VERSION "HNNBNNNYNNNNNNNNNNNNNNNNNNNNNNNNNNNNNNNNNN/4/%%%/4/'%**4NNN///"

NS_ :

BS_:

BU_: BAP_Tester BedienDisp_mi BedienDisp_vo_mi CDI ConMod_CD DashCAM Gateway_Max ICC_IO_Node LSH OCU RDK_RS3 Sound_MIB_ab_Gen3 STH ZR_MIB_EINSTIEG_ab_Gen3 ZR_MIB_OPTION_ab_Gen3 ZR_MIB_TOP_ab_Gen3

BO_ 1529 RDK_02: 8 RDK_RS3
 SG_ RDK_FMVSS138_Lampe : 12|1@1+ (1.0,0.0) [0.0|1] ""  Gateway_Max,OCU
 SG_ RDK_FMVSS138_MIL : 13|1@1+ (1.0,0.0) [0.0|1] ""  Gateway_Max,OCU
 SG_ RDK_Kalibrierung : 14|1@1+ (1.0,0.0) [0.0|1] ""  Gateway_Max,OCU
 SG_ RDK_Reifendruck_Lampe : 15|1@1+ (1.0,0.0) [0.0|1] ""  Gateway_Max
 SG_ RDK_Warnungen_02 : 16|5@1+ (1.0,0.0) [0.0|31] ""  Gateway_Max
 SG_ RDK_angelernt : 22|1@1+ (1.0,0.0) [0.0|1] ""  Gateway_Max
 SG_ RDK_Reifentemperatur_Lampe : 23|1@1+ (1.0,0.0) [0.0|1] ""  Gateway_Max
 SG_ RDK_RS_aktiv : 24|1@1+ (1.0,0.0) [0.0|1] ""  Gateway_Max
 SG_ RDK_Text_7 : 25|1@1+ (1.0,0.0) [0.0|1] ""  Gateway_Max
 SG_ RDK_W_1_Reifen_HL : 56|1@1+ (1.0,0.0) [0.0|1] ""  Gateway_Max
 SG_ RDK_W_1_Reifen_HR : 57|1@1+ (1.0,0.0) [0.0|1] ""  Gateway_Max
 SG_ RDK_W_1_Reifen_VL : 58|1@1+ (1.0,0.0) [0.0|1] ""  Gateway_Max
 SG_ RDK_W_1_Reifen_VR : 59|1@1+ (1.0,0.0) [0.0|1] ""  Gateway_Max
 SG_ RDK_W_2_Reifen_HL : 60|1@1+ (1.0,0.0) [0.0|1] ""  Gateway_Max
 SG_ RDK_W_2_Reifen_HR : 61|1@1+ (1.0,0.0) [0.0|1] ""  Gateway_Max
 SG_ RDK_W_2_Reifen_VL : 62|1@1+ (1.0,0.0) [0.0|1] ""  Gateway_Max
 SG_ RDK_W_2_Reifen_VR : 63|1@1+ (1.0,0.0) [0.0|1] ""  Gateway_Max

BO_ 1711 Rear_View_01: 8 Gateway_Max
 SG_ RV_Video_on : 0|1@1+ (1.0,0.0) [0.0|1] ""  ZR_MIB_EINSTIEG_ab_Gen3,ZR_MIB_TOP_ab_Gen3
 SG_ RV_Dark_Screen : 1|1@1+ (1.0,0.0) [0.0|1] ""  Vector__XXX
 SG_ RV_HMI_Mode : 2|2@1+ (1.0,0.0) [0.0|3] ""  Vector__XXX
 SG_ RV_GL_side : 4|2@1+ (1.0,0.0) [0.0|3] ""  Vector__XXX
 SG_ RV_System_aktiv : 6|1@1+ (1.0,0.0) [0.0|1] ""  Vector__XXX
 SG_ RV_Reinigung_Anf : 7|1@1+ (1.0,0.0) [0.0|1] ""  Vector__XXX
 SG_ RV_Settings_enabled : 8|1@1+ (1.0,0.0) [0.0|1] ""  Vector__XXX
 SG_ RV_Menu_Item : 9|2@1+ (1.0,0.0) [0.0|3] ""  Vector__XXX
 SG_ SV_Video_on : 11|1@1+ (1.0,0.0) [0.0|1] ""  Vector__XXX
 SG_ RV_Calib_Fehler : 12|1@1+ (1.0,0.0) [0.0|1] ""  Vector__XXX
 SG_ RV_GL_Trailer_connect : 13|1@1+ (1.0,0.0) [0.0|1] ""  Vector__XXX
 SG_ RV_GL_Trunk_open : 14|1@1+ (1.0,0.0) [0.0|1] ""  Vector__XXX
 SG_ RV_GL_LWS_Fehler : 15|1@1+ (1.0,0.0) [0.0|1] ""  Vector__XXX
 SG_ RV_Helligkeit : 16|7@1+ (1,0) [0|100] "Unit_PerCent"  Vector__XXX
 SG_ ZFAS_Umfeldbeleuchtung_Anf : 23|1@1+ (1.0,0.0) [0.0|1] ""  Vector__XXX
 SG_ RV_Kontrast : 24|7@1+ (1,0) [0|100] "Unit_PerCent"  Vector__XXX
 SG_ RV_Farbe : 32|7@1+ (1,0) [0|100] "Unit_PerCent"  Vector__XXX

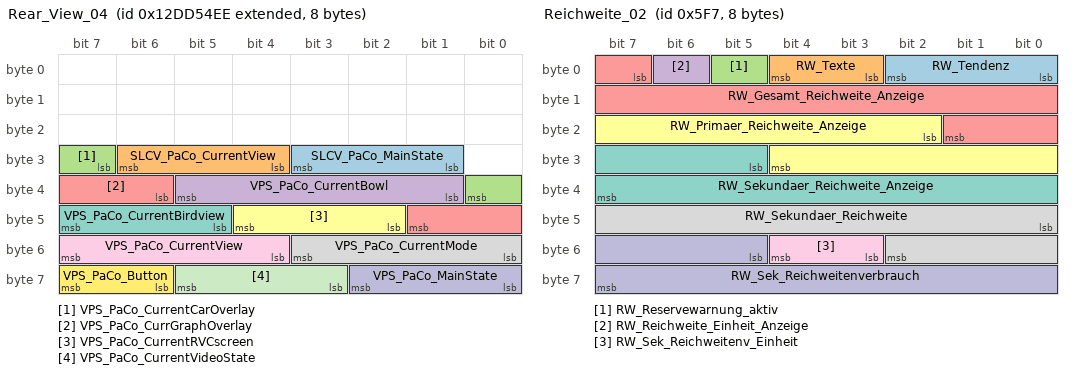
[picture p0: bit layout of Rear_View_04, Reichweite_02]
BO_ 2463978734 Rear_View_04: 8 Gateway_Max
 SG_ SLCV_PaCo_MainState : 25|3@1+ (1.0,0.0) [0.0|7] ""  Vector__XXX
 SG_ SLCV_PaCo_CurrentView : 28|3@1+ (1.0,0.0) [0.0|7] ""  Vector__XXX
 SG_ VPS_PaCo_CurrentCarOverlay : 31|2@1+ (1.0,0.0) [0.0|3] ""  Vector__XXX
 SG_ VPS_PaCo_CurrentBowl : 33|5@1+ (1.0,0.0) [0.0|31] ""  Vector__XXX
 SG_ VPS_PaCo_CurrGraphOverlay : 38|4@1+ (1.0,0.0) [0.0|15] ""  Vector__XXX
 SG_ VPS_PaCo_CurrentRVCscreen : 42|3@1+ (1.0,0.0) [0.0|7] ""  Vector__XXX
 SG_ VPS_PaCo_CurrentBirdview : 45|3@1+ (1.0,0.0) [0.0|7] ""  Vector__XXX
 SG_ VPS_PaCo_CurrentMode : 48|4@1+ (1.0,0.0) [0.0|15] ""  Vector__XXX
 SG_ VPS_PaCo_CurrentView : 52|4@1+ (1.0,0.0) [0.0|15] ""  Vector__XXX
 SG_ VPS_PaCo_MainState : 56|3@1+ (1.0,0.0) [0.0|7] ""  Vector__XXX
 SG_ VPS_PaCo_CurrentVideoState : 59|3@1+ (1.0,0.0) [0.0|7] ""  ZR_MIB_EINSTIEG_ab_Gen3,ZR_MIB_OPTION_ab_Gen3,ZR_MIB_TOP_ab_Gen3
 SG_ VPS_PaCo_Button : 62|2@1+ (1.0,0.0) [0.0|3] ""  Vector__XXX

BO_ 1527 Reichweite_02: 8 Gateway_Max
 SG_ RW_Tendenz : 0|3@1+ (1.0,0.0) [0.0|7] ""  Vector__XXX
 SG_ RW_Texte : 3|2@1+ (1.0,0.0) [0.0|3] ""  OCU
 SG_ RW_Reservewarnung_aktiv : 5|1@1+ (1.0,0.0) [0.0|1] ""  OCU
 SG_ RW_Reichweite_Einheit_Anzeige : 6|1@1+ (1.0,0.0) [0.0|1] ""  OCU
 SG_ RW_Gesamt_Reichweite_Anzeige : 7|11@1+ (1,0) [0|2044] "Unit_None"  OCU
 SG_ RW_Primaer_Reichweite_Anzeige : 18|11@1+ (1,0) [0|2044] "Unit_None"  OCU
 SG_ RW_Sekundaer_Reichweite_Anzeige : 29|11@1+ (1,0) [0|2044] "Unit_None"  OCU
 SG_ RW_Sekundaer_Reichweite : 40|11@1+ (1,0) [0|2044] "Unit_KiloMeter"  OCU
 SG_ RW_Sek_Reichweitenv_Einheit : 51|2@1+ (1.0,0.0) [0.0|3] ""  OCU
 SG_ RW_Sek_Reichweitenverbrauch : 53|11@1+ (0.1,0) [0.0|204.4] "Unit_None"  OCU

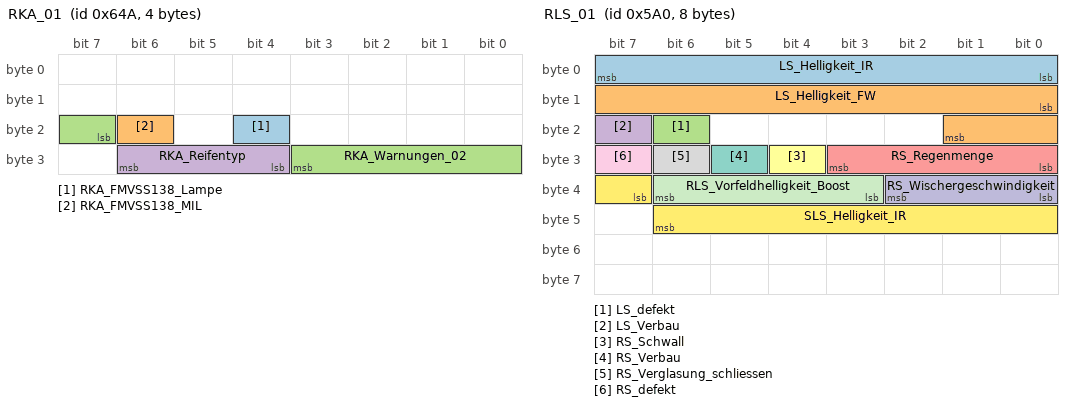
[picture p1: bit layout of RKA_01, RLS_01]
BO_ 1610 RKA_01: 4 Gateway_Max
 SG_ RKA_FMVSS138_Lampe : 20|1@1+ (1.0,0.0) [0.0|1] ""  OCU
 SG_ RKA_FMVSS138_MIL : 22|1@1+ (1,0) [0|1] ""  OCU
 SG_ RKA_Warnungen_02 : 23|5@1+ (1.0,0.0) [0.0|31] ""  OCU
 SG_ RKA_Reifentyp : 28|3@1+ (1.0,0.0) [0.0|7] ""  OCU

BO_ 1440 RLS_01: 8 Gateway_Max
 SG_ LS_Helligkeit_IR : 0|8@1+ (400,0) [0|101200] "Unit_Lux"  OCU
 SG_ LS_Helligkeit_FW : 8|10@1+ (6,0) [0|6126] "Unit_Lux"  OCU
 SG_ LS_defekt : 22|1@1+ (1.0,0.0) [0.0|1] ""  OCU
 SG_ LS_Verbau : 23|1@1+ (1.0,0.0) [0.0|1] ""  OCU
 SG_ RS_Regenmenge : 24|4@1+ (1.0,0.0) [0.0|15] ""  OCU
 SG_ RS_Schwall : 28|1@1+ (1.0,0.0) [0.0|1] ""  OCU
 SG_ RS_Verbau : 29|1@1+ (1.0,0.0) [0.0|1] ""  OCU
 SG_ RS_Verglasung_schliessen : 30|1@1+ (1.0,0.0) [0.0|1] ""  Vector__XXX
 SG_ RS_defekt : 31|1@1+ (1.0,0.0) [0.0|1] ""  OCU
 SG_ RS_Wischergeschwindigkeit : 32|3@1+ (1.0,0.0) [0.0|7] ""  OCU
 SG_ RLS_Vorfeldhelligkeit_Boost : 35|4@1+ (1.0,0.0) [0.0|15] ""  Vector__XXX
 SG_ SLS_Helligkeit_IR : 39|8@1+ (250,0) [0|7000] "Unit_Lux"  Vector__XXX

BO_ 1504 SAD_01: 8 Gateway_Max
 SG_ MD1_Position : 8|7@1+ (1,0) [0|100] "Unit_PerCent"  OCU
 SG_ MD1_Lage : 15|1@1+ (1.0,0.0) [0.0|1] ""  OCU
 SG_ MD3_Position : 16|7@1+ (1,0) [0|100] "Unit_PerCent"  OCU
 SG_ MD3_Lage : 23|1@1+ (1.0,0.0) [0.0|1] ""  OCU
 SG_ MRollo_Position : 24|7@1+ (1,0) [0|100] "Unit_PerCent"  OCU
 SG_ MRollo_Lage : 31|1@1+ (1.0,0.0) [0.0|1] ""  OCU
 SG_ SAD_normiert : 32|1@1+ (1.0,0.0) [0.0|1] ""  Vector__XXX
 SG_ SAD_Thermoschutz : 33|1@1+ (1.0,0.0) [0.0|1] ""  Vector__XXX
 SG_ SAD_UEKB_aktiv : 34|1@1+ (1.0,0.0) [0.0|1] ""  Vector__XXX
 SG_ Rollo_normiert : 35|1@1+ (1.0,0.0) [0.0|1] ""  Vector__XXX
 SG_ Rollo_Thermoschutz : 36|1@1+ (1.0,0.0) [0.0|1] ""  Vector__XXX
 SG_ Rollo_UEKB_aktiv : 37|1@1+ (1.0,0.0) [0.0|1] ""  Vector__XXX
 SG_ SAD_Taster_Deckel_hi : 38|4@1+ (1.0,0.0) [0.0|15] ""  Vector__XXX
 SG_ SAD_Taster_Deckel_vo : 42|4@1+ (1.0,0.0) [0.0|15] ""  Vector__XXX
 SG_ SAD_Taster_Rollo_hi : 46|3@1+ (1.0,0.0) [0.0|7] ""  Vector__XXX
 SG_ SAD_Taster_Rollo_vo : 49|3@1+ (1.0,0.0) [0.0|7] ""  Vector__XXX
 SG_ SAD_Anf_ESC_Zuschaltung : 52|1@1+ (1.0,0.0) [0.0|1] ""  Vector__XXX

BO_ 2463978605 SCode_01: 8 Gateway_Max
 SG_ SCode_Target : 24|8@1+ (1.0,0.0) [0.0|255] ""  Vector__XXX
 SG_ SCode_Data : 32|32@1+ (1.0,0.0) [0.0|4294967295] ""  Vector__XXX

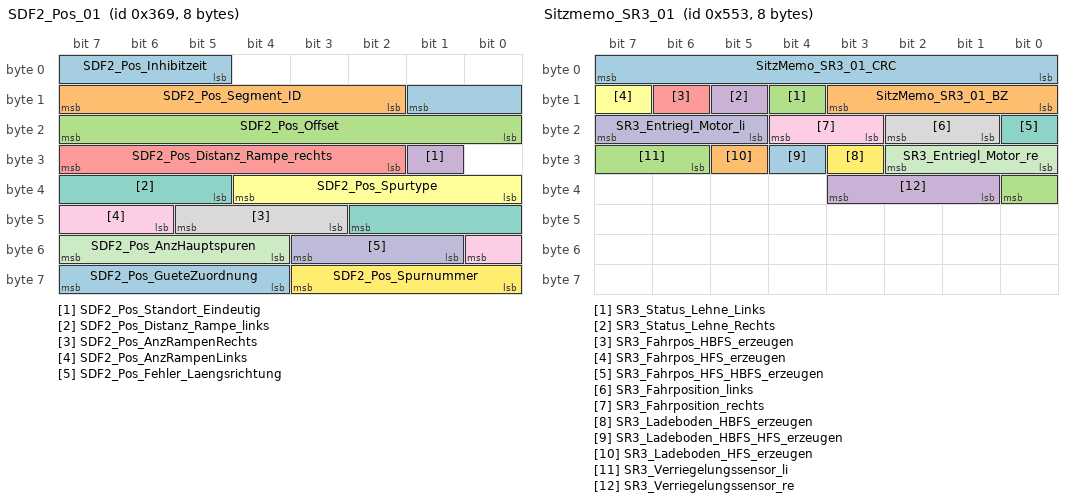
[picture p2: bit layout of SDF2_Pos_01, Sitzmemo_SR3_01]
BO_ 873 SDF2_Pos_01: 8 Gateway_Max
 SG_ SDF2_Pos_Inhibitzeit : 5|5@1+ (10,0) [0|310] "Unit_MilliSecon"  ZR_MIB_TOP_ab_Gen3
 SG_ SDF2_Pos_Segment_ID : 10|6@1+ (1,0) [2|63] ""  ZR_MIB_TOP_ab_Gen3
 SG_ SDF2_Pos_Offset : 16|8@1+ (1,0) [0|254] "Unit_Meter"  ZR_MIB_TOP_ab_Gen3
 SG_ SDF2_Pos_Standort_Eindeutig : 25|1@1+ (1.0,0.0) [0.0|1] ""  ZR_MIB_TOP_ab_Gen3
 SG_ SDF2_Pos_Distanz_Rampe_rechts : 26|6@1+ (16,0) [0|976] "Unit_Meter"  ZR_MIB_TOP_ab_Gen3
 SG_ SDF2_Pos_Spurtype : 32|5@1+ (1.0,0.0) [0.0|31] ""  ZR_MIB_TOP_ab_Gen3
 SG_ SDF2_Pos_Distanz_Rampe_links : 37|6@1+ (16,0) [0|976] "Unit_Meter"  ZR_MIB_TOP_ab_Gen3
 SG_ SDF2_Pos_AnzRampenRechts : 43|3@1+ (1,0) [0|6] ""  ZR_MIB_TOP_ab_Gen3
 SG_ SDF2_Pos_AnzRampenLinks : 46|3@1+ (1,0) [0|6] ""  ZR_MIB_TOP_ab_Gen3
 SG_ SDF2_Pos_Fehler_Laengsrichtung : 49|3@1+ (1.0,0.0) [0.0|7] ""  ZR_MIB_TOP_ab_Gen3
 SG_ SDF2_Pos_AnzHauptspuren : 52|4@1+ (1,0) [0|14] ""  ZR_MIB_TOP_ab_Gen3
 SG_ SDF2_Pos_Spurnummer : 56|4@1+ (1.0,0.0) [0.0|15] ""  ZR_MIB_TOP_ab_Gen3
 SG_ SDF2_Pos_GueteZuordnung : 60|4@1+ (0.0714285714,0) [0E-10|0.9999999996] ""  ZR_MIB_TOP_ab_Gen3

BO_ 1167 Service_Key_01: 8 Gateway_Max
 SG_ SK1_MUX M  : 0|8@1+ (1.0,0.0) [0.0|255] ""  OCU,ZR_MIB_EINSTIEG_ab_Gen3,ZR_MIB_OPTION_ab_Gen3,ZR_MIB_TOP_ab_Gen3
 SG_ SK1_Key_Data_1 m0  : 8|56@1+ (1.0,0.0) [0.0|72057594037927935] ""  OCU,ZR_MIB_EINSTIEG_ab_Gen3,ZR_MIB_OPTION_ab_Gen3,ZR_MIB_TOP_ab_Gen3
 SG_ SK1_Key_Data_2 m1  : 8|56@1+ (1.0,0.0) [0.0|72057594037927935] ""  OCU,ZR_MIB_EINSTIEG_ab_Gen3,ZR_MIB_OPTION_ab_Gen3,ZR_MIB_TOP_ab_Gen3
 SG_ SK1_Key_Data_3 m2  : 8|56@1+ (1.0,0.0) [0.0|72057594037927935] ""  OCU,ZR_MIB_EINSTIEG_ab_Gen3,ZR_MIB_OPTION_ab_Gen3,ZR_MIB_TOP_ab_Gen3
 SG_ SK1_Key_Data_4 m3  : 8|56@1+ (1.0,0.0) [0.0|72057594037927935] ""  OCU,ZR_MIB_EINSTIEG_ab_Gen3,ZR_MIB_OPTION_ab_Gen3,ZR_MIB_TOP_ab_Gen3
 SG_ SK1_Key_Data_5 m4  : 8|56@1+ (1.0,0.0) [0.0|72057594037927935] ""  OCU,ZR_MIB_EINSTIEG_ab_Gen3,ZR_MIB_OPTION_ab_Gen3,ZR_MIB_TOP_ab_Gen3
 SG_ SK1_Key_Data_6 m5  : 8|56@1+ (1.0,0.0) [0.0|72057594037927935] ""  OCU,ZR_MIB_EINSTIEG_ab_Gen3,ZR_MIB_OPTION_ab_Gen3,ZR_MIB_TOP_ab_Gen3
 SG_ SK1_Key_Data_7 m6  : 8|56@1+ (1.0,0.0) [0.0|72057594037927935] ""  OCU,ZR_MIB_EINSTIEG_ab_Gen3,ZR_MIB_OPTION_ab_Gen3,ZR_MIB_TOP_ab_Gen3
 SG_ SK1_Key_Data_8 m7  : 8|56@1+ (1.0,0.0) [0.0|72057594037927935] ""  OCU,ZR_MIB_EINSTIEG_ab_Gen3,ZR_MIB_OPTION_ab_Gen3,ZR_MIB_TOP_ab_Gen3
 SG_ SK1_Key_Data_9 m8  : 8|56@1+ (1.0,0.0) [0.0|72057594037927935] ""  OCU,ZR_MIB_EINSTIEG_ab_Gen3,ZR_MIB_OPTION_ab_Gen3,ZR_MIB_TOP_ab_Gen3
 SG_ SK1_Key_Data_10 m9  : 8|56@1+ (1.0,0.0) [0.0|72057594037927935] ""  Vector__XXX

BO_ 1363 Sitzmemo_SR3_01: 8 Gateway_Max
 SG_ SitzMemo_SR3_01_CRC : 0|8@1+ (1,0) [0|255] ""  Vector__XXX
 SG_ SitzMemo_SR3_01_BZ : 8|4@1+ (1,0) [0|15] ""  Vector__XXX
 SG_ SR3_Status_Lehne_Links : 12|1@1+ (1.0,0.0) [0.0|1] ""  Vector__XXX
 SG_ SR3_Status_Lehne_Rechts : 13|1@1+ (1.0,0.0) [0.0|1] ""  Vector__XXX
 SG_ SR3_Fahrpos_HBFS_erzeugen : 14|1@1+ (1.0,0.0) [0.0|1] ""  Vector__XXX
 SG_ SR3_Fahrpos_HFS_erzeugen : 15|1@1+ (1.0,0.0) [0.0|1] ""  Vector__XXX
 SG_ SR3_Fahrpos_HFS_HBFS_erzeugen : 16|1@1+ (1.0,0.0) [0.0|1] ""  Vector__XXX
 SG_ SR3_Fahrposition_links : 17|2@1+ (1.0,0.0) [0.0|3] ""  Vector__XXX
 SG_ SR3_Fahrposition_rechts : 19|2@1+ (1.0,0.0) [0.0|3] ""  Vector__XXX
 SG_ SR3_Entriegl_Motor_li : 21|3@1+ (1.0,0.0) [0.0|7] ""  Vector__XXX
 SG_ SR3_Entriegl_Motor_re : 24|3@1+ (1.0,0.0) [0.0|7] ""  Vector__XXX
 SG_ SR3_Ladeboden_HBFS_erzeugen : 27|1@1+ (1.0,0.0) [0.0|1] ""  Vector__XXX
 SG_ SR3_Ladeboden_HBFS_HFS_erzeugen : 28|1@1+ (1.0,0.0) [0.0|1] ""  Vector__XXX
 SG_ SR3_Ladeboden_HFS_erzeugen : 29|1@1+ (1.0,0.0) [0.0|1] ""  Vector__XXX
 SG_ SR3_Verriegelungssensor_li : 30|3@1+ (1.0,0.0) [0.0|7] ""  BedienDisp_mi
 SG_ SR3_Verriegelungssensor_re : 33|3@1+ (1.0,0.0) [0.0|7] ""  BedienDisp_mi

BO_ 980 SMLS_01: 8 Gateway_Max
 SG_ SMLS_01_CRC : 0|8@1+ (1,0) [0|255] ""  Vector__XXX
 SG_ SMLS_01_BZ : 8|4@1+ (1,0) [0|15] ""  Vector__XXX
 SG_ BH_Blinker_li : 12|1@1+ (1.0,0.0) [0.0|1] ""  OCU,ZR_MIB_EINSTIEG_ab_Gen3,ZR_MIB_OPTION_ab_Gen3,ZR_MIB_TOP_ab_Gen3
 SG_ BH_Blinker_re : 13|1@1+ (1.0,0.0) [0.0|1] ""  OCU,ZR_MIB_EINSTIEG_ab_Gen3,ZR_MIB_OPTION_ab_Gen3,ZR_MIB_TOP_ab_Gen3
 SG_ BH_Lichthupe : 14|1@1+ (1.0,0.0) [0.0|1] ""  OCU
 SG_ BH_Fernlicht : 15|1@1+ (1.0,0.0) [0.0|1] ""  OCU
 SG_ WH_Tipwischen : 16|1@1+ (1.0,0.0) [0.0|1] ""  OCU
 SG_ WH_Intervall : 17|1@1+ (1.0,0.0) [0.0|1] ""  OCU
 SG_ WH_WischerStufe1 : 18|1@1+ (1.0,0.0) [0.0|1] ""  OCU
 SG_ WH_WischerStufe2 : 19|1@1+ (1.0,0.0) [0.0|1] ""  OCU
 SG_ WH_Frontwaschen : 20|1@1+ (1.0,0.0) [0.0|1] ""  OCU
 SG_ WH_Heckintervall : 21|1@1+ (1.0,0.0) [0.0|1] ""  OCU
 SG_ WH_Heckwaschen : 22|1@1+ (1.0,0.0) [0.0|1] ""  OCU
 SG_ WH_Intervallstufen : 23|4@1+ (1.0,0.0) [0.0|15] ""  OCU
 SG_ FAS_Taster : 27|1@1+ (1.0,0.0) [0.0|1] ""  Vector__XXX
 SG_ FAS_Taster_Fehler : 28|1@1+ (1.0,0.0) [0.0|1] ""  Vector__XXX
 SG_ SMLS_Hupe : 29|1@1+ (1.0,0.0) [0.0|1] ""  OCU
 SG_ LRH_On_Off : 30|2@1+ (1.0,0.0) [0.0|3] ""  Vector__XXX
 SG_ LSS_Tastencode : 32|8@1+ (1.0,0.0) [0.0|255] ""  Vector__XXX
 SG_ LRH_aktiv : 40|1@1+ (1.0,0.0) [0.0|1] ""  Vector__XXX
 SG_ SMLS_P_verriegelt : 41|2@1+ (1.0,0.0) [0.0|3] ""  Vector__XXX
 SG_ SMLS_P_verriegelt_plausibel : 43|1@1+ (1.0,0.0) [0.0|1] ""  Vector__XXX
 SG_ WH_SRA : 44|1@1+ (1.0,0.0) [0.0|1] ""  Vector__XXX
 SG_ WH_Wischer_Fehler : 45|1@1+ (1.0,0.0) [0.0|1] ""  Vector__XXX
 SG_ BH_Blinker_Fehler : 46|1@1+ (1.0,0.0) [0.0|1] ""  Vector__XXX
 SG_ SMLS_PTT : 47|1@1+ (1.0,0.0) [0.0|1] ""  Vector__XXX
 SG_ WH_Tipwischen_lang : 48|1@1+ (1.0,0.0) [0.0|1] ""  Vector__XXX

BO_ 2464161907 SOK_FoD_Info_El_Req_Chal_04: 8 ICC_IO_Node
 SG_ SOK_FoD_Info_El_Req_Challenge : 0|64@1+ (1,0) [0|18446744073709551615] "Unit_None"  Gateway_Max

BO_ 2464301171 SOK_FoD_Info_El_Resp_Chal_04: 8 Gateway_Max
 SG_ SOK_FoD_Info_El_Resp_Challenge : 0|64@1+ (1,0) [0|18446744073709551615] "Unit_None"  ICC_IO_Node,ZR_MIB_OPTION_ab_Gen3

BO_ 2589283756 SOK_NoAuthenticTime_01: 8 Gateway_Max
 SG_ SOK_ungeschuetzte_Zeit : 8|56@1+ (1,0) [1|72057594037927935] "Unit_None"  ICC_IO_Node,OCU,ZR_MIB_EINSTIEG_ab_Gen3,ZR_MIB_OPTION_ab_Gen3,ZR_MIB_TOP_ab_Gen3

BO_ 2464153703 SOK_Zeit_eCall_Chal_01: 8 OCU
 SG_ SOK_Zeit_OCU_Challenge : 0|64@1+ (1,0) [0|18446744073709551615] "Unit_None"  Gateway_Max

BO_ 2464284775 SOK_Zeit_eCall_Signatur_Resp_01: 8 Gateway_Max
 SG_ SOK_Zeit_OCU_Signatur : 0|64@1+ (1,0) [0|18446744073709551615] ""  OCU

BO_ 2464288871 SOK_Zeit_eCall_Zeit_Resp_01: 8 Gateway_Max
 SG_ SOK_Zeit_OCU_Zeit : 0|56@1+ (1,0) [0|72057594037927935] "Unit_None"  OCU

BO_ 2464153715 SOK_Zeit_Info_El_Chal_01: 8 ICC_IO_Node
 SG_ SOK_Zeit_Info_El_Challenge : 0|64@1+ (1,0) [0|18446744073709551615] "Unit_None"  Gateway_Max

BO_ 2464288883 SOK_Zeit_Info_El_Signatur_Res000: 8 Gateway_Max
 SG_ SOK_Zeit_Info_El_Signatur : 0|64@1- (1,0) [0|18446744073709551615] "Unit_None"  ICC_IO_Node,ZR_MIB_EINSTIEG_ab_Gen3,ZR_MIB_OPTION_ab_Gen3,ZR_MIB_TOP_ab_Gen3

BO_ 2464292979 SOK_Zeit_Info_El_Zeit_Resp_02: 8 Gateway_Max
 SG_ SOK_Zeit_Info_El_Zeit : 0|56@1+ (1,0) [0|72057594037927935] "Unit_None"  ICC_IO_Node,ZR_MIB_EINSTIEG_ab_Gen3,ZR_MIB_OPTION_ab_Gen3,ZR_MIB_TOP_ab_Gen3

BO_ 1467 SoSe_01: 8 Gateway_Max
 SG_ SoSe_SunInt_2D_Li : 0|8@1+ (5,0) [0|1200] "Unit_WattPerMeterSquar"  OCU
 SG_ SoSe_SunInt_2D_Re : 8|8@1+ (5,0) [0|1200] "Unit_WattPerMeterSquar"  OCU

BO_ 1313 STH_01: 8 STH
 SG_ STH_Funk_ein : 0|1@1+ (1.0,0.0) [0.0|1] ""  Gateway_Max
 SG_ STH_Funk_aus : 1|1@1+ (1.0,0.0) [0.0|1] ""  Gateway_Max
 SG_ STH_Zusatzheizung : 2|1@1+ (1.0,0.0) [0.0|1] ""  Gateway_Max,LSH
 SG_ STH_LED : 3|1@1+ (1.0,0.0) [0.0|1] ""  Gateway_Max,LSH
 SG_ STH_Pumpe_ein : 4|1@1+ (1,0) [0|1] ""  Gateway_Max
 SG_ STH_Geblaese : 5|1@1+ (1.0,0.0) [0.0|1] ""  Gateway_Max
 SG_ STH_EKP_Anst : 6|1@1+ (1.0,0.0) [0.0|1] ""  Gateway_Max,LSH
 SG_ STH_Start_folgt : 7|1@1+ (1.0,0.0) [0.0|1] ""  Gateway_Max
 SG_ STH_Ventiloeffnungszeit : 8|6@1+ (1,0) [0|63] "Unit_Minut"  Gateway_Max
 SG_ STH_Ventil_Status : 14|1@1+ (1.0,0.0) [0.0|1] ""  Gateway_Max
 SG_ STH_Fehler_ElWaPu : 15|1@1+ (1.0,0.0) [0.0|1] ""  Gateway_Max
 SG_ STH_Waermeeintrag : 16|6@1+ (1,0) [0|63] "Unit_None"  Gateway_Max
 SG_ STH_Pumpen_Anf_extern : 22|1@1+ (1.0,0.0) [0.0|1] ""  Gateway_Max
 SG_ STH_KL_HUP : 23|1@1+ (1.0,0.0) [0.0|1] ""  Gateway_Max
 SG_ STH_KVS : 24|13@1+ (1,0) [0|8191] "Unit_MilliLiter"  Gateway_Max,OCU
 SG_ STH_Fehlerstatus : 37|3@1+ (1.0,0.0) [0.0|7] ""  Gateway_Max,LSH
 SG_ STH_Heizleistung : 40|8@1+ (1,0) [0|255] ""  Gateway_Max,LSH
 SG_ STH_Wassertemp : 48|8@1+ (0.75,-40) [-40.00|142.25] "Unit_DegreCelsi"  Gateway_Max
 SG_ STH_Texte : 56|3@1+ (1.0,0.0) [0.0|7] ""  Gateway_Max
 SG_ STH_Motorvorwaermung : 59|1@1+ (1.0,0.0) [0.0|1] ""  Gateway_Max
 SG_ STH_Servicemode : 60|1@1+ (1.0,0.0) [0.0|1] ""  Gateway_Max
 SG_ STH_war_aktiv : 61|1@1+ (1.0,0.0) [0.0|1] ""  Gateway_Max
 SG_ STH_KVS_Ueberlauf : 62|1@1+ (1.0,0.0) [0.0|1] ""  Gateway_Max,OCU
 SG_ STH_SH_ZH : 63|1@1+ (1.0,0.0) [0.0|1] ""  Gateway_Max

BO_ 673 SWA_02: 8 Gateway_Max
 SG_ SWA_LED_Hell_BFS : 12|7@1+ (1,0) [0|100] "Unit_PerCent"  Vector__XXX
 SG_ SWA_LED_Hell_FS : 19|7@1+ (1,0) [0|100] "Unit_PerCent"  Vector__XXX
 SG_ SWA_LED_Ausgabemodus_BFS : 26|3@1+ (1.0,0.0) [0.0|7] ""  Vector__XXX
 SG_ SWA_LED_Ausgabemodus_FS : 29|3@1+ (1.0,0.0) [0.0|7] ""  Vector__XXX
 SG_ SWA_Status : 32|2@1+ (1.0,0.0) [0.0|3] ""  OCU
 SG_ ASW_Ton_Richtung_VL : 34|1@1+ (1.0,0.0) [0.0|1] ""  ZR_MIB_EINSTIEG_ab_Gen3,ZR_MIB_OPTION_ab_Gen3,ZR_MIB_TOP_ab_Gen3
 SG_ ASW_Ton_Richtung_VR : 35|1@1+ (1.0,0.0) [0.0|1] ""  ZR_MIB_EINSTIEG_ab_Gen3,ZR_MIB_OPTION_ab_Gen3,ZR_MIB_TOP_ab_Gen3
 SG_ ASW_Ton_Richtung_HL : 36|1@1+ (1.0,0.0) [0.0|1] ""  ZR_MIB_EINSTIEG_ab_Gen3,ZR_MIB_OPTION_ab_Gen3,ZR_MIB_TOP_ab_Gen3
 SG_ ASW_Ton_Richtung_HR : 37|1@1+ (1.0,0.0) [0.0|1] ""  ZR_MIB_EINSTIEG_ab_Gen3,ZR_MIB_OPTION_ab_Gen3,ZR_MIB_TOP_ab_Gen3
 SG_ SWA_Status_System : 38|2@1+ (1.0,0.0) [0.0|3] ""  Vector__XXX
 SG_ SWA_Brightness_Mode_FPM : 40|4@1+ (1.0,0.0) [0.0|15] ""  Vector__XXX
 SG_ SWA_Status_KuFu : 44|2@1+ (1.0,0.0) [0.0|3] ""  Vector__XXX
 SG_ SWA_Infostufe_Assist_li : 46|1@1+ (1.0,0.0) [0.0|1] ""  Vector__XXX
 SG_ SWA_Infostufe_Assist_re : 47|1@1+ (1.0,0.0) [0.0|1] ""  Vector__XXX
 SG_ SWA_Warnstufe_Assist_li : 48|1@1+ (1.0,0.0) [0.0|1] ""  Vector__XXX
 SG_ SWA_Warnstufe_Assist_re : 49|1@1+ (1.0,0.0) [0.0|1] ""  Vector__XXX
 SG_ SWA_Modus_System : 50|3@1+ (1.0,0.0) [0.0|7] ""  Vector__XXX
 SG_ SWA_Kombiausgabe : 53|3@1+ (1.0,0.0) [0.0|7] ""  Vector__XXX
 SG_ ASW_Kombiausgabe : 56|3@1+ (1.0,0.0) [0.0|7] ""  Vector__XXX
 SG_ SWA_Kombiwarnung : 59|1@1+ (1.0,0.0) [0.0|1] ""  Vector__XXX

BO_ 1413 Systeminfo_01: 8 Gateway_Max
 SG_ SI_Sammel_SG_Fehler : 0|6@1+ (1,0) [0|60] ""  ICC_IO_Node,ZR_MIB_EINSTIEG_ab_Gen3,ZR_MIB_OPTION_ab_Gen3,ZR_MIB_TOP_ab_Gen3
 SG_ SI_P_Mode_gueltig : 6|1@1+ (1.0,0.0) [0.0|1] ""  BedienDisp_vo_mi,ConMod_CD,ICC_IO_Node,OCU,ZR_MIB_EINSTIEG_ab_Gen3,ZR_MIB_OPTION_ab_Gen3,ZR_MIB_TOP_ab_Gen3
 SG_ SI_Diagnose_Aktiv : 7|1@1+ (1.0,0.0) [0.0|1] ""  ICC_IO_Node,ZR_MIB_EINSTIEG_ab_Gen3,ZR_MIB_OPTION_ab_Gen3,ZR_MIB_TOP_ab_Gen3
 SG_ SI_QRS_Mode : 8|1@1+ (1.0,0.0) [0.0|1] ""  BedienDisp_mi,BedienDisp_vo_mi,CDI,ConMod_CD,DashCAM,ICC_IO_Node,LSH,OCU,RDK_RS3,STH,ZR_MIB_EINSTIEG_ab_Gen3,ZR_MIB_OPTION_ab_Gen3,ZR_MIB_TOP_ab_Gen3
 SG_ SI_T_Mode : 9|1@1+ (1.0,0.0) [0.0|1] ""  BedienDisp_mi,BedienDisp_vo_mi,CDI,ConMod_CD,DashCAM,ICC_IO_Node,OCU,RDK_RS3,ZR_MIB_EINSTIEG_ab_Gen3,ZR_MIB_OPTION_ab_Gen3,ZR_MIB_TOP_ab_Gen3
 SG_ SI_NWDF : 10|1@1+ (1.0,0.0) [0.0|1] ""  BedienDisp_mi,BedienDisp_vo_mi,ConMod_CD,DashCAM,ICC_IO_Node,LSH,OCU,RDK_RS3,STH,ZR_MIB_EINSTIEG_ab_Gen3,ZR_MIB_OPTION_ab_Gen3,ZR_MIB_TOP_ab_Gen3
 SG_ SI_NWDF_gueltig : 11|1@1+ (1.0,0.0) [0.0|1] ""  BedienDisp_mi,BedienDisp_vo_mi,ConMod_CD,DashCAM,ICC_IO_Node,LSH,OCU,RDK_RS3,STH,ZR_MIB_EINSTIEG_ab_Gen3,ZR_MIB_OPTION_ab_Gen3,ZR_MIB_TOP_ab_Gen3
 SG_ SI_Sammelfehler : 12|1@1+ (1.0,0.0) [0.0|1] ""  ICC_IO_Node,ZR_MIB_EINSTIEG_ab_Gen3,ZR_MIB_OPTION_ab_Gen3,ZR_MIB_TOP_ab_Gen3
 SG_ GW_KD_Fehler : 13|1@1+ (1.0,0.0) [0.0|1] ""  ICC_IO_Node,ZR_MIB_EINSTIEG_ab_Gen3,ZR_MIB_OPTION_ab_Gen3,ZR_MIB_TOP_ab_Gen3
 SG_ SI_T_Schutz : 14|1@1+ (1.0,0.0) [0.0|1] ""  BedienDisp_mi,BedienDisp_vo_mi,ConMod_CD,DashCAM,ICC_IO_Node,LSH,OCU,STH,ZR_MIB_EINSTIEG_ab_Gen3,ZR_MIB_OPTION_ab_Gen3,ZR_MIB_TOP_ab_Gen3
 SG_ SI_P_Mode : 15|1@1+ (1.0,0.0) [0.0|1] ""  BedienDisp_vo_mi,CDI,ConMod_CD,ICC_IO_Node,OCU,ZR_MIB_EINSTIEG_ab_Gen3,ZR_MIB_OPTION_ab_Gen3,ZR_MIB_TOP_ab_Gen3
 SG_ SI_BUS_01 : 16|1@1+ (1.0,0.0) [0.0|1] ""  ICC_IO_Node,LSH,STH,ZR_MIB_EINSTIEG_ab_Gen3,ZR_MIB_OPTION_ab_Gen3,ZR_MIB_TOP_ab_Gen3
 SG_ SI_BUS_02 : 17|1@1+ (1.0,0.0) [0.0|1] ""  ICC_IO_Node,ZR_MIB_EINSTIEG_ab_Gen3,ZR_MIB_OPTION_ab_Gen3,ZR_MIB_TOP_ab_Gen3
 SG_ SI_BUS_03 : 18|1@1+ (1.0,0.0) [0.0|1] ""  ICC_IO_Node,LSH,STH,ZR_MIB_EINSTIEG_ab_Gen3,ZR_MIB_OPTION_ab_Gen3,ZR_MIB_TOP_ab_Gen3
 SG_ SI_BUS_04 : 19|1@1+ (1.0,0.0) [0.0|1] ""  ICC_IO_Node,ZR_MIB_EINSTIEG_ab_Gen3,ZR_MIB_OPTION_ab_Gen3,ZR_MIB_TOP_ab_Gen3
 SG_ SI_BUS_05 : 20|1@1+ (1.0,0.0) [0.0|1] ""  ICC_IO_Node,ZR_MIB_EINSTIEG_ab_Gen3,ZR_MIB_OPTION_ab_Gen3,ZR_MIB_TOP_ab_Gen3
 SG_ SI_BUS_06 : 21|1@1+ (1.0,0.0) [0.0|1] ""  ICC_IO_Node,ZR_MIB_EINSTIEG_ab_Gen3,ZR_MIB_OPTION_ab_Gen3,ZR_MIB_TOP_ab_Gen3
 SG_ SI_BUS_07 : 22|1@1+ (1.0,0.0) [0.0|1] ""  ICC_IO_Node,ZR_MIB_EINSTIEG_ab_Gen3,ZR_MIB_OPTION_ab_Gen3,ZR_MIB_TOP_ab_Gen3
 SG_ SI_BUS_08 : 23|1@1+ (1.0,0.0) [0.0|1] ""  ICC_IO_Node,ZR_MIB_EINSTIEG_ab_Gen3,ZR_MIB_OPTION_ab_Gen3,ZR_MIB_TOP_ab_Gen3
 SG_ SI_BUS_09 : 24|1@1+ (1.0,0.0) [0.0|1] ""  ICC_IO_Node,ZR_MIB_EINSTIEG_ab_Gen3,ZR_MIB_OPTION_ab_Gen3,ZR_MIB_TOP_ab_Gen3
 SG_ SI_BUS_10 : 25|1@1+ (1.0,0.0) [0.0|1] ""  ICC_IO_Node,ZR_MIB_EINSTIEG_ab_Gen3,ZR_MIB_OPTION_ab_Gen3,ZR_MIB_TOP_ab_Gen3
 SG_ SI_BUS_11 : 26|1@1+ (1.0,0.0) [0.0|1] ""  ICC_IO_Node,ZR_MIB_EINSTIEG_ab_Gen3,ZR_MIB_OPTION_ab_Gen3,ZR_MIB_TOP_ab_Gen3
 SG_ SI_BUS_12 : 27|1@1+ (1.0,0.0) [0.0|1] ""  ICC_IO_Node,ZR_MIB_EINSTIEG_ab_Gen3,ZR_MIB_OPTION_ab_Gen3,ZR_MIB_TOP_ab_Gen3
 SG_ SI_BUS_13 : 28|1@1+ (1.0,0.0) [0.0|1] ""  ICC_IO_Node,ZR_MIB_EINSTIEG_ab_Gen3,ZR_MIB_OPTION_ab_Gen3,ZR_MIB_TOP_ab_Gen3
 SG_ SI_BUS_14 : 29|1@1+ (1.0,0.0) [0.0|1] ""  ICC_IO_Node,ZR_MIB_EINSTIEG_ab_Gen3,ZR_MIB_OPTION_ab_Gen3,ZR_MIB_TOP_ab_Gen3
 SG_ SI_BUS_15 : 30|1@1+ (1.0,0.0) [0.0|1] ""  ICC_IO_Node,ZR_MIB_EINSTIEG_ab_Gen3,ZR_MIB_OPTION_ab_Gen3,ZR_MIB_TOP_ab_Gen3
 SG_ SI_NWDF_30 : 31|1@1+ (1.0,0.0) [0.0|1] ""  ICC_IO_Node,ZR_MIB_EINSTIEG_ab_Gen3,ZR_MIB_OPTION_ab_Gen3,ZR_MIB_TOP_ab_Gen3
 SG_ SI_Bus_Identifikation : 32|8@1+ (1.0,0.0) [0.0|255] ""  ICC_IO_Node,ZR_MIB_EINSTIEG_ab_Gen3,ZR_MIB_OPTION_ab_Gen3,ZR_MIB_TOP_ab_Gen3
 SG_ SI_CAB_V14 : 40|24@1+ (1.0,0.0) [0.0|16777215] ""  ICC_IO_Node,ZR_MIB_EINSTIEG_ab_Gen3,ZR_MIB_OPTION_ab_Gen3,ZR_MIB_TOP_ab_Gen3

BO_ 1637 Telefon_01: 7 Gateway_Max
 SG_ TF_Phone_on : 0|1@1+ (1,0) [0|1] ""  Gateway_Max
 SG_ TF_Phone_mute : 2|1@1+ (1,0) [0|1] ""  Gateway_Max
 SG_ TF_Phone_active_call : 3|1@1+ (1,0) [0|1] ""  Gateway_Max
 SG_ TF_Phone_ring : 4|1@1+ (1,0) [0|1] ""  Gateway_Max
 SG_ TF_Phone_SIM_ok : 5|1@1+ (1,0) [0|1] ""  Gateway_Max
 SG_ TF_Phone_PIN_ok : 6|1@1+ (1,0) [0|1] ""  Gateway_Max
 SG_ TF_Phone_Error_Flag : 7|1@1+ (1,0) [0|1] ""  Gateway_Max
 SG_ TF_Telephone_State : 12|3@1+ (1.0,0.0) [0.0|7] ""  Gateway_Max
 SG_ TF_Phone_init : 15|1@1+ (1,0) [0|1] ""  Gateway_Max
 SG_ TF_Mute_Msg_Code : 16|3@1+ (1.0,0.0) [0.0|7] ""  Gateway_Max
 SG_ TF_Phone_Status : 19|3@1+ (1.0,0.0) [0.0|7] ""  Gateway_Max
 SG_ TF_BT_ConnectionState : 22|1@1+ (1.0,0.0) [0.0|1] ""  Gateway_Max
 SG_ TF_Phone_Provider : 24|12@1+ (1,0) [0|4095] ""  Gateway_Max
 SG_ TF_Phone_FieldStrength : 36|4@1+ (1,0) [0|15] ""  Gateway_Max
 SG_ TF_Phone_CountryCode : 40|12@1+ (1,0) [0|4095] ""  Gateway_Max
 SG_ TF_Phone_err_fieldstrength : 52|1@1+ (1,0) [0|1] ""  Gateway_Max
 SG_ TF_Phone_RegistrationState : 53|3@1+ (1,0) [0|7] ""  Gateway_Max

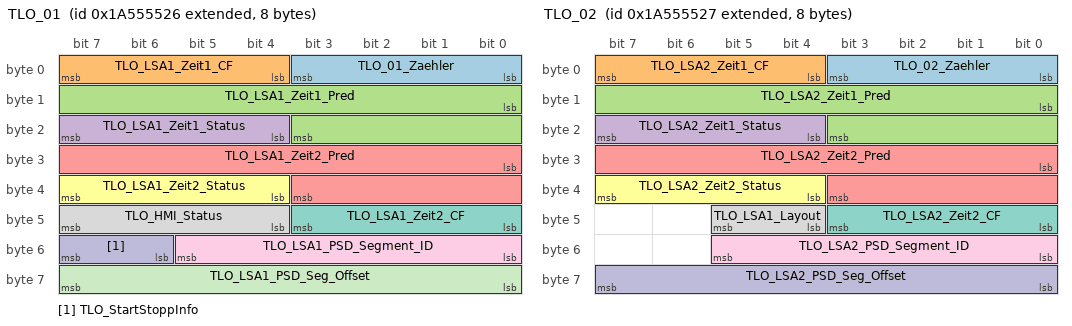
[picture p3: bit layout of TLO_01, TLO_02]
BO_ 2589283622 TLO_01: 8 ZR_MIB_TOP_ab_Gen3
 SG_ TLO_01_Zaehler : 0|4@1+ (1,0) [0|15] ""  Gateway_Max
 SG_ TLO_LSA1_Zeit1_CF : 4|4@1+ (1,0) [0|15] "Unit_None"  Gateway_Max
 SG_ TLO_LSA1_Zeit1_Pred : 8|12@1+ (0.1,-0.1) [0.0|409.4] "Unit_Secon"  Gateway_Max
 SG_ TLO_LSA1_Zeit1_Status : 20|4@1+ (1.0,0.0) [0.0|15] ""  Gateway_Max
 SG_ TLO_LSA1_Zeit2_Pred : 24|12@1+ (0.1,-0.1) [0.0|409.4] "Unit_Secon"  Gateway_Max
 SG_ TLO_LSA1_Zeit2_Status : 36|4@1+ (1.0,0.0) [0.0|15] ""  Gateway_Max
 SG_ TLO_LSA1_Zeit2_CF : 40|4@1+ (1,0) [0|15] "Unit_None"  Gateway_Max
 SG_ TLO_HMI_Status : 44|4@1+ (1.0,0.0) [0.0|15] ""  Gateway_Max
 SG_ TLO_LSA1_PSD_Segment_ID : 48|6@1+ (1,0) [2|63] "Unit_None"  Gateway_Max
 SG_ TLO_StartStoppInfo : 54|2@1+ (1.0,0.0) [0.0|3] ""  Gateway_Max
 SG_ TLO_LSA1_PSD_Seg_Offset : 56|8@1+ (1,0) [0|254] "Unit_Meter"  Gateway_Max

BO_ 2589283623 TLO_02: 8 ZR_MIB_TOP_ab_Gen3
 SG_ TLO_02_Zaehler : 0|4@1+ (1,0) [0|15] ""  Gateway_Max
 SG_ TLO_LSA2_Zeit1_CF : 4|4@1+ (1,0) [0|15] "Unit_None"  Gateway_Max
 SG_ TLO_LSA2_Zeit1_Pred : 8|12@1+ (0.1,-0.1) [0.0|409.4] "Unit_Secon"  Gateway_Max
 SG_ TLO_LSA2_Zeit1_Status : 20|4@1+ (1.0,0.0) [0.0|15] ""  Gateway_Max
 SG_ TLO_LSA2_Zeit2_Pred : 24|12@1+ (0.1,-0.1) [0.0|409.4] "Unit_Secon"  Gateway_Max
 SG_ TLO_LSA2_Zeit2_Status : 36|4@1+ (1.0,0.0) [0.0|15] ""  Gateway_Max
 SG_ TLO_LSA2_Zeit2_CF : 40|4@1+ (1,0) [0|15] "Unit_None"  Gateway_Max
 SG_ TLO_LSA1_Layout : 44|2@1+ (1.0,0.0) [0.0|3] ""  Gateway_Max
 SG_ TLO_LSA2_PSD_Segment_ID : 48|6@1+ (1,0) [2|63] "Unit_None"  Gateway_Max
 SG_ TLO_LSA2_PSD_Seg_Offset : 56|8@1+ (1,0) [0|254] "Unit_Meter"  Gateway_Max

BO_ 1447 TM_01: 8 OCU
 SG_ ORU_KombiTimer : 20|2@1+ (1.0,0.0) [0.0|3] ""  Gateway_Max
 SG_ MOD_Energie_Anf : 22|2@1+ (1.0,0.0) [0.0|3] ""  Gateway_Max
 SG_ FaceRec_Enroll_Challenge_Request : 24|1@1+ (1.0,0.0) [0.0|1] ""  Gateway_Max
 SG_ eCall_Mute_Anf : 25|1@1+ (1.0,0.0) [0.0|1] ""  Gateway_Max
 SG_ eCall_MCC : 26|10@1+ (1,0) [0|999] "Unit_None"  Gateway_Max
 SG_ FoD_Anz_Funktionsabschaltung : 36|2@1+ (1.0,0.0) [0.0|3] ""  Gateway_Max
 SG_ iCall_active : 38|1@1+ (1.0,0.0) [0.0|1] ""  Gateway_Max
 SG_ bCall_active : 39|1@1+ (1.0,0.0) [0.0|1] ""  Gateway_Max
 SG_ MOD_Request_ServiceKey : 40|1@1+ (1.0,0.0) [0.0|1] ""  Gateway_Max
 SG_ eCall_Funktionsstatus_02 : 41|3@1+ (1.0,0.0) [0.0|7] ""  Gateway_Max
 SG_ eCall_Funktionsstatus : 44|3@1+ (1.0,0.0) [0.0|7] ""  Gateway_Max
 SG_ TM_Spiegel_Anklappen : 47|1@1+ (1.0,0.0) [0.0|1] ""  Gateway_Max
 SG_ TM_Nur_Hupen : 48|1@1+ (1.0,0.0) [0.0|1] ""  Gateway_Max
 SG_ TM_Door_Lock : 49|1@1+ (1.0,0.0) [0.0|1] ""  Gateway_Max
 SG_ TM_Door_Unlock : 50|1@1+ (1.0,0.0) [0.0|1] ""  Gateway_Max
 SG_ TM_Warnblinken : 51|1@1+ (1.0,0.0) [0.0|1] ""  Gateway_Max
 SG_ TM_Panik_Alarm : 52|1@1+ (1.0,0.0) [0.0|1] ""  Gateway_Max
 SG_ TM_ZV_Signatur : 53|11@1+ (1,0) [1|2047] "Unit_None"  Gateway_Max

BO_ 977 TSG_BT_01: 8 Gateway_Max
 SG_ BT_Tuer_geoeffnet : 0|1@1+ (1.0,0.0) [0.0|1] ""  OCU,ZR_MIB_TOP_ab_Gen3
 SG_ BT_verriegelt : 1|1@1+ (1.0,0.0) [0.0|1] ""  OCU
 SG_ BT_gesafet : 2|1@1+ (1.0,0.0) [0.0|1] ""  OCU
 SG_ BT_Schluesselschalter_auf : 3|1@1+ (1.0,0.0) [0.0|1] ""  Vector__XXX
 SG_ BT_Schluesselschalter_zu : 4|1@1+ (1.0,0.0) [0.0|1] ""  Vector__XXX
 SG_ BT_Unlock_Taster : 5|1@1+ (1.0,0.0) [0.0|1] ""  Vector__XXX
 SG_ BT_Lock_Taster : 6|1@1+ (1.0,0.0) [0.0|1] ""  Vector__XXX
 SG_ BT_Sperrklinke : 7|1@1+ (1.0,0.0) [0.0|1] ""  Vector__XXX
 SG_ BT_TAG_betaetigt : 8|1@1+ (1.0,0.0) [0.0|1] ""  Vector__XXX
 SG_ BT_TIG_betaetigt : 9|1@1+ (1.0,0.0) [0.0|1] ""  Vector__XXX
 SG_ BT_EC_Spiegel_Helligkeit : 10|5@1+ (3.125,0) [0.000|96.875] "Unit_PerCent"  Vector__XXX
 SG_ BT_Sp_Heizung_Anf : 15|1@1+ (100,0) [0|100] "Unit_PerCent"  Vector__XXX
 SG_ BT_Tuer_Status : 16|2@1+ (1.0,0.0) [0.0|3] ""  OCU
 SG_ BT_TSG_hinten_verbaut : 18|1@1+ (1.0,0.0) [0.0|1] ""  Vector__XXX
 SG_ BT_Sp_Blk_def : 19|1@1+ (1.0,0.0) [0.0|1] ""  Vector__XXX
 SG_ BT_FH_S_ManHoch : 20|1@1+ (1.0,0.0) [0.0|1] ""  Vector__XXX
 SG_ BT_FH_S_AutoHoch : 21|1@1+ (1.0,0.0) [0.0|1] ""  Vector__XXX
 SG_ BT_FH_S_ManTief : 22|1@1+ (1.0,0.0) [0.0|1] ""  Vector__XXX
 SG_ BT_FH_S_AutoTief : 23|1@1+ (1.0,0.0) [0.0|1] ""  Vector__XXX
 SG_ BT_FH_Oeffnung : 24|8@1+ (0.5,0) [0.0|100.0] "Unit_PerCent"  OCU,ZR_MIB_TOP_ab_Gen3
 SG_ BT_FH_Bew_hoch : 32|1@1+ (1.0,0.0) [0.0|1] ""  Vector__XXX
 SG_ BT_FH_Bew_tief : 33|1@1+ (1.0,0.0) [0.0|1] ""  Vector__XXX
 SG_ BT_FH_Fang : 34|1@1+ (1.0,0.0) [0.0|1] ""  OCU
 SG_ BT_FH_Block : 35|1@1+ (1.0,0.0) [0.0|1] ""  Vector__XXX
 SG_ BT_FH_Thermo : 36|1@1+ (1.0,0.0) [0.0|1] ""  Vector__XXX
 SG_ BT_UEKB_aktiviert : 37|1@1+ (1.0,0.0) [0.0|1] ""  Vector__XXX
 SG_ BT_Kisi_Fehler : 38|1@1+ (1.0,0.0) [0.0|1] ""  Vector__XXX
 SG_ BT_FH_normiert : 39|1@1+ (1.0,0.0) [0.0|1] ""  OCU
 SG_ BT_Schliesstaster : 40|1@1+ (1.0,0.0) [0.0|1] ""  Vector__XXX
 SG_ BT_Zuziehhilfe_aktiv : 41|1@1+ (1.0,0.0) [0.0|1] ""  Vector__XXX
 SG_ BT_SP_ausgerastet : 42|1@1+ (1.0,0.0) [0.0|1] ""  Vector__XXX
 SG_ BT_SP_lr_aktiv : 43|1@1+ (1.0,0.0) [0.0|1] ""  Vector__XXX
 SG_ BT_SP_ht_aktiv : 44|1@1+ (1.0,0.0) [0.0|1] ""  Vector__XXX
 SG_ BT_SP_Heizung_aktiv : 45|1@1+ (1.0,0.0) [0.0|1] ""  Vector__XXX
 SG_ BT_Oben_Block_erw : 46|1@1+ (1.0,0.0) [0.0|1] ""  Vector__XXX
 SG_ BT_Unten_Block_erw : 47|1@1+ (1.0,0.0) [0.0|1] ""  Vector__XXX
 SG_ BT_Tuer_Status_QBit : 48|1@1+ (1.0,0.0) [0.0|1] ""  Vector__XXX
 SG_ BFS_Status_eTAG : 49|2@1+ (1.0,0.0) [0.0|3] ""  Vector__XXX
 SG_ BT_TCR_Mode_aktiv : 51|1@1+ (1.0,0.0) [0.0|1] ""  Vector__XXX
 SG_ BT_Lock_Unlock_Taster : 52|1@1+ (1.0,0.0) [0.0|1] ""  Vector__XXX
 SG_ BT_SP_Heizung_Status : 55|1@1+ (1.0,0.0) [0.0|1] ""  Vector__XXX
 SG_ ASW_Warnung_aktiv_BFS : 56|1@1+ (1.0,0.0) [0.0|1] ""  Vector__XXX
 SG_ BT_FH_Pos_oben : 57|1@1+ (1.0,0.0) [0.0|1] ""  Vector__XXX
 SG_ BT_Tuerschloss_defekt : 58|1@1+ (1.0,0.0) [0.0|1] ""  Vector__XXX
 SG_ BT_Tueroeffnen_Warnung : 59|1@1+ (1.0,0.0) [0.0|1] ""  Vector__XXX
 SG_ BT_Lock_Taster_inv : 60|1@1+ (1.0,0.0) [0.0|1] ""  Vector__XXX
 SG_ BT_Schluesselschalter_zu_inv : 61|1@1+ (1.0,0.0) [0.0|1] ""  Vector__XXX
 SG_ BT_SWA_HMI_defekt : 62|1@1+ (1.0,0.0) [0.0|1] ""  Vector__XXX
 SG_ BT_ASW_HMI_defekt : 63|1@1+ (1.0,0.0) [0.0|1] ""  Vector__XXX

BO_ 976 TSG_FT_01: 8 Gateway_Max
 SG_ FT_Tuer_geoeffnet : 0|1@1+ (1.0,0.0) [0.0|1] ""  OCU,ZR_MIB_TOP_ab_Gen3
 SG_ FT_verriegelt : 1|1@1+ (1.0,0.0) [0.0|1] ""  OCU
 SG_ FT_gesafet : 2|1@1+ (1.0,0.0) [0.0|1] ""  OCU
 SG_ FT_Schluesselschalter_auf : 3|1@1+ (1.0,0.0) [0.0|1] ""  Vector__XXX
 SG_ FT_Schluesselschalter_zu : 4|1@1+ (1.0,0.0) [0.0|1] ""  Vector__XXX
 SG_ FT_Unlock_Taster : 5|1@1+ (1.0,0.0) [0.0|1] ""  Vector__XXX
 SG_ FT_Lock_Taster : 6|1@1+ (1.0,0.0) [0.0|1] ""  Vector__XXX
 SG_ FT_Sperrklinke : 7|1@1+ (1.0,0.0) [0.0|1] ""  Vector__XXX
 SG_ FT_TAG_betaetigt : 8|1@1+ (1.0,0.0) [0.0|1] ""  Vector__XXX
 SG_ FT_TIG_betaetigt : 9|1@1+ (1.0,0.0) [0.0|1] ""  Vector__XXX
 SG_ FT_IRUE_Taste : 10|1@1+ (1.0,0.0) [0.0|1] ""  Vector__XXX
 SG_ FT_HD_Taste : 11|1@1+ (1.0,0.0) [0.0|1] ""  Vector__XXX
 SG_ FT_TD_Taste_Fehler : 12|1@1+ (1.0,0.0) [0.0|1] ""  Vector__XXX
 SG_ FT_TD_Taste : 13|1@1+ (1.0,0.0) [0.0|1] ""  Vector__XXX
 SG_ SSR_Temp_Freigabe : 14|1@1+ (1.0,0.0) [0.0|1] ""  Vector__XXX
 SG_ FT_Sp_Heizung_Anf : 15|1@1+ (100,0) [0|100] "Unit_PerCent"  Vector__XXX
 SG_ FT_HD_Taste_2 : 16|1@1+ (1.0,0.0) [0.0|1] ""  Vector__XXX
 SG_ FT_Lock_Unlock_Taster : 17|1@1+ (1.0,0.0) [0.0|1] ""  Vector__XXX
 SG_ FT_TSG_hinten_verbaut : 18|1@1+ (1.0,0.0) [0.0|1] ""  Vector__XXX
 SG_ FT_Sp_Blk_def : 19|1@1+ (1.0,0.0) [0.0|1] ""  Vector__XXX
 SG_ FT_FH_S_ManHoch : 20|1@1+ (1.0,0.0) [0.0|1] ""  Vector__XXX
 SG_ FT_FH_S_AutoHoch : 21|1@1+ (1.0,0.0) [0.0|1] ""  Vector__XXX
 SG_ FT_FH_S_ManTief : 22|1@1+ (1.0,0.0) [0.0|1] ""  Vector__XXX
 SG_ FT_FH_S_AutoTief : 23|1@1+ (1.0,0.0) [0.0|1] ""  Vector__XXX
 SG_ FT_FH_Oeffnung : 24|8@1+ (0.5,0) [0.0|100.0] "Unit_PerCent"  OCU,ZR_MIB_TOP_ab_Gen3
 SG_ FT_FH_Bew_hoch : 32|1@1+ (1.0,0.0) [0.0|1] ""  Vector__XXX
 SG_ FT_FH_Bew_tief : 33|1@1+ (1.0,0.0) [0.0|1] ""  Vector__XXX
 SG_ FT_FH_Fang : 34|1@1+ (1.0,0.0) [0.0|1] ""  OCU
 SG_ FT_FH_Block : 35|1@1+ (1.0,0.0) [0.0|1] ""  Vector__XXX
 SG_ FT_FH_Thermo : 36|1@1+ (1.0,0.0) [0.0|1] ""  Vector__XXX
 SG_ FT_UEKB_aktiviert : 37|1@1+ (1.0,0.0) [0.0|1] ""  Vector__XXX
 SG_ ASW_HMI_defekt : 38|1@1+ (1.0,0.0) [0.0|1] ""  Vector__XXX
 SG_ FT_FH_normiert : 39|1@1+ (1.0,0.0) [0.0|1] ""  OCU
 SG_ FT_Schliesstaster : 40|1@1+ (1.0,0.0) [0.0|1] ""  Vector__XXX
 SG_ FT_Zuziehhilfe_aktiv : 41|1@1+ (1.0,0.0) [0.0|1] ""  Vector__XXX
 SG_ FT_SP_ausgerastet : 42|1@1+ (1.0,0.0) [0.0|1] ""  Vector__XXX
 SG_ FT_SP_lr_aktiv : 43|1@1+ (1.0,0.0) [0.0|1] ""  Vector__XXX
 SG_ FT_SP_ht_aktiv : 44|1@1+ (1.0,0.0) [0.0|1] ""  Vector__XXX
 SG_ ASW_wakeup : 45|1@1+ (1.0,0.0) [0.0|1] ""  Vector__XXX
 SG_ FT_Oben_Block_erw : 46|1@1+ (1.0,0.0) [0.0|1] ""  Vector__XXX
 SG_ FT_Unten_Block_erw : 47|1@1+ (1.0,0.0) [0.0|1] ""  Vector__XXX
 SG_ FT_Kisi_li_aktiv : 48|1@1+ (1.0,0.0) [0.0|1] ""  OCU,ZR_MIB_TOP_ab_Gen3
 SG_ FT_Kisi_re_aktiv : 49|1@1+ (1.0,0.0) [0.0|1] ""  OCU,ZR_MIB_TOP_ab_Gen3
 SG_ FT_Kisi_Taster_li : 50|1@1+ (1.0,0.0) [0.0|1] ""  Vector__XXX
 SG_ FT_Kisi_Taster_re : 51|1@1+ (1.0,0.0) [0.0|1] ""  Vector__XXX
 SG_ FT_BFS_Fond_Freigabe : 52|1@1+ (1.0,0.0) [0.0|1] ""  Vector__XXX
 SG_ FT_Kisi_Fehler : 53|1@1+ (1.0,0.0) [0.0|1] ""  Vector__XXX
 SG_ FT_Daemmglas : 54|1@1+ (1.0,0.0) [0.0|1] ""  Vector__XXX
 SG_ FT_SP_Heizung_Status : 55|1@1+ (1.0,0.0) [0.0|1] ""  Vector__XXX
 SG_ ASW_Warnung_aktiv_FS : 56|1@1+ (1.0,0.0) [0.0|1] ""  Vector__XXX
 SG_ FT_FH_Pos_oben : 57|1@1+ (1.0,0.0) [0.0|1] ""  Vector__XXX
 SG_ FT_Tuerschloss_defekt : 58|1@1+ (1.0,0.0) [0.0|1] ""  Vector__XXX
 SG_ FT_SWA_Taster : 59|1@1+ (1.0,0.0) [0.0|1] ""  Vector__XXX
 SG_ SWA_HMI_Diagnose : 60|2@1+ (1.0,0.0) [0.0|3] ""  Vector__XXX
 SG_ FS_Status_eTAG : 62|2@1+ (1.0,0.0) [0.0|3] ""  Vector__XXX

BO_ 997 TSG_FT_02: 8 Gateway_Max
 SG_ TSG_FT_02_CRC : 0|8@1+ (1,0) [0|255] ""  Vector__XXX
 SG_ TSG_FT_02_BZ : 8|4@1+ (1,0) [0|15] ""  Vector__XXX
 SG_ FT_Tuer_Status : 12|2@1+ (1.0,0.0) [0.0|3] ""  BedienDisp_mi,BedienDisp_vo_mi,OCU
 SG_ FT_Tuer_Status_QBit : 14|1@1+ (1.0,0.0) [0.0|1] ""  Vector__XXX
 SG_ FT_Lock_Taster_02 : 15|1@1+ (1.0,0.0) [0.0|1] ""  Vector__XXX
 SG_ FT_Schluesselschalter_zu_02 : 16|1@1+ (1.0,0.0) [0.0|1] ""  Vector__XXX
 SG_ FT_BFS_Tuer_Status : 17|2@1+ (1.0,0.0) [0.0|3] ""  Vector__XXX
 SG_ FT_HBFS_Tuer_Status : 19|2@1+ (1.0,0.0) [0.0|3] ""  Vector__XXX
 SG_ FT_HFS_Tuer_Status : 21|2@1+ (1.0,0.0) [0.0|3] ""  Vector__XXX
 SG_ FT_Tueroeffnen_Warnung : 23|1@1+ (1.0,0.0) [0.0|1] ""  Vector__XXX
 SG_ FT_SP_Heizung_ein : 24|1@1+ (1.0,0.0) [0.0|1] ""  Vector__XXX
 SG_ FT_Kisi_Taster_li_02 : 25|1@1+ (1.0,0.0) [0.0|1] ""  Vector__XXX
 SG_ FT_Kisi_Taster_re_02 : 26|1@1+ (1.0,0.0) [0.0|1] ""  Vector__XXX
 SG_ FT_TD_Taste_Status : 27|2@1+ (1.0,0.0) [0.0|3] ""  Vector__XXX
 SG_ FT_TCR_Mode_aktiv : 29|1@1+ (1.0,0.0) [0.0|1] ""  Vector__XXX
 SG_ TBF_FS_Touch_Event : 30|4@1+ (1.0,0.0) [0.0|15] ""  ICC_IO_Node
 SG_ FT_KiSi_Status_Soll_HBFS : 34|1@1+ (1.0,0.0) [0.0|1] ""  Vector__XXX
 SG_ FT_KiSi_Status_Soll_HFS : 35|1@1+ (1.0,0.0) [0.0|1] ""  Vector__XXX
 SG_ FS_Push_Tuergriff : 36|1@1+ (1.0,0.0) [0.0|1] ""  Vector__XXX
 SG_ TSG_FS_Spiegel_angeklappt : 37|1@1+ (1.0,0.0) [0.0|1] ""  Vector__XXX
 SG_ FT_Cargolock_bet : 38|1@1+ (1.0,0.0) [0.0|1] ""  Vector__XXX
 SG_ FT_kisi_asynchron : 40|1@1+ (1.0,0.0) [0.0|1] ""  Vector__XXX
 SG_ eTAB_FS_Bowdenzug_Auswerfen : 41|1@1+ (1.0,0.0) [0.0|1] ""  Vector__XXX
 SG_ FS_Status_eTAG_ext : 42|3@1+ (1.0,0.0) [0.0|7] ""  Vector__XXX
 SG_ FT_ASW_Warnton : 45|2@1+ (1.0,0.0) [0.0|3] ""  Vector__XXX
 SG_ SSA_FT_ASW_Status : 47|2@1+ (1.0,0.0) [0.0|3] ""  Vector__XXX

BO_TX_BU_ 2464161907 :ICC_IO_Node,ZR_MIB_OPTION_ab_Gen3;
BO_TX_BU_ 2464153715 :ICC_IO_Node,ZR_MIB_EINSTIEG_ab_Gen3,ZR_MIB_OPTION_ab_Gen3,ZR_MIB_TOP_ab_Gen3;
BO_TX_BU_ 1637 :Gateway_Max,ZR_MIB_EINSTIEG_ab_Gen3,ZR_MIB_OPTION_ab_Gen3,ZR_MIB_TOP_ab_Gen3;
CM_ BO_ 1529 "MQB";
CM_ BO_ 1440 "8Byte ab MLBevo
LIN-CAN (1:1) Botschaften werden geroutet
-  wenn entsprechender Slave codiert ist
-  wenn fehlerfreie Kommunikation zum Slave besteht
-  bei fehlerhafter Kommunikation zum Slave wird die Botschaft für 4s mit den letzten gültigen Werte";
CM_ BO_ 1504 "MLBevo 8Byte
LIN-CAN (1:1) Botschaft wird geroutet:
- wenn entsprechender Slave codiert ist
- wenn fehlerfreie Kommunikation zum Slave besteht
- bei fehlerhafter Kommunikation zum Slave wird die Botschaft für 4s mit den letzten gültigen Werten versend";
CM_ BO_ 1363 "Botschaft vom Steuergerät der dritten Sitzreihe";
CM_ BO_ 980 "Ab MQB 7.2";
CM_ BO_ 1413 "MQB, MLBevo";
CM_ BO_ 977 "ab MQB 7.05";
CM_ BO_ 976 "ab MQB 7.05";

CM_ SG_ 1529 RDK_angelernt "RDK signalisiert, dass die Radelektroniken angelernt sind und das Kombi den Rundstreckenmodus anbieten kann.";
CM_ SG_ 1529 RDK_FMVSS138_Lampe "Ansteuerung der RDK-Lampe im Kombi bei Druckwarnung";
CM_ SG_ 1529 RDK_FMVSS138_MIL "Ansteuerung der RDK-Lampe im Kombi bei Systemstörung.
RDK-Lampe muss für 65 Sekunden blinken und anschliessend dauerhaft leuchten bis RDK dieses Bit wieder auf '0' setzt (Wiedergutprüfung).
Hinweis:  Im AU48x blinken für 60 Sekunden";
CM_ SG_ 1529 RDK_Kalibrierung "Art der Vorgabe der Solldrücke
0x0 Vorgabe der Solldrücke erfolgt durch eine Reifenauswahl in der Headunit
0x1 Vorgabe der Solldrücke erfolgt durch Betätigung des SET-Tasters des Kombiinstruments";
CM_ SG_ 1529 RDK_Reifendruck_Lampe "Ansteuerung einer RDK-Lampe im Kombi bei einem problematischen Druck";
CM_ SG_ 1529 RDK_Reifentemperatur_Lampe "Ansteuerung einer RDK-Lampe im Kombi bei einer problematischen Reifentemperatur";
CM_ SG_ 1529 RDK_RS_aktiv "Rundstreckenmodus inaktiv/ aktiv";
CM_ SG_ 1529 RDK_Text_7 "Textausgabe 7: Mindestdruck für Rundstreckenmode unterschritten";
CM_ SG_ 1529 RDK_W_1_Reifen_HL "Harte Warnung fuer Reifen hinten links";
CM_ SG_ 1529 RDK_W_1_Reifen_HR "Harte Warnung fuer Reifen hinten rechts";
CM_ SG_ 1529 RDK_W_1_Reifen_VL "Harte Warnung fuer Reifen vorne links";
CM_ SG_ 1529 RDK_W_1_Reifen_VR "Harte Warnung fuer Reifen vorne rechts";
CM_ SG_ 1529 RDK_W_2_Reifen_HL "Weiche Warnung fuer Reifen hinten links";
CM_ SG_ 1529 RDK_W_2_Reifen_HR "Weiche Warnung fuer Reifen hinten rechts";
CM_ SG_ 1529 RDK_W_2_Reifen_VL "Weiche Warnung fuer Reifen vorne links";
CM_ SG_ 1529 RDK_W_2_Reifen_VR "Weiche Warnung fuer Reifen vorne rechts";
CM_ SG_ 1529 RDK_Warnungen_02 "Ausgabe von Texten/Akustik im Kombiinstrument";

CM_ SG_ 1711 RV_Dark_Screen "Verdunkelungsanforderung Kamerabild";
CM_ SG_ 1711 RV_Farbe "Istwert fuer Farbe (in Prozent)";
CM_ SG_ 1711 RV_Helligkeit "Istwert fuer Helligkeit (in Prozent)";
CM_ SG_ 1711 RV_HMI_Mode "Aktueller Wert für den HMI-Modus

";
CM_ SG_ 1711 RV_Kontrast "Istwert fuer Kontrast (in Prozent)";
CM_ SG_ 1711 RV_Menu_Item "Ausgewähltes Menü-Item
";
CM_ SG_ 1711 RV_Reinigung_Anf "Anforderung Reinigung der Rückfahrkamera";
CM_ SG_ 1711 RV_Settings_enabled "Menü 'Einstellungen'
";
CM_ SG_ 1711 RV_System_aktiv "Systemstatus (Initialisierungsphase)
";
CM_ SG_ 1711 RV_Video_on "Anzeige Kamerabild
";
CM_ SG_ 1711 SV_Video_on "Aufschaltaufforderung SideView";
CM_ SG_ 1711 ZFAS_Umfeldbeleuchtung_Anf "Anforderung für die Aktivierung einer Umfeldbeleuchtung zur Unterstützung des Umfeldkamerasystems bei Dunkelheit";

CM_ SG_ 2463978734 SLCV_PaCo_CurrentView "current view of the SLCV function
(Sideview + LeavingCarView)";
CM_ SG_ 2463978734 SLCV_PaCo_MainState "main state of the SLCV function
(Sideview + LeavingCarView)";
CM_ SG_ 2463978734 VPS_PaCo_Button "Signalisierung eines gedrückten VPS-Hardkeys.


0 Init_Or_Not_Equipped: Init oder kein VPS-Hardkey vorhanden
1 Button_Not_Pressed: VPS-Hardkey ist nicht gedrückt
2 Button_Pressed_Debounced: VPS-Hardkey ist gedrückt (entprellt)
3 Error: Fehler";
CM_ SG_ 2463978734 VPS_PaCo_CurrentBirdview "Current-Birdview of the  VPS-Function";
CM_ SG_ 2463978734 VPS_PaCo_CurrentBowl "Control of the 3D view direction";
CM_ SG_ 2463978734 VPS_PaCo_CurrentCarOverlay "Ist-Car Overlay der VPS Funktion (aus, ein, transparent)";
CM_ SG_ 2463978734 VPS_PaCo_CurrentMode "Current-Mode of the  VPS-Function";
CM_ SG_ 2463978734 VPS_PaCo_CurrentRVCscreen "Signal zum Umschalten der Rearview Ansicht

Werte:
0x0=NoScreen
0x1=Fullscreen
0x2=Side-by-Side / Splitscreen";
CM_ SG_ 2463978734 VPS_PaCo_CurrentVideoState "Current-VideoState of the  VPS-Function";
CM_ SG_ 2463978734 VPS_PaCo_CurrentView "Current-View of the  VPS-Function";
CM_ SG_ 2463978734 VPS_PaCo_CurrGraphOverlay "Control of the graphical overlay on the video image";
CM_ SG_ 2463978734 VPS_PaCo_MainState "Main-State of the VPS-Function";

CM_ SG_ 1527 RW_Gesamt_Reichweite_Anzeige "Reichweite für primär und sekundär Reichweite (eventuell Gewichtet) zur Anzeige im Kombi. Die Einheit dieser Signal ist über RW_Reichweite_Einheit_Anzeige bereitgestellt.";
CM_ SG_ 1527 RW_Primaer_Reichweite_Anzeige "Reichweite der primären Antriebsart zur Anzeige im Kombi";
CM_ SG_ 1527 RW_Reichweite_Einheit_Anzeige "Einheit für Primaer-/Sekundaer-/Gesamt- Reichweite zur Anzeige im Kombi";
CM_ SG_ 1527 RW_Reservewarnung_aktiv "Ansteuerung der Reservewarnung im Kombiinstrument (Leuchte und MFA-Warnhinweis). Wird gesetzt bei Erreichen / Unterschreiten eines unteren Reichweitenschwellwerts und zurückgenommen bei Erreichen / Überschreiten eines oberen Reichweitenschwellwerts.";
CM_ SG_ 1527 RW_Sek_Reichweitenv_Einheit "Für sekundäre Reichweitenberechnung (KBI_Sek_Reichweitenverbrauch) zugrunde gelegte Einheit";
CM_ SG_ 1527 RW_Sek_Reichweitenverbrauch "Für sekundäre Reichweitenberechnung zugrunde gelegter Verbrauch";
CM_ SG_ 1527 RW_Sekundaer_Reichweite "Reichweite der sekundaeren Antriebsart";
CM_ SG_ 1527 RW_Sekundaer_Reichweite_Anzeige "Reichweite der sekundaeren Antriebsart zur Anzeige im Kombi";
CM_ SG_ 1527 RW_Tendenz "Signalisierung der RW-Tendenz auf Basis der aktuellen Fahrweise. ";
CM_ SG_ 1527 RW_Texte "Signal zum Steuern von reichweitenbezogenen Hinweistexten für Pop-Up Anzeigen im Kombiinstrument";

CM_ SG_ 1610 RKA_FMVSS138_Lampe "Kein Einsatz RKA im D4 Hybrid";
CM_ SG_ 1610 RKA_FMVSS138_MIL "Zentral blinkend für 1 Minute immer nur gelbe Lampe, dann statisch an. 

Kein Einsatz RKA im D4 Hybrid";
CM_ SG_ 1610 RKA_Reifentyp "Ausgabe von Reifentyp";
CM_ SG_ 1610 RKA_Warnungen_02 "Ansteuerung der Warnungen (Texte, Töne, Lampen) im Kombi für Funktion RKA+

Kein Einsatz RKA im D4 Hybrid";

CM_ SG_ 1440 LS_defekt "Fehlererkennung Lichtsensor
";
CM_ SG_ 1440 LS_Helligkeit_FW "Vorfeldhelligkeit";
CM_ SG_ 1440 LS_Helligkeit_IR "Globalfeldhelligkeit";
CM_ SG_ 1440 LS_Verbau "Verbauinfo Lichtsensor";
CM_ SG_ 1440 RLS_Vorfeldhelligkeit_Boost "erweiterte Helligkeitssensierung für HUD";
CM_ SG_ 1440 RS_defekt "Fehlererkennung Regensensor";
CM_ SG_ 1440 RS_Regenmenge "Regenmenge";
CM_ SG_ 1440 RS_Schwall "Schwallereignis";
CM_ SG_ 1440 RS_Verbau "Verbauinfo Regensensor";
CM_ SG_ 1440 RS_Verglasung_schliessen "Anforderung: Verglasung schliessen
";
CM_ SG_ 1440 RS_Wischergeschwindigkeit "Wischergeschwindigkeit (Hübe/min)";
CM_ SG_ 1440 SLS_Helligkeit_IR "Helligkeitswert des 'Smart-Light-Sensor' im Dashboard analog / alternativ zu LS_Helligkeit_IR.

Es ist entweder ein RLS_LIN oder ein Smart-LS im FZG verbaut.";

CM_ SG_ 1504 MD1_Lage "Lage Schiebedachstellung 1 (Signal wird 1:1 vom BCM2 geroutet; ursprünglicher Sender: SAD = LIN-Slave vom BCM2)";
CM_ SG_ 1504 MD1_Position "Aktuelle Öffnungsweite Schiebedach.";
CM_ SG_ 1504 MD3_Lage "Lage Schiebedachstellung 3 
(Signal wird 1:1 vom BCM2 geroutet; ursprünglicher Sender: SAD = LIN-Slave vom BCM2) 
";
CM_ SG_ 1504 MD3_Position "Schiebedachstellung 3 
(Signal wird 1:1 vom BCM2 geroutet; ursprünglicher Sender: SAD = LIN-Slave vom BCM2)
";
CM_ SG_ 1504 MRollo_Lage "Lage Rollo
(Signal wird 1:1 vom BCM2 geroutet; ursprünglicher Sender: Rollo = LIN-Slave vom BCM2)";
CM_ SG_ 1504 MRollo_Position "Aktuelle Öffnungsweite des Dachrollos.";
CM_ SG_ 1504 Rollo_normiert "Anzeigen Normierung des Dachrollos";
CM_ SG_ 1504 Rollo_Thermoschutz "Anzeigen aktivierter Thermoschutz des Dachrollo";
CM_ SG_ 1504 Rollo_UEKB_aktiv "Anzeigen aktivierter Überschusskraftbegrenzung des Dachrollos";
CM_ SG_ 1504 SAD_Anf_ESC_Zuschaltung "Zwangsaktivierung ESP durch SAD-SG (bei geöffnetem Schiebedach und V> xx km/h).";
CM_ SG_ 1504 SAD_normiert "Anzeige Normierung des Schiebeausstelldaches";
CM_ SG_ 1504 SAD_Taster_Deckel_hi "Taster für SAD Deckel hinten";
CM_ SG_ 1504 SAD_Taster_Deckel_vo "Taster für SAD Deckel vorne";
CM_ SG_ 1504 SAD_Taster_Rollo_hi "Taster für SAD Rollo hinten";
CM_ SG_ 1504 SAD_Taster_Rollo_vo "Taster für SAD Rollo vorne";
CM_ SG_ 1504 SAD_Thermoschutz "Anzeige aktivierter Thermoschutz des Schiebeausstelldaches";
CM_ SG_ 1504 SAD_UEKB_aktiv "Anzeige aktivierter Überschusskraftbegrenzung des Schiebeausstelldaches";

CM_ SG_ 2463978605 SCode_Data "Komfortcodierung
Antwort auf Komfort-Radio-Request
Security Acces_Mode_2
Timeout, siehe Radio-spec.";
CM_ SG_ 2463978605 SCode_Target "Komfortcodierung
Adresse des anfragenden Teilnehmers
Zieladresse Security_Request";

CM_ SG_ 873 SDF2_Pos_AnzHauptspuren "Gesamthauptspuranzahl (ohne Ausfahrtsspuren)";
CM_ SG_ 873 SDF2_Pos_AnzRampenLinks "Zusätzliche Spuren links (z.B. Aus- / Auffahrtsspuren, Abbiegespuren)";
CM_ SG_ 873 SDF2_Pos_AnzRampenRechts "Zusätzliche Spuren rechts (z.B. Aus- / Auffahrtsspuren, Abbiegespuren)";
CM_ SG_ 873 SDF2_Pos_Distanz_Rampe_links "Distanz kommende Rampe links";
CM_ SG_ 873 SDF2_Pos_Distanz_Rampe_rechts "Distanz kommende Rampe rechts";
CM_ SG_ 873 SDF2_Pos_Fehler_Laengsrichtung "Längsfehler der Positionskorrektur im zFAS";
CM_ SG_ 873 SDF2_Pos_GueteZuordnung "Guete der Spurzuordnung";
CM_ SG_ 873 SDF2_Pos_Inhibitzeit "Zeitspanne zwischen Generierung der Position im ZR und Versand der Positionsdaten durch das zFAS";
CM_ SG_ 873 SDF2_Pos_Offset "Verbleibende Länge des Streckensegments, auf dem sich das Fahrzeug nach der Positionierung auf dem zFAS befindet.";
CM_ SG_ 873 SDF2_Pos_Segment_ID "PSD-Segment ID der Positionierung im zFAS";
CM_ SG_ 873 SDF2_Pos_Spurnummer "Spurnummer des Fahrzeugs
Negativ=Auf-/Ausfahrten, Abbiegespuren
Positiv=Hauptspuren";
CM_ SG_ 873 SDF2_Pos_Spurtype "Typ der Spur";
CM_ SG_ 873 SDF2_Pos_Standort_Eindeutig "Information, ob die Position des Fahrzeugs im zFAS eindeutig dem aktuellen Segment zugeordnet wurde.";

CM_ SG_ 1167 SK1_Key_Data_1 "1. Multiplexbotschaft der Service-Key Funktion";
CM_ SG_ 1167 SK1_Key_Data_10 "10. Multiplexbotschaft der Service-Key Funktion";
CM_ SG_ 1167 SK1_Key_Data_2 "2. Multiplexbotschaft der Service-Key Funktion";
CM_ SG_ 1167 SK1_Key_Data_3 "3. Multiplexbotschaft der Service-Key Funktion";
CM_ SG_ 1167 SK1_Key_Data_4 "4. Multiplexbotschaft der Service-Key Funktion";
CM_ SG_ 1167 SK1_Key_Data_5 "5. Multiplexbotschaft der Service-Key Funktion";
CM_ SG_ 1167 SK1_Key_Data_6 "6. Multiplexbotschaft der Service-Key Funktion";
CM_ SG_ 1167 SK1_Key_Data_7 "7. Multiplexbotschaft der Service-Key Funktion";
CM_ SG_ 1167 SK1_Key_Data_8 "8. Multiplexbotschaft der Service-Key Funktion";
CM_ SG_ 1167 SK1_Key_Data_9 "9. Multiplexbotschaft der Service-Key Funktion";
CM_ SG_ 1167 SK1_MUX "Multiplexer-Signal der Service-Key Botschaft";

CM_ SG_ 1363 SitzMemo_SR3_01_BZ "4bit Botschaftszähler, wird mit jeder Sendebotschaft inkrementiert";
CM_ SG_ 1363 SitzMemo_SR3_01_CRC "Für MLB:
Berechnung siehe Lastenheft 'Kommunikationsabsicherung für FlexRay und CAN'
Ab MQB und MLBevo:
Berechnung siehe Lastenheft 'End-to-End Kommunikationsabsicherung'

Endwerte siehe Begleitdokument 'S-PDU Kennungsfolgen'";
CM_ SG_ 1363 SR3_Entriegl_Motor_li "Entriegelungsmotor links";
CM_ SG_ 1363 SR3_Entriegl_Motor_re "Entriegelungsmotor rechts";
CM_ SG_ 1363 SR3_Fahrpos_HBFS_erzeugen "Anforderung Fahrposition erzeugen von 3.SR an HBFS";
CM_ SG_ 1363 SR3_Fahrpos_HFS_erzeugen "Anforderung Fahrposition erzeugen von 3.SR an HFS";
CM_ SG_ 1363 SR3_Fahrpos_HFS_HBFS_erzeugen "Anforderung Fahrposition erzeugen von 3.SR an 2.SR komplett";
CM_ SG_ 1363 SR3_Fahrposition_links "Designpositionssensor (Fahrposition) links";
CM_ SG_ 1363 SR3_Fahrposition_rechts "Designpositionssensor (Fahrposition)  rechts";
CM_ SG_ 1363 SR3_Ladeboden_HBFS_erzeugen "Anforderung Ladeboden erzeugen von 3.SR an HBFS";
CM_ SG_ 1363 SR3_Ladeboden_HBFS_HFS_erzeugen "Anforderung Ladeboden erzeugen von 3.SR an 2.SR komplett";
CM_ SG_ 1363 SR3_Ladeboden_HFS_erzeugen "Anforderung Ladeboden erzeugen von 3.SR an HFS";
CM_ SG_ 1363 SR3_Status_Lehne_Links "Status der Lehnenverriegelung  Links von der 3ten Sitzreihe ";
CM_ SG_ 1363 SR3_Status_Lehne_Rechts "Status der Lehnenverriegelung  Rechts von der 3ten Sitzreihe ";
CM_ SG_ 1363 SR3_Verriegelungssensor_li "2x Verriegelungssensor (außen und innen)";
CM_ SG_ 1363 SR3_Verriegelungssensor_re "2x Verriegelungssensor (außen und innen)";

CM_ SG_ 980 BH_Blinker_Fehler "Anzeige, ob am Lenkstockschalter ein Fehler anliegt.
Notwendig aufgrund ASIL-Einstufung";
CM_ SG_ 980 BH_Blinker_li "Blinkerhebel Richtung links";
CM_ SG_ 980 BH_Blinker_re "Blinkerhebel Richtung rechts";
CM_ SG_ 980 BH_Fernlicht "Betaetigung Fernlicht
";
CM_ SG_ 980 BH_Lichthupe "Betaetigung Lichthupe
";
CM_ SG_ 980 FAS_Taster "Betaetigung FAS Taster
";
CM_ SG_ 980 FAS_Taster_Fehler "Fehlerstatus FAS Taster
";
CM_ SG_ 980 LRH_aktiv "Signal gibt an, ob ein Heizstrom durch die Lenkradheizung fließt. Es dient der Auswertung durch das Energiemanagement.";
CM_ SG_ 980 LRH_On_Off "Status Lenkradheizung";
CM_ SG_ 980 LSS_Tastencode "0x00 = No key pressed / key released
0x01 = Menu
0x02 = Menu Up / Next Screen
0x03 = Menu Down / Previous Screen
0x04 = Up
0x05 = Down
0x06 = Up / Down ThumbWheel
0x07 = OK (ThumbWheel-Button)
0x08 = Cancel / Escape
0x09..0x0F = reserved for furt";
CM_ SG_ 980 SMLS_01_BZ "4bit Botschaftszaehler, wird mit jeder Sendebotschaft inkrementiert";
CM_ SG_ 980 SMLS_01_CRC "Für MLB:
'Berechnung siehe Lastenheft 'Kommunikationsabsicherung für FlexRay und CAN''

Ab MQB und MLBevo:
'Berechnung siehe Lastenheft 'End-to-End Kommunikationsabsicherung''

Endwerte siehe Begleitdokument 'S-PDU Kennungsfolgen'";
CM_ SG_ 980 SMLS_Hupe "Betaetigung Hupe
";
CM_ SG_ 980 SMLS_P_verriegelt "Signal stellt den Status des Signals P-verriegelt auf den Fahrzeugbus zur Verfügung. Nutzer sind z.B. die ELV, die das Signal für die Verriegelung benötigt und die Funktion Verlassenswarnung, die den Fahrer beim Verrollen des Fahrzeugs warnt.";
CM_ SG_ 980 SMLS_P_verriegelt_plausibel "Signal stellt den Plausibilisierungstatus des Signals p_verriegelt auf den Fahrzeugbus zur Verfügung. Eine Plausibilität muss explizit erkannt werden. Initial wird 'unplausibel' gesendet. Ein plausibles Signal wird erkannt, wenn p_verriegelt plausibel geg";
CM_ SG_ 980 SMLS_PTT "Betaetigung PTT";
CM_ SG_ 980 WH_Frontwaschen "Wischerhebel: Stellung Wisch Wasch vorne
";
CM_ SG_ 980 WH_Heckintervall "Wischerhebel: Stellung Heckintervall
";
CM_ SG_ 980 WH_Heckwaschen "Wischerhebel: Stellung Wisch Wasch hinten
";
CM_ SG_ 980 WH_Intervall "Wischerhebel: Stellung Intervall
";
CM_ SG_ 980 WH_Intervallstufen "Wischerhebel: Stellung Intervallstufen";
CM_ SG_ 980 WH_SRA "Scheinwerferreinigungsanlage

derzeit nur bei PAG umgesetzt";
CM_ SG_ 980 WH_Tipwischen "Wischerhebel: Tippwischen

MQB A0/ PQ26: Bei Verbau LSS (kein SMLS): gespiegelter Wert zu Signal WH_WischerStufe1";
CM_ SG_ 980 WH_Tipwischen_lang "Wischerhebel: Tippwischen lang
(dient zur Auswertung für die Unterscheidung Tippwischen oder Serviceposition Wischer)";
CM_ SG_ 980 WH_Wischer_Fehler "Anzeige, ob am Lenkstockschalter ein Fehler anliegt.
Notwendig aufgrund ASIL-Einstufung";
CM_ SG_ 980 WH_WischerStufe1 "Wischerhebel: Stufe Wischen 1
";
CM_ SG_ 980 WH_WischerStufe2 "Wischerhebel: Stufe Wischen 2
";

CM_ SG_ 2464161907 SOK_FoD_Info_El_Req_Challenge "Challenge im Rahmen des SOK Challenge-Response Protokolls.

Geschützte Funktion: Function on Demand";

CM_ SG_ 2464301171 SOK_FoD_Info_El_Resp_Challenge "Challenge im Rahmen des SOK Challenge-Response Protokolls.

Geschützte Funktion: Function on Demand";

CM_ SG_ 2589283756 SOK_ungeschuetzte_Zeit "Periodisch verschickter SOK Zeitwert des SOK Zeitmasters als Referenzzeit zur Erkennung von Clockjitter durch andere SOK Teilnehmer.

Der Empfang dieses Signals ist verpflichtend für jedes Steuergerät, das durch die authentische Broadcast Funktionalität";

CM_ SG_ 2464153703 SOK_Zeit_OCU_Challenge "Challenge im Rahmen des SOK Challenge-Response Protokolls.

Geschützte Funktion: Empfang der SOK-Zeit vom SOK-Zeitmaster; verbindlich für Steuergeräte, welche mit der durch SOK geschützten Broadcast Nachrichten empfangen oder versenden";

CM_ SG_ 2464284775 SOK_Zeit_OCU_Signatur "Signatur im Rahmen des SOK Challenge-Response Protokolls.

Geschützte Funktion: Empfang der SOK-Zeit vom SOK-Zeitmaster; verbindlich für Steuergeräte, welche mit der durch SOK geschützten Broadcast Nachrichten empfangen oder versenden";

CM_ SG_ 2464288871 SOK_Zeit_OCU_Zeit "Aktueller Wert der SOK-Zeit des SOK-Zeitmasters; geschützt durch das SOK Challenge-Response Protokoll";

CM_ SG_ 2464153715 SOK_Zeit_Info_El_Challenge "Challenge im Rahmen des SOK Challenge-Response Protokolls.

Geschützte Funktion: Empfang der SOK-Zeit vom SOK-Zeitmaster; verbindlich für Steuergeräte, welche mit der durch SOK geschützten Broadcast Nachrichten empfangen oder versenden";

CM_ SG_ 2464288883 SOK_Zeit_Info_El_Signatur "SOK_Zeit_Info_El_Signatur";

CM_ SG_ 2464292979 SOK_Zeit_Info_El_Zeit "Response signal of SOK time server to challenge of an SOK participant, containing SOK time";

CM_ SG_ 1467 SoSe_SunInt_2D_Li "Sonnenintensität links (2D Sensor)";
CM_ SG_ 1467 SoSe_SunInt_2D_Re "Sonnenintensität rechts (2D Sensor)";

CM_ SG_ 1313 STH_EKP_Anst "STH sendet die Anforderung zur Ansteuerung der EKP an den Motor, um Kraftstoffbehälter der STH zu befüllen.";
CM_ SG_ 1313 STH_Fehler_ElWaPu "Fehler der el. Zusatzwasserpumpe der zur Deaktivierung der Wasserpumpe führt ";
CM_ SG_ 1313 STH_Fehlerstatus "Übermittlung der unterschiedlichen Fehlerzustände der Standheizung";
CM_ SG_ 1313 STH_Funk_aus "Funkbefehl über Funkfernbedienung zum Ausschalten Standheizung";
CM_ SG_ 1313 STH_Funk_ein "Funkbefehl über Funkfernbedienung zum Einschalten Standheizung";
CM_ SG_ 1313 STH_Geblaese "Ein-/ Ausschaltbefehl an die Klimaanlage, Gebläse";
CM_ SG_ 1313 STH_Heizleistung "Heizleistung in %";
CM_ SG_ 1313 STH_KL_HUP "Signal HUP Aktivierung an Klima

0 = HUP aus
1 = HUP ein";
CM_ SG_ 1313 STH_KVS "Kraftstoffverbrauch";
CM_ SG_ 1313 STH_KVS_Ueberlauf "Kraftstoffverbrauch, Überlauf hat stattgefunden";
CM_ SG_ 1313 STH_LED "Funktionslampe";
CM_ SG_ 1313 STH_Motorvorwaermung "Info an der Motor, dass der Aufheizvorgang mit Motorvorwärmung erfolgt ist";
CM_ SG_ 1313 STH_Pumpen_Anf_extern "Anforderung der motorseitigen elektr. (externen) Wasserpumpe zur Kreislaufunterstützung im Standheizbetrieb";
CM_ SG_ 1313 STH_Servicemode "Rückmeldung, dass die Standheizung sich gerade im Diagnosemodus befindet, gestartet über Diagnosetester";
CM_ SG_ 1313 STH_SH_ZH "0 = Heizgerät ist Standheizung
1 = Heizgerät ist Zuheizer
Gerätekennung WZH oder ZH
";
CM_ SG_ 1313 STH_Start_folgt "Thema Start/Stop: Im Stop-Modus muß das KBT einen Wiederstart anfordern, da ein STH-Start notwendig ist.";
CM_ SG_ 1313 STH_Texte "Anforderung der unterschiedlichen Anzeigetexte im Mitteldisplay des Kombi.

0: Keine Anzeige
1: Kein Standheizungs- bzw Lueftungsbetrieb wegen Batteriemanagementeinschraenkung
2: Kein Standheizungs- bzw Lueftungsbetrieb wegen Kraftstoffmangels
3: Kei";
CM_ SG_ 1313 STH_Ventil_Status "Statusrückmeldung Ansteuerung 3/2 Wege-Ventil";
CM_ SG_ 1313 STH_Ventiloeffnungszeit "Die Standheizung sendet an den Motor die Information darüber wie lange das Magnetventil die Wasserkreisläufe von 'klein' aus 'gross' geschaltet hat. ";
CM_ SG_ 1313 STH_Waermeeintrag "Signal enthält die Brenndauer in 1min-Schritten, über welche die Standheizung gelaufen ist";
CM_ SG_ 1313 STH_war_aktiv "Bit beeinhaltet die Info, dass die Standheizung während der letzten halbe Stunde aktiv war.";
CM_ SG_ 1313 STH_Wassertemp "Kühlmitteltemperatur der Standheizung";
CM_ SG_ 1313 STH_Zusatzheizung "Kraftstoffzuheizer aktiv";

CM_ SG_ 673 ASW_Kombiausgabe "ASW_Kombiausgabe bestimmt, welcher Text im Kombi angezeigt wird. Darüber hinaus werden auch Kombi-Akkustik durch dieses Signal ausgelöst.";
CM_ SG_ 673 ASW_Ton_Richtung_HL "ASW-Warntonausgabe hinten links";
CM_ SG_ 673 ASW_Ton_Richtung_HR "ASW_Warntonausgabe hinten rechts";
CM_ SG_ 673 ASW_Ton_Richtung_VL "ASW-Warntonausgabe vorne links";
CM_ SG_ 673 ASW_Ton_Richtung_VR "ASW-Warntonausgabe vorne rechts";
CM_ SG_ 673 SWA_Brightness_Mode_FPM "Actual mode for brightness settings of function Spurwechselassistent";
CM_ SG_ 673 SWA_Infostufe_Assist_li "Aktion der SWA-Funktion auf der entsprechenden Fahrzeugseite";
CM_ SG_ 673 SWA_Infostufe_Assist_re "Aktion der SWA-Funktion auf der entsprechenden Fahrzeugseite";
CM_ SG_ 673 SWA_Kombiausgabe "SWA_Kombiausgabe bestimmt, welcher Text im Kombi angezeigt wird.";
CM_ SG_ 673 SWA_Kombiwarnung "SWA_Kombiwarnung löst (akustische) Warnungen an den Fahrer aus";
CM_ SG_ 673 SWA_LED_Ausgabemodus_BFS "Ansteuerung SWA LED Beifahrerseite";
CM_ SG_ 673 SWA_LED_Ausgabemodus_FS "Ansteuerung SWA LED Fahrerseite";
CM_ SG_ 673 SWA_LED_Hell_BFS "Helligkeitswert SWA LED Beifahrerseite";
CM_ SG_ 673 SWA_LED_Hell_FS "Helligkeitswert SWA LED Fahrerseite";
CM_ SG_ 673 SWA_Modus_System "Gibt Zusatzinformationen zum SWA System Status an";
CM_ SG_ 673 SWA_Status "gibt die Verfügbarkeit der SWA_Status an";
CM_ SG_ 673 SWA_Status_KuFu "Gibt den Status der Kundenfunktion SWA an";
CM_ SG_ 673 SWA_Status_System "Gibt den Status des Systems SWA an";
CM_ SG_ 673 SWA_Warnstufe_Assist_li "Aktion der SWA-Funktion auf der entsprechenden Fahrzeugseite";
CM_ SG_ 673 SWA_Warnstufe_Assist_re "Aktion der SWA-Funktion auf der entsprechenden Fahrzeugseite";

CM_ SG_ 1413 GW_KD_Fehler "Kundendienstfehlerbit Gateway zur Anzeige eines im Gateway abgelegten Fehlerspeichereintrages.";
CM_ SG_ 1413 SI_BUS_01 "MQB/MQB_A0/PQ26: ACAN
MQB2020: ACAN(FD)
MLBevo: HCAN
E3_Volumen: ACAN(FD)
MQBw_Baseline: ACAN(FD)";
CM_ SG_ 1413 SI_BUS_02 "MQB/MQB A0 Standard+, High: FCAN
MQB2020: FCAN(FD)
MLBevo: Frei
E3_Volumen: FCAN(FD)
MQBw_Baseline: FCAN(FD)";
CM_ SG_ 1413 SI_BUS_03 "MQB/MQB A0/PQ26: KCAN
MQB2020: KCAN
MLBevo: KCAN
E3_Volumen: KCAN(HS) / K2CAN(FD) (Buskopplung)
MQBw_Baseline: KCAN(HS)";
CM_ SG_ 1413 SI_BUS_04 "MQB/MQB A0 Standard+, High: ICAN
MQB2020: ICAN(HS)
MLBevo: ICAN
E3_Volumen: ABCAN(FD)
MQBw_Baseline: ICAN(HS)";
CM_ SG_ 1413 SI_BUS_05 "MQB/MQB A0/PQ26: DiagCAN
MQB2020: DiagCAN(FD)
MLBevo: DiagCAN
E3_Volumen: DiagCAN(FD)
MQBw_Baseline: DiagCAN(FD)";
CM_ SG_ 1413 SI_BUS_06 "MQB/MQB A0/PQ26: ECAN
MQB2020: FASCAN(FD)
MLBevo: ECAN
E3_Volumen: FASCAN_1(FD)
MQBw_Baseline: FASCAN_1(FD)";
CM_ SG_ 1413 SI_BUS_07 "MQB: LIN1 (Energie)
MQB2020: LIN1 (Energie)
MLBevo: LIN1 (Energie)
E3_Volumen: LIN 1 (Energie)
MQBw_Baseline: LIN1 (Energie)";
CM_ SG_ 1413 SI_BUS_08 "MQB: LIN2 (MFL)
MQB2020: LIN2 (MFL)
MLBevo: LIN2 (MFL)
E3_Volumen: LIN2 (MFL)
MQBw_Baseline: LIN2 (MFL)";
CM_ SG_ 1413 SI_BUS_09 "MQB: LIN3 (unbelegt)
MQB2020: LIN3 (Uhr/FES)
MLBevo: LIN3 (Energie2)
MEB: LIN3
E³ 1.1 UNECE: MDKCAN";
CM_ SG_ 1413 SI_BUS_10 "MLBevo: Flexray
MQB2020: MCAN
MQBw_Baseline: FASCAN_2(FD)
E³ 1.1 UNECE: FASCAN_2(FD)";
CM_ SG_ 1413 SI_BUS_11 "MLBevo: Ethernet
MEB: LIN4";
CM_ SG_ 1413 SI_BUS_12 "MQB: unbelegt
MLBevo: K2CAN
E3_Volumen: MFLCAN
MQBw_Baseline: K2CAN(FD)";
CM_ SG_ 1413 SI_BUS_13 "MQB: unbelegt
MLBevo: DCAN
MEB: CCAN
MQBw_Baseline: K3CAN(FD)";
CM_ SG_ 1413 SI_BUS_14 "MQB/MQB A0: unbelegt
MQB2020: HCAN
MLBevo: CCAN
E3_Volumen: EVCAN(FD)
MQBw_Baseline: EVCANFD(FD)";
CM_ SG_ 1413 SI_BUS_15 "MQB: frei
MQB2020: frei
MLBevo: frei
MEB: AFSCAN";
CM_ SG_ 1413 SI_Bus_Identifikation "Das Signal identifiziert den Bus eindeutig. Das Signal ist konstant auf jedem Bus.
Der Signalwert entspricht dem Wert 'Busnummer' aus der VW80127 Gateway_component_list_databus_identification (0x2A2D) 'Bus-Identifier'.";
CM_ SG_ 1413 SI_CAB_V14 "CAB = Clusteraktivbits (V14)";
CM_ SG_ 1413 SI_Diagnose_Aktiv "Gibt an ob Diagnose-Botschaften empfangen werden und somit eine Diagnose aktiv ist.
MQB: Gibt an ob Diagnose-Bus Botschaften empfangen werden und somit eine Diagnose aktiv ist.";
CM_ SG_ 1413 SI_NWDF "Netzwerk-Diagnose Freigebe zur zentralen Aktivierung der Netzwerkdiagnose";
CM_ SG_ 1413 SI_NWDF_30 "Netzwerk-Diagnose Freigabe zur zentralen Aktivierung der Netzwerkdiagnose (keine Ausblendbedingung aktiv)";
CM_ SG_ 1413 SI_NWDF_gueltig "Gültigkeitsbit zu SI_NWDF gemäß Lastenheft: Zentrale Aktivierung Netzwerkdiagnose";
CM_ SG_ 1413 SI_P_Mode "Zentrale Steuerung des Produktionsmodes gemäß Q-LAH-Produktionsmode (LAH.DUM.907.AS)";
CM_ SG_ 1413 SI_P_Mode_gueltig "zeigt an, ob es sich um ein Fahrzeug mit zentraler oder dezentraler Steu-erung des Produktionsmodes handelt
Siehe Q-LAH Produktionsmode (LAH.DUM.907.AS)";
CM_ SG_ 1413 SI_QRS_Mode "Messmodus Quick-Ruhestrom";
CM_ SG_ 1413 SI_Sammel_SG_Fehler "Anzahl der gesetzten KD-Fehler direkt angeschlossener Steuergeräte der DK3 und DK4 gemäß 80127.
Hinweis: Ein Subbusmaster stellt nur die gesammelte Information der an ihn angeschlossenen Steuergeräte der DK3 und DK4 zur Verfügung.

Für ServiceKey Auswe";
CM_ SG_ 1413 SI_Sammelfehler "Sammelfehlermeldung zur Anzeige im Kombi - siehe Spez. Sammelfehlermeldung
Hinweis: Einzelne Steuergeräte können zur Anpassung an den Produktionsprozess im Gateway auskodiert werden!";
CM_ SG_ 1413 SI_T_Mode "0x0: Transportmodus nicht aktiv
0x1: Transportmodus aktiv";
CM_ SG_ 1413 SI_T_Schutz "Transportschutz-Signal, das bei Transportmodus und Motorlauf aktiv bleibt
0x0: Transportschutz nicht aktiv
0x1: Transportschutz aktiv";

CM_ SG_ 1637 TF_BT_ConnectionState "Bei vorhandener BT-Verbindung zum Mobilgerät soll im Kombiinstrument ein BT-Icon angezeigt werden.";
CM_ SG_ 1637 TF_Mute_Msg_Code "Tells the mute reason
0 = Phonecall (Telephone voive)
1 = Speech Recognition active (SDS active e.g. voice prompts)
2 = Emergency Call
3 = beep-signal (Signal tone)
4 = Operator Call
5 = Ringing
6 = Phonecall wideband voice
    (e.g. UMTS min 100H";
CM_ SG_ 1637 TF_Phone_active_call "Phone status, call active (call in progress)
0 = no active call  
1 = call active ";
CM_ SG_ 1637 TF_Phone_err_fieldstrength "Signal strength not available or error: if set, 
then the field strength is not determinable 
and the field strength information of 
TF_Phone_FieldStrength is invalid.";
CM_ SG_ 1637 TF_Phone_Error_Flag "State of CIB error memory 
0 = Error memory is empty  
1 = Error memory is not empty (mindestens ein Kundendienstfehlerspeicher  
    Eintrag vorhanden)";
CM_ SG_ 1637 TF_Phone_FieldStrength "Signal strength:(linear scaled range)
0  = 0%
15 = 100%";
CM_ SG_ 1637 TF_Phone_init "Phone initialization indication
0 = Telephone is initialized 
1 = Initialization in progress ";
CM_ SG_ 1637 TF_Phone_mute "Request to mute audio
0 = Audio active 
1 = Mute (TF_Mute_Msg_Code tells the reason) 
";
CM_ SG_ 1637 TF_Phone_on "Displays the current phone status
0 = Phone not active (MMI off)
1 = Phone active (MMI on)";
CM_ SG_ 1637 TF_Phone_PIN_ok "Result of entering the PIN. 
0 = PIN was not accepted by the SIM-card. 
1 = PIN was accepted by the SIM-card.";
CM_ SG_ 1637 TF_Phone_RegistrationState "Network registration status: 
set field to exact value from +CREG. In 
case +CREG returns ERROR (or until first 
OK response comes after init bit switches 
to 0), set it to 7. 
0 = no service, not searching 
1 = registered at home network 
2 = no s";
CM_ SG_ 1637 TF_Phone_ring "Incoming or waiting call 
0 = phone does not ring  
1 = phone rings ";
CM_ SG_ 1637 TF_Phone_SIM_ok "State of the SIM card reader
0 = Telephone can not recognize SIM-card or no SIM-card inserted. 
1 = Telephone has detected the SIM card.";
CM_ SG_ 1637 TF_Phone_Status "Anrufstatus
0: idle state / no call active
1: incoming call
2: 2nd incoming call / waiting call
3: active call / multiparty call
4: outgoing call";
CM_ SG_ 1637 TF_Telephone_State "This signal contain the information if a telephone call is active or not active.";

CM_ SG_ 2589283622 TLO_01_Zaehler "Zaehler wird inkrementiert, wenn sich die Zuordnung zu den Signalgruppen aendert.
z.B. Neuer MPP, Kreuzungsueberfahrt, neuer AIO Pfad";
CM_ SG_ 2589283622 TLO_HMI_Status "Aktueller Anzeigestatus";
CM_ SG_ 2589283622 TLO_LSA1_PSD_Seg_Offset "Offset auf PSD Segment";
CM_ SG_ 2589283622 TLO_LSA1_PSD_Segment_ID "PSD Segment ID auf den die Haltelinie verortet wurde";
CM_ SG_ 2589283622 TLO_LSA1_Zeit1_CF "Güte der prädizierten LSA1 Zeit1";
CM_ SG_ 2589283622 TLO_LSA1_Zeit1_Pred "Prädizierte LSA1 Zeit1";
CM_ SG_ 2589283622 TLO_LSA1_Zeit1_Status "Status der aktuellen LSA1 Zeit1";
CM_ SG_ 2589283622 TLO_LSA1_Zeit2_CF "Güte der prädizierten LSA1 Zeit2";
CM_ SG_ 2589283622 TLO_LSA1_Zeit2_Pred "Prädizierte LSA1 Zeit2";
CM_ SG_ 2589283622 TLO_LSA1_Zeit2_Status "Status der aktuellen LSA1 Zeit2";
CM_ SG_ 2589283622 TLO_StartStoppInfo "Stopp-Freigabe und Start-Anforderung an den Start-Stopp-Koordinator";

CM_ SG_ 2589283623 TLO_02_Zaehler "Zaehler wird inkrementiert, wenn sich die Zuordnung zu den Signalgruppen aendert.
z.B. Neuer MPP, Kreuzungsueberfahrt, neuer AIO Pfad";
CM_ SG_ 2589283623 TLO_LSA1_Layout "Ampelausrichtung für die Ampel, auf die man zufährt (Schaltzeiten in TLO_01).";
CM_ SG_ 2589283623 TLO_LSA2_PSD_Seg_Offset "Offset auf PSD Segment";
CM_ SG_ 2589283623 TLO_LSA2_PSD_Segment_ID "PSD Segment ID auf den die Haltelinie verortet wurde";
CM_ SG_ 2589283623 TLO_LSA2_Zeit1_CF "Güte der prädizierten LSA2 Zeit1";
CM_ SG_ 2589283623 TLO_LSA2_Zeit1_Pred "Prädizierte LSA2 Zeit1";
CM_ SG_ 2589283623 TLO_LSA2_Zeit1_Status "Status der aktuellen LSA2 Zeit1";
CM_ SG_ 2589283623 TLO_LSA2_Zeit2_CF "Güte der prädizierten LSA2 Zeit2";
CM_ SG_ 2589283623 TLO_LSA2_Zeit2_Pred "Prädizierte LSA2 Zeit2";
CM_ SG_ 2589283623 TLO_LSA2_Zeit2_Status "Status der aktuellen LSA2 Zeit2";

CM_ SG_ 1447 bCall_active "1: Breakdown call is active
0: BreakdownCall is inactive";
CM_ SG_ 1447 eCall_Funktionsstatus "HMI-Aufruf im Kombi (Broadcast)
Fehlerfälle die im Kombi angezeigt werden können";
CM_ SG_ 1447 eCall_Funktionsstatus_02 "Erweiterung des Funktionsstatus für andere Funktionen
ACN aktiv, MEC aktiv
MEC = manual emergency call = maueller Notruf
ACN = automatic emergency call = automatischer Notruf";
CM_ SG_ 1447 eCall_MCC "Mobile Country Code of the current mobile network
ITU-T E.212";
CM_ SG_ 1447 eCall_Mute_Anf "Signalisiert die Aufforderungen alle Soundquellen im Fahrzeug während eines aktiven Notrufs zu muten";
CM_ SG_ 1447 FaceRec_Enroll_Challenge_Request "When FaceRec on MIK receives this signal it will provide a challenge via SOK_FR_Enroll_MIK_Challenge.";
CM_ SG_ 1447 FoD_Anz_Funktionsabschaltung "Signal triggert Aufschaltung eines Popups, um dem Fahrer die Abschaltung einer Funktion zu melden.";
CM_ SG_ 1447 iCall_active "Statusrückmeldung von OCU über Infocall aktiv/inaktiv";
CM_ SG_ 1447 MOD_Energie_Anf "Anforderung Energieversorgung MOD-Job an das NVEM";
CM_ SG_ 1447 MOD_Request_ServiceKey "Sendet ein Signal zum ServiceKey-Master, welcher daraufhin einen aktuellen ServiceKey1c auf den Bus legt.";
CM_ SG_ 1447 ORU_KombiTimer "Ankündigung eines ORU OCU zum Kombi zur Darstellung entsprechender Symbole";
CM_ SG_ 1447 TM_Door_Lock "Remote Door lock angefordert: ZV zu/verriegeln";
CM_ SG_ 1447 TM_Door_Unlock "Remote Door unlock angefordert: ZV auf/entriegeln";
CM_ SG_ 1447 TM_Nur_Hupen "Remote Hupen (ohne Blinken) aktiviert";
CM_ SG_ 1447 TM_Panik_Alarm "Remote Hupen und Blinken aktiv";
CM_ SG_ 1447 TM_Spiegel_Anklappen "Anklappen der Außenspiegel über Remote MOD Anforderung";
CM_ SG_ 1447 TM_Warnblinken "Remote Blinken aktiviert";
CM_ SG_ 1447 TM_ZV_Signatur "Gespeicherte Signatur der ZV für Authentifizierung";

CM_ SG_ 977 ASW_Warnung_aktiv_BFS "Abschaltung der Ambientefunktion Beifahrertür bei aktiver ASW Warnung an der Fahrertür";
CM_ SG_ 977 BFS_Status_eTAG "Status des elektrischen Tueraussengriffes Beifahrertuer";
CM_ SG_ 977 BT_ASW_HMI_defekt "Zeigt an, ob die ASW-Anzeige defekt ist.";
CM_ SG_ 977 BT_EC_Spiegel_Helligkeit "Dimmung für den Aussenspiegel in %";
CM_ SG_ 977 BT_FH_Bew_hoch "Fensterheber in Bewegung Richtung hoch";
CM_ SG_ 977 BT_FH_Bew_tief "Fensterheber in Bewegung Richtung tief";
CM_ SG_ 977 BT_FH_Block "Fensterscheibe befindet sich im mechanischen Block (oben oder unten)";
CM_ SG_ 977 BT_FH_Fang "Fangbereich ist 4mm von oberer Lippendichtung";
CM_ SG_ 977 BT_FH_normiert "Die Position der Fensterheberscheibe ist bekannt";
CM_ SG_ 977 BT_FH_Oeffnung "Gibt den Fensteröffnungswert in % an.";
CM_ SG_ 977 BT_FH_S_AutoHoch "FH Schalter automatisch hoch gedrückt";
CM_ SG_ 977 BT_FH_S_AutoTief "FH Schalter automatisch tief gedrückt";
CM_ SG_ 977 BT_FH_S_ManHoch "FH Schalter manuell hoch gedrückt";
CM_ SG_ 977 BT_FH_S_ManTief "FH Schalter manuell tief gedrückt";
CM_ SG_ 977 BT_FH_Thermo "gibt an ob Fensterheber im Thermoschutz ist";
CM_ SG_ 977 BT_gesafet "Im Zustand Safe wird auch das Signal BT_verriegelt = 1 gesendet";
CM_ SG_ 977 BT_Kisi_Fehler "Fehlerstatus Kindersicherungsfunktion";
CM_ SG_ 977 BT_Lock_Taster "Verriegelungstaster";
CM_ SG_ 977 BT_Lock_Taster_inv "Lock Taster nicht betätigt";
CM_ SG_ 977 BT_Lock_Unlock_Taster "ZV Funktion Lock Unlock mit Toggle-Logik";
CM_ SG_ 977 BT_Oben_Block_erw "Fensterheber in Blockerwartung oben";
CM_ SG_ 977 BT_Schliesstaster "Schliesstaster Beifahrertür";
CM_ SG_ 977 BT_Schluesselschalter_auf "Schlüsselschalter Richtung auf betätigt";
CM_ SG_ 977 BT_Schluesselschalter_zu "Schluesselschalter Richtung zu betaetigt";
CM_ SG_ 977 BT_Schluesselschalter_zu_inv "Schluesselschalter zu nicht betaetigt";
CM_ SG_ 977 BT_SP_ausgerastet "Spiegel ausgerastet";
CM_ SG_ 977 BT_Sp_Blk_def "Blinker am Spiegel defekt";
CM_ SG_ 977 BT_SP_Heizung_aktiv "Zustand Spiegelheizung Beifahrertür";
CM_ SG_ 977 BT_Sp_Heizung_Anf "Kundenanforderung der Außenspiegelheizung Beifahrertür";
CM_ SG_ 977 BT_SP_Heizung_Status "Status der Spiegelheizung";
CM_ SG_ 977 BT_SP_ht_aktiv "Spiegelverstellung in Richtung hoch/tief aktiv";
CM_ SG_ 977 BT_SP_lr_aktiv "Spiegelverstellung in Richtung links/rechts aktiv";
CM_ SG_ 977 BT_Sperrklinke "Vorraste für Schloß

zwischen Vor- und Hauptraste Signal kurz auf 1, danach wieder auf 0 wenn Tür in Hauptraste (Tür ist sicher zu wenn Sperrklinke und Türkontakt auf 0 sind)";
CM_ SG_ 977 BT_SWA_HMI_defekt "Zeigt an, ob die SWA-Anzeige defekt ist.";
CM_ SG_ 977 BT_TAG_betaetigt "Türaussengriff";
CM_ SG_ 977 BT_TCR_Mode_aktiv "Signal zeigt eine aktive mechanische Redundanz am Türschloss an.";
CM_ SG_ 977 BT_TIG_betaetigt "Türinnengriff";
CM_ SG_ 977 BT_Tuer_geoeffnet "Zeigt eine geöffnete Tür an";
CM_ SG_ 977 BT_Tuer_Status "Türstatus mit Fehler und Initwert";
CM_ SG_ 977 BT_Tuer_Status_QBit "Dieses Bit gibt die Zuverlässigkeit des Türkontakts an. Ein auf dieses Bit folgender Fehlereintrag ist mit dem Sender des Bits abzustimmen (gültig ab PPE).";
CM_ SG_ 977 BT_Tueroeffnen_Warnung "Bit wird gesetzt, wenn Tür während der Fahrt geoeffnet werden soll.";
CM_ SG_ 977 BT_Tuerschloss_defekt "Das Beifahrertürschloss ist nicht mehr funktionsfähig.";
CM_ SG_ 977 BT_UEKB_aktiviert "Überschutzbegrenzungskraft bei Reversieren";
CM_ SG_ 977 BT_Unlock_Taster "Entriegelungstaster betätigt";
CM_ SG_ 977 BT_Unten_Block_erw "Fensterheber in Blockerwartung unten";
CM_ SG_ 977 BT_verriegelt "Zeigt eine verriegelte Tür an ( Status wird erst nach vollständiger Schlossansteuerung ausgegeben (<=1,5sek))";
CM_ SG_ 977 BT_Zuziehhilfe_aktiv "Zuziehhilfe aktiv";

CM_ SG_ 976 ASW_HMI_defekt "HMI Status der Funktion AusstiegsWarnung (ASW). HMI wird durch das TSG angesteuert.";
CM_ SG_ 976 ASW_wakeup "Trigger Start Nachlaufzeit t_1 für die Funktion Ausstieswarnung (ASW)";
CM_ SG_ 976 ASW_Warnung_aktiv_FS "Abschaltung der Ambientefunktion Fahrertür bei aktiver ASW Warnung an der Fahrertür";
CM_ SG_ 976 FS_Status_eTAG "Status des elektrischen Tueraussengriffes Fahrertuer";
CM_ SG_ 976 FT_BFS_Fond_Freigabe "Freigabe für Fondverstellung";
CM_ SG_ 976 FT_Daemmglas "Daemmglas verbaut";
CM_ SG_ 976 FT_FH_Bew_hoch "Fensterheber in Bewegung Richtung hoch";
CM_ SG_ 976 FT_FH_Bew_tief "Fensterheber in Bewegung Richtung tief";
CM_ SG_ 976 FT_FH_Block "Fensterscheibe befindet sich im mechanischen Block (oben oder unten)";
CM_ SG_ 976 FT_FH_Fang "Fangbereich ist 4mm von oberer Lippendichtung";
CM_ SG_ 976 FT_FH_normiert "Die Position der Fensterheberscheibe ist bekannt";
CM_ SG_ 976 FT_FH_Oeffnung "Gibt den Fensteröffnungswert in % an.";
CM_ SG_ 976 FT_FH_S_AutoHoch "FH Schalter automatisch hoch gedrückt";
CM_ SG_ 976 FT_FH_S_AutoTief "FH Schalter automatisch tief gedrückt";
CM_ SG_ 976 FT_FH_S_ManHoch "FH Schalter manuell hoch gedrückt";
CM_ SG_ 976 FT_FH_S_ManTief "FH Schalter manuell tief gedrückt";
CM_ SG_ 976 FT_FH_Thermo "gibt an ob Fensterheber im Thermoschutz ist";
CM_ SG_ 976 FT_gesafet "Im Zustand Safe wird auch das Signal FT_verriegelt = 1 gesendet";
CM_ SG_ 976 FT_HD_Taste "Taste in der Fahrertür zum Öffnen des Heckschlosses";
CM_ SG_ 976 FT_HD_Taste_2 "2. HD-Taste im Bedienfeld 
Funktion: Heckdeckel schließen";
CM_ SG_ 976 FT_IRUE_Taste "Betätigung IRUE-Taster (Innenraumüberwachung)
MQB: Bei Verbau eines einzelnen Taster zur Deaktivierung von IRUE und NGS wird dieses Signal als Deaktivierungsanforderung beider DWA-Alarmquellen gesendet.";
CM_ SG_ 976 FT_Kisi_Fehler "Fehlerstatus Kindersicherungsfunktion";
CM_ SG_ 976 FT_Kisi_li_aktiv "Aktivierungsstatus der Kindersicherung links";
CM_ SG_ 976 FT_Kisi_re_aktiv "Aktivierungsstatus der Kindersicherung rechts";
CM_ SG_ 976 FT_Kisi_Taster_li "Linker Kisi Taster betaetigt";
CM_ SG_ 976 FT_Kisi_Taster_re "Rechter Kisi Taster betaetigt";
CM_ SG_ 976 FT_Lock_Taster "Verriegelungstaster betätigt";
CM_ SG_ 976 FT_Lock_Unlock_Taster "ZV Funktion Lock Unlock mit Toggle-Logik";
CM_ SG_ 976 FT_Oben_Block_erw "Fensterheber in Blockerwartung oben";
CM_ SG_ 976 FT_Schliesstaster "Vorhalt";
CM_ SG_ 976 FT_Schluesselschalter_auf "Schlüsselschalter Richtung auf betätigt";
CM_ SG_ 976 FT_SP_ausgerastet "Spiegel ausgerastet";
CM_ SG_ 976 FT_Sp_Blk_def "Blinker am Spiegel defekt";
CM_ SG_ 976 FT_Sp_Heizung_Anf "Kundenanforderung der Außenspiegelheizung Fahrertür";
CM_ SG_ 976 FT_SP_Heizung_Status "Status der Spiegelheizung";
CM_ SG_ 976 FT_SP_ht_aktiv "Spiegelverstellung in Richtung hoch/tief aktiv";
CM_ SG_ 976 FT_SP_lr_aktiv "Spiegelverstellung in Richtung links/rechts aktiv";
CM_ SG_ 976 FT_Sperrklinke "Vorraste für Schloß

zwischen Vor- und Hauptraste Signal kurz auf 1, danach wieder auf 0 wenn Tür in Hauptraste (Tür ist sicher zu wenn Sperrklinke und Türkontakt auf 0 sind)";
CM_ SG_ 976 FT_SWA_Taster "SWA/ASW Taster Fahrertür";
CM_ SG_ 976 FT_TAG_betaetigt "Türaussengriff

wird nicht im MLB-B8 verwendet";
CM_ SG_ 976 FT_TD_Taste "Tankdeckelentriegelungs-Taste betätigt";
CM_ SG_ 976 FT_TD_Taste_Fehler "Fehlerstatus des Tankdeckelentriegelungstasters. Wird bei Drucktankkonzepten vom MSG zusammen mit dem Signal FT_TD_Taste ausgewertet, um Tankbereitschaft herzustellen.
Der Fehler beschreibt einen hängenden TD_Taster. Ein Kurzschluss oder Leitungsunterbre";
CM_ SG_ 976 FT_TIG_betaetigt "Türinnengriff

wird nicht im MLB-B8 verwendet";
CM_ SG_ 976 FT_Tuer_geoeffnet "Zeigt eine geöffnete Tür an";
CM_ SG_ 976 FT_Tuerschloss_defekt "Das Fahrertürschloss ist nicht mehr funktionsfähig.";
CM_ SG_ 976 FT_UEKB_aktiviert "Überschutzbegrenzungskraft bei Reversieren";
CM_ SG_ 976 FT_Unlock_Taster "Entriegelungstaster betätigt";
CM_ SG_ 976 FT_Unten_Block_erw "Fensterheber in Blockerwartung unten";
CM_ SG_ 976 FT_verriegelt "Zeigt eine verriegelte Tür an ( Status wird erst nach vollständiger Schlossansteuerung ausgegeben (<=1,5sek))";
CM_ SG_ 976 FT_Zuziehhilfe_aktiv "Zuziehhilfe aktiv";
CM_ SG_ 976 SSR_Temp_Freigabe "Freigabe des Seitenscheibenrollos. Bit wird  für die Deaktivierung des SSR bei Innenraumtemperaturen kleiner -10 Grad verwendet.";
CM_ SG_ 976 SWA_HMI_Diagnose "SWA HMI Diagnose beim TSG";

CM_ SG_ 997 eTAB_FS_Bowdenzug_Auswerfen "Soll den Bowdenzug für die mechanische Redundanz";
CM_ SG_ 997 FS_Push_Tuergriff "Push zum Ausfahren der Flush-Tuergriffe";
CM_ SG_ 997 FS_Status_eTAG_ext "erweitert um den Wert 'verfährt'";
CM_ SG_ 997 FT_ASW_Warnton "erzeugt ein Warnton bei AS Warnung";
CM_ SG_ 997 FT_BFS_Tuer_Status "Gesammelte Türstatusbotschaft";
CM_ SG_ 997 FT_Cargolock_bet "CargoLock-Taste betätigt";
CM_ SG_ 997 FT_HBFS_Tuer_Status "Türstatus mit Fehler und Initwert";
CM_ SG_ 997 FT_HFS_Tuer_Status "Türstatus mit Fehler und Initwert";
CM_ SG_ 997 FT_kisi_asynchron "Signal erzeugt eine seperate Warnmeldung bei ungewollter Asynchronität der 'elektrische Kindersicherung' der Schlösser.";
CM_ SG_ 997 FT_KiSi_Status_Soll_HBFS "Soll KiSi Status HBFS";
CM_ SG_ 997 FT_KiSi_Status_Soll_HFS "Soll Status der KiSi HFS";
CM_ SG_ 997 FT_Kisi_Taster_li_02 "Der Kindersicherungstaster hinten links aktiv.";
CM_ SG_ 997 FT_Kisi_Taster_re_02 "Der Kindersicherungstaster hinten rechts aktiv.";
CM_ SG_ 997 FT_Lock_Taster_02 "Lock-Taster betätigt";
CM_ SG_ 997 FT_Schluesselschalter_zu_02 "Schlüsselschalter für Schließen betätigt";
CM_ SG_ 997 FT_SP_Heizung_ein "Dieses Signal zeigt die tatsächliche Ansteuerung der  Spiegelheizung incl. PWM an. 
Zudem wird aufgrund des Teilnetzbetriebs das Signal zur Ansteuerung der Beifahrer-Spiegelheizung benutzt.

";
CM_ SG_ 997 FT_TCR_Mode_aktiv "Signal zeigt eine aktive mechanische Redundanz am Türschloss an.";
CM_ SG_ 997 FT_TD_Taste_Status "Status Taste für Tankdeckel";
CM_ SG_ 997 FT_Tuer_Status "Tür geöffnet oder Tür geschlossen";
CM_ SG_ 997 FT_Tuer_Status_QBit "Dieses Bit gibt die Zuverlässigkeit des Türkontakts an. Ein auf dieses Bit folgender Fehlereintrag ist mit dem Sender des Bits abzustimmen (gültig ab PPE).";
CM_ SG_ 997 FT_Tueroeffnen_Warnung "Bit wird gesetzt, wenn Tür während der Fahrt geoeffnet werden soll.";
CM_ SG_ 997 SSA_FT_ASW_Status "SmartSensorActor:
Rückmeldung des Status der ASW Anzeige.";
CM_ SG_ 997 TBF_FS_Touch_Event "Touch_Events für Informationen einer Funktionsauslösung auf dem TBF, welche dann für bspw. ein akustisches Signal zentral umgesetzt werden können.";
CM_ SG_ 997 TSG_FS_Spiegel_angeklappt "Funktionsrückmeldung TSG_FS über Spiegelstellung angeklappt";
CM_ SG_ 997 TSG_FT_02_BZ "4bit Botschaftszaehler, wird mit jeder Sendebotschaft inkrementiert";
CM_ SG_ 997 TSG_FT_02_CRC "Für MLB:
'Berechnung siehe Lastenheft 'Kommunikationsabsicherung für FlexRay und CAN''

Ab MQB und MLBevo:
'Berechnung siehe Lastenheft 'End-to-End Kommunikationsabsicherung''

Endwerte siehe Begleitdokument 'S-PDU Kennungsfolgen'";
BA_DEF_REL_ BU_SG_REL_  "GenSigTimeoutTime" INT 0 65535;
BA_DEF_ BO_  "DiagRequest" ENUM "No", "Yes";
BA_DEF_ BO_  "DiagResponse" ENUM "No", "Yes";
BA_DEF_ BO_  "DiagState" ENUM "No", "Yes";
BA_DEF_ BO_  "GenMsgChkConstant" HEX 0 4095;
BA_DEF_ BO_  "GenMsgCycleTime" INT 0 65535;
BA_DEF_ BO_  "GenMsgCycleTimeFast" INT 0 65535;
BA_DEF_ BO_  "GenMsgDelayTime" INT 0 100000;
BA_DEF_ BO_  "GenMsgILSupport" ENUM "No", "Yes";
BA_DEF_ BO_  "GenMsgNrOfRepetition" INT 0 100;
BA_DEF_ BO_  "GenMsgPDUConstants" STRING;
BA_DEF_ BO_  "GenMsgSendType" ENUM "Cyclic", "not_used", "not_used", "not_used", "not_used", "not_used", "not_used", "IfActive", "NoMsgSendType";
BA_DEF_ BO_  "GenMsgStartDelayTime" INT 0 100000;
BA_DEF_ BO_  "NmMessage" ENUM "No", "Yes";
BA_DEF_ BO_  "NmhMessage" ENUM "No", "Yes";
BA_DEF_ BO_  "MsgType" ENUM "Application", "NM ", "NMH", "TP2.0", "ISO-TP ", "BAP", "EID", "KS", "XCP_PRE_CONFIGURED", "XCP_RUNTIME_CONFIGURED";
BA_DEF_ BO_  "VAGTP20_API" HEX 0 255;
BA_DEF_ BO_  "VAGTP20_DynConnection" ENUM "No", "Yes";
BA_DEF_ BO_  "VAGTP20_DynSetup" ENUM "No", "Yes";
BA_DEF_ BO_  "VAGTP20_StatConnection" ENUM "No", "Yes";
BA_DEF_ SG_  "GenSigActiveRepetitions" INT -2147483648 2147483647;
BA_DEF_ SG_  "GenSigInactiveValue" INT -2147483648 2147483647;
BA_DEF_ SG_  "GenSigSendType" ENUM "Cyclic", "OnWrite", "OnWriteWithRepetition", "OnChange", "OnChangeWithRepetition", "IfActive", "IfActiveWithRepetition", "NoSigSendType", "OnChangeAndIfActive", "OnChangeAndIfActiveWithRepetition";
BA_DEF_ SG_  "GenSigStartValue" INT -2147483648 2147483647;
BA_DEF_ SG_  "NWM-WakeupAllowed" ENUM "No", "Yes";
BA_DEF_ SG_  "GenSigFuncType" ENUM "NoFunction", "MsgCounter", "CRC-8", "XOR", "XOR-2", "DatedBit", "SW-Kl15", "CHK", "Constant", "Protocol", "CRC-8-SAE_J1850", "CRC-32", "DataLength", "DataID", "MsgCounter16", "SOK-Signatur", "Cluster";
BA_DEF_ SG_  "GenSigSwitchedByIgnition" ENUM "No", "Yes";
BA_DEF_ SG_  "Fehlerwert" HEX 0 2147483647;
BA_DEF_ SG_  "GenSigMissingSourceValue" HEX 0 2147483647;
BA_DEF_DEF_REL_  "GenSigTimeoutTime" 0;
BA_DEF_DEF_  "DiagRequest" "No";
BA_DEF_DEF_  "DiagResponse" "No";
BA_DEF_DEF_  "DiagState" "No";
BA_DEF_DEF_  "GenMsgChkConstant" 0;
BA_DEF_DEF_  "GenMsgCycleTime" 0;
BA_DEF_DEF_  "GenMsgCycleTimeFast" 0;
BA_DEF_DEF_  "GenMsgDelayTime" 0;
BA_DEF_DEF_  "GenMsgILSupport" "No";
BA_DEF_DEF_  "GenMsgNrOfRepetition" 0;
BA_DEF_DEF_  "GenMsgPDUConstants" "";
BA_DEF_DEF_  "GenMsgSendType" "NoMsgSendType";
BA_DEF_DEF_  "GenMsgStartDelayTime" 0;
BA_DEF_DEF_  "NmMessage" "No";
BA_DEF_DEF_  "NmhMessage" "No";
BA_DEF_DEF_  "MsgType" "Application";
BA_DEF_DEF_  "VAGTP20_API" 0;
BA_DEF_DEF_  "VAGTP20_DynConnection" "No";
BA_DEF_DEF_  "VAGTP20_DynSetup" "No";
BA_DEF_DEF_  "VAGTP20_StatConnection" "No";
BA_DEF_DEF_  "GenSigActiveRepetitions" 0;
BA_DEF_DEF_  "GenSigInactiveValue" 0;
BA_DEF_DEF_  "GenSigSendType" "NoSigSendType";
BA_DEF_DEF_  "GenSigStartValue" 0;
BA_DEF_DEF_  "NWM-WakeupAllowed" "No";
BA_DEF_DEF_  "GenSigFuncType" "NoFunction";
BA_DEF_DEF_  "GenSigSwitchedByIgnition" "Yes";
BA_DEF_DEF_  "Fehlerwert" 0;
BA_DEF_DEF_  "GenSigMissingSourceValue" 0;
BA_ "GenMsgCycleTime" BO_ 1529 500;
BA_ "GenMsgILSupport" BO_ 1529 1;
BA_ "GenMsgSendType" BO_ 1529 0;
BA_ "GenMsgCycleTime" BO_ 1711 1000;
BA_ "GenMsgDelayTime" BO_ 1711 50;
BA_ "GenMsgILSupport" BO_ 1711 1;
BA_ "GenMsgSendType" BO_ 1711 0;
BA_ "GenMsgCycleTime" BO_ 2463978734 100;
BA_ "GenMsgDelayTime" BO_ 2463978734 50;
BA_ "GenMsgILSupport" BO_ 2463978734 1;
BA_ "GenMsgSendType" BO_ 2463978734 0;
BA_ "GenMsgCycleTime" BO_ 1527 1000;
BA_ "GenMsgDelayTime" BO_ 1527 100;
BA_ "GenMsgILSupport" BO_ 1527 1;
BA_ "GenMsgSendType" BO_ 1527 0;
BA_ "GenMsgCycleTime" BO_ 1610 500;
BA_ "GenMsgILSupport" BO_ 1610 1;
BA_ "GenMsgSendType" BO_ 1610 0;
BA_ "GenMsgCycleTime" BO_ 1440 200;
BA_ "GenMsgILSupport" BO_ 1440 1;
BA_ "GenMsgSendType" BO_ 1440 0;
BA_ "GenMsgCycleTime" BO_ 1504 500;
BA_ "GenMsgCycleTimeFast" BO_ 1504 100;
BA_ "GenMsgDelayTime" BO_ 1504 50;
BA_ "GenMsgILSupport" BO_ 1504 1;
BA_ "GenMsgNrOfRepetition" BO_ 1504 5;
BA_ "GenMsgSendType" BO_ 1504 0;
BA_ "GenMsgCycleTimeFast" BO_ 2463978605 100;
BA_ "GenMsgILSupport" BO_ 2463978605 1;
BA_ "GenMsgSendType" BO_ 2463978605 7;
BA_ "GenMsgCycleTime" BO_ 873 80;
BA_ "GenMsgILSupport" BO_ 873 1;
BA_ "GenMsgSendType" BO_ 873 0;
BA_ "GenMsgCycleTimeFast" BO_ 1167 100;
BA_ "GenMsgILSupport" BO_ 1167 1;
BA_ "GenMsgSendType" BO_ 1167 7;
BA_ "GenMsgCycleTime" BO_ 1363 100;
BA_ "GenMsgILSupport" BO_ 1363 1;
BA_ "GenMsgPDUConstants" BO_ 1363 "0xeb,0x5b,0xa9,0xb2,0x89,0x1d,0x73,0xcb,0xe6,0xcc,0x1c,0xc3,0x5f,0x78,0xc5,0x1f";
BA_ "GenMsgSendType" BO_ 1363 0;
BA_ "GenMsgCycleTime" BO_ 980 1000;
BA_ "GenMsgCycleTimeFast" BO_ 980 100;
BA_ "GenMsgDelayTime" BO_ 980 50;
BA_ "GenMsgILSupport" BO_ 980 1;
BA_ "GenMsgNrOfRepetition" BO_ 980 5;
BA_ "GenMsgPDUConstants" BO_ 980 "0xc3,0x79,0xbf,0xdb,0xe9,0x11,0x46,0x86,0x69,0xb6,0x9b,0x29,0x15,0x9c,0x45,0x0d";
BA_ "GenMsgSendType" BO_ 980 0;
BA_ "GenMsgDelayTime" BO_ 2464161907 50;
BA_ "GenMsgILSupport" BO_ 2464161907 1;
BA_ "GenMsgDelayTime" BO_ 2464301171 50;
BA_ "GenMsgILSupport" BO_ 2464301171 1;
BA_ "GenMsgDelayTime" BO_ 2589283756 100;
BA_ "GenMsgILSupport" BO_ 2589283756 1;
BA_ "GenMsgDelayTime" BO_ 2464153703 100;
BA_ "GenMsgILSupport" BO_ 2464153703 1;
BA_ "GenMsgDelayTime" BO_ 2464284775 100;
BA_ "GenMsgDelayTime" BO_ 2464288871 100;
BA_ "GenMsgILSupport" BO_ 2464288871 1;
BA_ "GenMsgDelayTime" BO_ 2464153715 100;
BA_ "GenMsgILSupport" BO_ 2464153715 1;
BA_ "GenMsgDelayTime" BO_ 2464288883 100;
BA_ "GenMsgDelayTime" BO_ 2464292979 100;
BA_ "GenMsgILSupport" BO_ 2464292979 1;
BA_ "GenMsgCycleTime" BO_ 1467 500;
BA_ "GenMsgILSupport" BO_ 1467 1;
BA_ "GenMsgSendType" BO_ 1467 0;
BA_ "GenMsgCycleTime" BO_ 1313 200;
BA_ "GenMsgILSupport" BO_ 1313 1;
BA_ "GenMsgSendType" BO_ 1313 0;
BA_ "GenMsgCycleTime" BO_ 673 200;
BA_ "GenMsgDelayTime" BO_ 673 50;
BA_ "GenMsgILSupport" BO_ 673 1;
BA_ "GenMsgSendType" BO_ 673 0;
BA_ "GenMsgCycleTime" BO_ 1413 1000;
BA_ "GenMsgDelayTime" BO_ 1413 10;
BA_ "GenMsgILSupport" BO_ 1413 1;
BA_ "GenMsgSendType" BO_ 1413 0;
BA_ "GenMsgCycleTime" BO_ 1637 1000;
BA_ "GenMsgDelayTime" BO_ 1637 100;
BA_ "GenMsgILSupport" BO_ 1637 1;
BA_ "GenMsgSendType" BO_ 1637 0;
BA_ "GenMsgCycleTime" BO_ 2589283622 1000;
BA_ "GenMsgDelayTime" BO_ 2589283622 200;
BA_ "GenMsgILSupport" BO_ 2589283622 1;
BA_ "GenMsgSendType" BO_ 2589283622 0;
BA_ "GenMsgCycleTime" BO_ 2589283623 1000;
BA_ "GenMsgDelayTime" BO_ 2589283623 200;
BA_ "GenMsgILSupport" BO_ 2589283623 1;
BA_ "GenMsgSendType" BO_ 2589283623 0;
BA_ "GenMsgCycleTime" BO_ 1447 1000;
BA_ "GenMsgCycleTimeFast" BO_ 1447 100;
BA_ "GenMsgDelayTime" BO_ 1447 50;
BA_ "GenMsgILSupport" BO_ 1447 1;
BA_ "GenMsgSendType" BO_ 1447 0;
BA_ "GenMsgCycleTime" BO_ 977 100;
BA_ "GenMsgDelayTime" BO_ 977 20;
BA_ "GenMsgILSupport" BO_ 977 1;
BA_ "GenMsgSendType" BO_ 977 0;
BA_ "GenMsgCycleTime" BO_ 976 100;
BA_ "GenMsgDelayTime" BO_ 976 20;
BA_ "GenMsgILSupport" BO_ 976 1;
BA_ "GenMsgSendType" BO_ 976 0;
BA_ "GenMsgCycleTime" BO_ 997 100;
BA_ "GenMsgDelayTime" BO_ 997 20;
BA_ "GenMsgILSupport" BO_ 997 1;
BA_ "GenMsgPDUConstants" BO_ 997 "0xc4,0x6a,0x69,0x30,0xcf,0x61,0x58,0x51,0x1b,0x86,0x99,0xd3,0xf6,0x1d,0x9a,0x37";
BA_ "GenMsgSendType" BO_ 997 0;
BA_ "GenSigSendType" SG_ 1529 RDK_angelernt 0;
BA_ "GenSigSwitchedByIgnition" SG_ 1529 RDK_angelernt 0;
BA_ "GenSigSendType" SG_ 1529 RDK_FMVSS138_Lampe 0;
BA_ "GenSigSwitchedByIgnition" SG_ 1529 RDK_FMVSS138_Lampe 0;
BA_ "GenSigSendType" SG_ 1529 RDK_FMVSS138_MIL 0;
BA_ "GenSigSwitchedByIgnition" SG_ 1529 RDK_FMVSS138_MIL 0;
BA_ "GenSigSendType" SG_ 1529 RDK_Kalibrierung 0;
BA_ "GenSigSwitchedByIgnition" SG_ 1529 RDK_Kalibrierung 0;
BA_ "GenSigSendType" SG_ 1529 RDK_Reifendruck_Lampe 0;
BA_ "GenSigSwitchedByIgnition" SG_ 1529 RDK_Reifendruck_Lampe 0;
BA_ "GenSigSendType" SG_ 1529 RDK_Reifentemperatur_Lampe 0;
BA_ "GenSigSwitchedByIgnition" SG_ 1529 RDK_Reifentemperatur_Lampe 0;
BA_ "GenSigSendType" SG_ 1529 RDK_RS_aktiv 0;
BA_ "GenSigSwitchedByIgnition" SG_ 1529 RDK_RS_aktiv 0;
BA_ "GenSigSendType" SG_ 1529 RDK_Text_7 0;
BA_ "GenSigSwitchedByIgnition" SG_ 1529 RDK_Text_7 0;
BA_ "GenSigSendType" SG_ 1529 RDK_W_1_Reifen_HL 0;
BA_ "GenSigSwitchedByIgnition" SG_ 1529 RDK_W_1_Reifen_HL 0;
BA_ "GenSigSendType" SG_ 1529 RDK_W_1_Reifen_HR 0;
BA_ "GenSigSwitchedByIgnition" SG_ 1529 RDK_W_1_Reifen_HR 0;
BA_ "GenSigSendType" SG_ 1529 RDK_W_1_Reifen_VL 0;
BA_ "GenSigSwitchedByIgnition" SG_ 1529 RDK_W_1_Reifen_VL 0;
BA_ "GenSigSendType" SG_ 1529 RDK_W_1_Reifen_VR 0;
BA_ "GenSigSwitchedByIgnition" SG_ 1529 RDK_W_1_Reifen_VR 0;
BA_ "GenSigSendType" SG_ 1529 RDK_W_2_Reifen_HL 0;
BA_ "GenSigSwitchedByIgnition" SG_ 1529 RDK_W_2_Reifen_HL 0;
BA_ "GenSigSendType" SG_ 1529 RDK_W_2_Reifen_HR 0;
BA_ "GenSigSwitchedByIgnition" SG_ 1529 RDK_W_2_Reifen_HR 0;
BA_ "GenSigSendType" SG_ 1529 RDK_W_2_Reifen_VL 0;
BA_ "GenSigSwitchedByIgnition" SG_ 1529 RDK_W_2_Reifen_VL 0;
BA_ "GenSigSendType" SG_ 1529 RDK_W_2_Reifen_VR 0;
BA_ "GenSigSwitchedByIgnition" SG_ 1529 RDK_W_2_Reifen_VR 0;
BA_ "GenSigSendType" SG_ 1529 RDK_Warnungen_02 0;
BA_ "GenSigSwitchedByIgnition" SG_ 1529 RDK_Warnungen_02 0;
BA_ "GenSigSendType" SG_ 1711 RV_Calib_Fehler 3;
BA_ "GenSigSwitchedByIgnition" SG_ 1711 RV_Calib_Fehler 0;
BA_ "GenSigSendType" SG_ 1711 RV_Dark_Screen 3;
BA_ "GenSigSwitchedByIgnition" SG_ 1711 RV_Dark_Screen 0;
BA_ "GenSigSendType" SG_ 1711 RV_Farbe 3;
BA_ "GenSigSwitchedByIgnition" SG_ 1711 RV_Farbe 0;
BA_ "GenSigSendType" SG_ 1711 RV_GL_LWS_Fehler 3;
BA_ "GenSigSwitchedByIgnition" SG_ 1711 RV_GL_LWS_Fehler 0;
BA_ "GenSigSendType" SG_ 1711 RV_GL_side 3;
BA_ "GenSigSendType" SG_ 1711 RV_GL_Trailer_connect 3;
BA_ "GenSigSwitchedByIgnition" SG_ 1711 RV_GL_Trailer_connect 0;
BA_ "GenSigSendType" SG_ 1711 RV_GL_Trunk_open 3;
BA_ "GenSigSwitchedByIgnition" SG_ 1711 RV_GL_Trunk_open 0;
BA_ "GenSigSendType" SG_ 1711 RV_Helligkeit 3;
BA_ "GenSigSwitchedByIgnition" SG_ 1711 RV_Helligkeit 0;
BA_ "GenSigSendType" SG_ 1711 RV_HMI_Mode 3;
BA_ "GenSigSwitchedByIgnition" SG_ 1711 RV_HMI_Mode 0;
BA_ "GenSigSendType" SG_ 1711 RV_Kontrast 3;
BA_ "GenSigSwitchedByIgnition" SG_ 1711 RV_Kontrast 0;
BA_ "GenSigSendType" SG_ 1711 RV_Menu_Item 3;
BA_ "GenSigSwitchedByIgnition" SG_ 1711 RV_Menu_Item 0;
BA_ "GenSigSendType" SG_ 1711 RV_Reinigung_Anf 3;
BA_ "GenSigSwitchedByIgnition" SG_ 1711 RV_Reinigung_Anf 0;
BA_ "GenSigSendType" SG_ 1711 RV_Settings_enabled 3;
BA_ "GenSigSwitchedByIgnition" SG_ 1711 RV_Settings_enabled 0;
BA_ "GenSigSendType" SG_ 1711 RV_System_aktiv 3;
BA_ "GenSigSwitchedByIgnition" SG_ 1711 RV_System_aktiv 0;
BA_ "GenSigSendType" SG_ 1711 RV_Video_on 3;
BA_ "GenSigSwitchedByIgnition" SG_ 1711 RV_Video_on 0;
BA_ "GenSigSendType" SG_ 1711 SV_Video_on 3;
BA_ "GenSigSendType" SG_ 1711 ZFAS_Umfeldbeleuchtung_Anf 3;
BA_ "GenSigSwitchedByIgnition" SG_ 1711 ZFAS_Umfeldbeleuchtung_Anf 0;
BA_ "GenSigSendType" SG_ 2463978734 SLCV_PaCo_CurrentView 3;
BA_ "GenSigSwitchedByIgnition" SG_ 2463978734 SLCV_PaCo_CurrentView 0;
BA_ "GenSigSendType" SG_ 2463978734 SLCV_PaCo_MainState 3;
BA_ "GenSigSwitchedByIgnition" SG_ 2463978734 SLCV_PaCo_MainState 0;
BA_ "Fehlerwert" SG_ 2463978734 SLCV_PaCo_MainState 7;
BA_ "GenSigSendType" SG_ 2463978734 VPS_PaCo_Button 0;
BA_ "GenSigSwitchedByIgnition" SG_ 2463978734 VPS_PaCo_Button 0;
BA_ "GenSigSendType" SG_ 2463978734 VPS_PaCo_CurrentBirdview 3;
BA_ "GenSigSwitchedByIgnition" SG_ 2463978734 VPS_PaCo_CurrentBirdview 0;
BA_ "GenSigSendType" SG_ 2463978734 VPS_PaCo_CurrentBowl 3;
BA_ "GenSigSwitchedByIgnition" SG_ 2463978734 VPS_PaCo_CurrentBowl 0;
BA_ "GenSigSendType" SG_ 2463978734 VPS_PaCo_CurrentCarOverlay 3;
BA_ "GenSigSendType" SG_ 2463978734 VPS_PaCo_CurrentMode 3;
BA_ "GenSigSwitchedByIgnition" SG_ 2463978734 VPS_PaCo_CurrentMode 0;
BA_ "GenSigSendType" SG_ 2463978734 VPS_PaCo_CurrentRVCscreen 3;
BA_ "GenSigSwitchedByIgnition" SG_ 2463978734 VPS_PaCo_CurrentRVCscreen 0;
BA_ "GenSigSendType" SG_ 2463978734 VPS_PaCo_CurrentVideoState 3;
BA_ "GenSigSwitchedByIgnition" SG_ 2463978734 VPS_PaCo_CurrentVideoState 0;
BA_ "GenSigSendType" SG_ 2463978734 VPS_PaCo_CurrentView 3;
BA_ "GenSigSwitchedByIgnition" SG_ 2463978734 VPS_PaCo_CurrentView 0;
BA_ "GenSigSendType" SG_ 2463978734 VPS_PaCo_CurrGraphOverlay 3;
BA_ "GenSigSwitchedByIgnition" SG_ 2463978734 VPS_PaCo_CurrGraphOverlay 0;
BA_ "GenSigSendType" SG_ 2463978734 VPS_PaCo_MainState 0;
BA_ "GenSigSwitchedByIgnition" SG_ 2463978734 VPS_PaCo_MainState 0;
BA_ "Fehlerwert" SG_ 2463978734 VPS_PaCo_MainState 7;
BA_ "GenSigSendType" SG_ 1527 RW_Gesamt_Reichweite_Anzeige 0;
BA_ "GenSigStartValue" SG_ 1527 RW_Gesamt_Reichweite_Anzeige 2046;
BA_ "GenSigSwitchedByIgnition" SG_ 1527 RW_Gesamt_Reichweite_Anzeige 0;
BA_ "Fehlerwert" SG_ 1527 RW_Gesamt_Reichweite_Anzeige 2047;
BA_ "GenSigSendType" SG_ 1527 RW_Primaer_Reichweite_Anzeige 0;
BA_ "GenSigStartValue" SG_ 1527 RW_Primaer_Reichweite_Anzeige 2046;
BA_ "GenSigSwitchedByIgnition" SG_ 1527 RW_Primaer_Reichweite_Anzeige 0;
BA_ "Fehlerwert" SG_ 1527 RW_Primaer_Reichweite_Anzeige 2047;
BA_ "GenSigSendType" SG_ 1527 RW_Reichweite_Einheit_Anzeige 0;
BA_ "GenSigSwitchedByIgnition" SG_ 1527 RW_Reichweite_Einheit_Anzeige 0;
BA_ "GenSigSendType" SG_ 1527 RW_Reservewarnung_aktiv 0;
BA_ "GenSigSwitchedByIgnition" SG_ 1527 RW_Reservewarnung_aktiv 0;
BA_ "GenSigSendType" SG_ 1527 RW_Sek_Reichweitenv_Einheit 0;
BA_ "GenSigStartValue" SG_ 1527 RW_Sek_Reichweitenv_Einheit 3;
BA_ "GenSigSwitchedByIgnition" SG_ 1527 RW_Sek_Reichweitenv_Einheit 0;
BA_ "GenSigSendType" SG_ 1527 RW_Sek_Reichweitenverbrauch 0;
BA_ "GenSigStartValue" SG_ 1527 RW_Sek_Reichweitenverbrauch 2047;
BA_ "GenSigSwitchedByIgnition" SG_ 1527 RW_Sek_Reichweitenverbrauch 0;
BA_ "GenSigSendType" SG_ 1527 RW_Sekundaer_Reichweite 0;
BA_ "GenSigStartValue" SG_ 1527 RW_Sekundaer_Reichweite 2046;
BA_ "GenSigSwitchedByIgnition" SG_ 1527 RW_Sekundaer_Reichweite 0;
BA_ "Fehlerwert" SG_ 1527 RW_Sekundaer_Reichweite 2047;
BA_ "GenSigSendType" SG_ 1527 RW_Sekundaer_Reichweite_Anzeige 0;
BA_ "GenSigStartValue" SG_ 1527 RW_Sekundaer_Reichweite_Anzeige 2046;
BA_ "GenSigSwitchedByIgnition" SG_ 1527 RW_Sekundaer_Reichweite_Anzeige 0;
BA_ "Fehlerwert" SG_ 1527 RW_Sekundaer_Reichweite_Anzeige 2047;
BA_ "GenSigSendType" SG_ 1527 RW_Tendenz 0;
BA_ "GenSigSwitchedByIgnition" SG_ 1527 RW_Tendenz 0;
BA_ "GenSigSendType" SG_ 1527 RW_Texte 3;
BA_ "GenSigSwitchedByIgnition" SG_ 1527 RW_Texte 0;
BA_ "GenSigSendType" SG_ 1610 RKA_FMVSS138_Lampe 0;
BA_ "GenSigSwitchedByIgnition" SG_ 1610 RKA_FMVSS138_Lampe 0;
BA_ "GenSigSendType" SG_ 1610 RKA_FMVSS138_MIL 0;
BA_ "GenSigSwitchedByIgnition" SG_ 1610 RKA_FMVSS138_MIL 0;
BA_ "GenSigSendType" SG_ 1610 RKA_Reifentyp 0;
BA_ "GenSigSwitchedByIgnition" SG_ 1610 RKA_Reifentyp 0;
BA_ "GenSigSendType" SG_ 1610 RKA_Warnungen_02 0;
BA_ "GenSigSwitchedByIgnition" SG_ 1610 RKA_Warnungen_02 0;
BA_ "GenSigSendType" SG_ 1440 LS_defekt 0;
BA_ "GenSigSwitchedByIgnition" SG_ 1440 LS_defekt 0;
BA_ "GenSigSendType" SG_ 1440 LS_Helligkeit_FW 0;
BA_ "GenSigStartValue" SG_ 1440 LS_Helligkeit_FW 1022;
BA_ "GenSigSwitchedByIgnition" SG_ 1440 LS_Helligkeit_FW 0;
BA_ "Fehlerwert" SG_ 1440 LS_Helligkeit_FW 1023;
BA_ "GenSigMissingSourceValue" SG_ 1440 LS_Helligkeit_FW 1023;
BA_ "GenSigSendType" SG_ 1440 LS_Helligkeit_IR 0;
BA_ "GenSigStartValue" SG_ 1440 LS_Helligkeit_IR 254;
BA_ "GenSigSwitchedByIgnition" SG_ 1440 LS_Helligkeit_IR 0;
BA_ "Fehlerwert" SG_ 1440 LS_Helligkeit_IR 255;
BA_ "GenSigMissingSourceValue" SG_ 1440 LS_Helligkeit_IR 255;
BA_ "GenSigSendType" SG_ 1440 LS_Verbau 0;
BA_ "GenSigSwitchedByIgnition" SG_ 1440 LS_Verbau 0;
BA_ "GenSigSendType" SG_ 1440 RLS_Vorfeldhelligkeit_Boost 0;
BA_ "GenSigStartValue" SG_ 1440 RLS_Vorfeldhelligkeit_Boost 15;
BA_ "GenSigSwitchedByIgnition" SG_ 1440 RLS_Vorfeldhelligkeit_Boost 0;
BA_ "GenSigSendType" SG_ 1440 RS_defekt 0;
BA_ "GenSigSwitchedByIgnition" SG_ 1440 RS_defekt 0;
BA_ "GenSigSendType" SG_ 1440 RS_Regenmenge 0;
BA_ "GenSigStartValue" SG_ 1440 RS_Regenmenge 14;
BA_ "GenSigSwitchedByIgnition" SG_ 1440 RS_Regenmenge 0;
BA_ "Fehlerwert" SG_ 1440 RS_Regenmenge 15;
BA_ "GenSigMissingSourceValue" SG_ 1440 RS_Regenmenge 15;
BA_ "GenSigSendType" SG_ 1440 RS_Schwall 0;
BA_ "GenSigSwitchedByIgnition" SG_ 1440 RS_Schwall 0;
BA_ "GenSigSendType" SG_ 1440 RS_Verbau 0;
BA_ "GenSigSwitchedByIgnition" SG_ 1440 RS_Verbau 0;
BA_ "GenSigSendType" SG_ 1440 RS_Verglasung_schliessen 0;
BA_ "GenSigSwitchedByIgnition" SG_ 1440 RS_Verglasung_schliessen 0;
BA_ "GenSigSendType" SG_ 1440 RS_Wischergeschwindigkeit 0;
BA_ "GenSigSwitchedByIgnition" SG_ 1440 RS_Wischergeschwindigkeit 0;
BA_ "GenSigSendType" SG_ 1440 SLS_Helligkeit_IR 0;
BA_ "GenSigStartValue" SG_ 1440 SLS_Helligkeit_IR 254;
BA_ "GenSigSwitchedByIgnition" SG_ 1440 SLS_Helligkeit_IR 0;
BA_ "Fehlerwert" SG_ 1440 SLS_Helligkeit_IR 255;
BA_ "GenSigSendType" SG_ 1504 MD1_Lage 0;
BA_ "GenSigSwitchedByIgnition" SG_ 1504 MD1_Lage 0;
BA_ "GenSigSendType" SG_ 1504 MD1_Position 0;
BA_ "GenSigStartValue" SG_ 1504 MD1_Position 126;
BA_ "GenSigSwitchedByIgnition" SG_ 1504 MD1_Position 0;
BA_ "GenSigSendType" SG_ 1504 MD3_Lage 0;
BA_ "GenSigSwitchedByIgnition" SG_ 1504 MD3_Lage 0;
BA_ "GenSigSendType" SG_ 1504 MD3_Position 0;
BA_ "GenSigSwitchedByIgnition" SG_ 1504 MD3_Position 0;
BA_ "GenSigSendType" SG_ 1504 MRollo_Lage 0;
BA_ "GenSigSwitchedByIgnition" SG_ 1504 MRollo_Lage 0;
BA_ "GenSigSendType" SG_ 1504 MRollo_Position 0;
BA_ "GenSigStartValue" SG_ 1504 MRollo_Position 126;
BA_ "GenSigSwitchedByIgnition" SG_ 1504 MRollo_Position 0;
BA_ "GenSigSendType" SG_ 1504 Rollo_normiert 3;
BA_ "GenSigSwitchedByIgnition" SG_ 1504 Rollo_normiert 0;
BA_ "GenSigSendType" SG_ 1504 Rollo_Thermoschutz 3;
BA_ "GenSigSwitchedByIgnition" SG_ 1504 Rollo_Thermoschutz 0;
BA_ "GenSigSendType" SG_ 1504 Rollo_UEKB_aktiv 3;
BA_ "GenSigSwitchedByIgnition" SG_ 1504 Rollo_UEKB_aktiv 0;
BA_ "GenSigSendType" SG_ 1504 SAD_Anf_ESC_Zuschaltung 3;
BA_ "GenSigSwitchedByIgnition" SG_ 1504 SAD_Anf_ESC_Zuschaltung 0;
BA_ "GenSigSendType" SG_ 1504 SAD_normiert 3;
BA_ "GenSigSwitchedByIgnition" SG_ 1504 SAD_normiert 0;
BA_ "GenSigSendType" SG_ 1504 SAD_Taster_Deckel_hi 4;
BA_ "GenSigSwitchedByIgnition" SG_ 1504 SAD_Taster_Deckel_hi 0;
BA_ "GenSigSendType" SG_ 1504 SAD_Taster_Deckel_vo 4;
BA_ "GenSigSwitchedByIgnition" SG_ 1504 SAD_Taster_Deckel_vo 0;
BA_ "GenSigSendType" SG_ 1504 SAD_Taster_Rollo_hi 4;
BA_ "GenSigSwitchedByIgnition" SG_ 1504 SAD_Taster_Rollo_hi 0;
BA_ "GenSigSendType" SG_ 1504 SAD_Taster_Rollo_vo 4;
BA_ "GenSigSwitchedByIgnition" SG_ 1504 SAD_Taster_Rollo_vo 0;
BA_ "GenSigSendType" SG_ 1504 SAD_Thermoschutz 3;
BA_ "GenSigSwitchedByIgnition" SG_ 1504 SAD_Thermoschutz 0;
BA_ "GenSigSendType" SG_ 1504 SAD_UEKB_aktiv 3;
BA_ "GenSigSwitchedByIgnition" SG_ 1504 SAD_UEKB_aktiv 0;
BA_ "GenSigSendType" SG_ 2463978605 SCode_Data 5;
BA_ "GenSigSwitchedByIgnition" SG_ 2463978605 SCode_Data 0;
BA_ "GenSigSendType" SG_ 2463978605 SCode_Target 5;
BA_ "GenSigSwitchedByIgnition" SG_ 2463978605 SCode_Target 0;
BA_ "GenSigSendType" SG_ 873 SDF2_Pos_AnzHauptspuren 0;
BA_ "GenSigStartValue" SG_ 873 SDF2_Pos_AnzHauptspuren 15;
BA_ "GenSigSendType" SG_ 873 SDF2_Pos_AnzRampenLinks 0;
BA_ "GenSigStartValue" SG_ 873 SDF2_Pos_AnzRampenLinks 7;
BA_ "GenSigSendType" SG_ 873 SDF2_Pos_AnzRampenRechts 0;
BA_ "GenSigStartValue" SG_ 873 SDF2_Pos_AnzRampenRechts 7;
BA_ "GenSigSendType" SG_ 873 SDF2_Pos_Distanz_Rampe_links 0;
BA_ "GenSigStartValue" SG_ 873 SDF2_Pos_Distanz_Rampe_links 63;
BA_ "GenSigSendType" SG_ 873 SDF2_Pos_Distanz_Rampe_rechts 0;
BA_ "GenSigStartValue" SG_ 873 SDF2_Pos_Distanz_Rampe_rechts 63;
BA_ "GenSigSendType" SG_ 873 SDF2_Pos_Fehler_Laengsrichtung 0;
BA_ "GenSigSendType" SG_ 873 SDF2_Pos_GueteZuordnung 0;
BA_ "GenSigStartValue" SG_ 873 SDF2_Pos_GueteZuordnung 15;
BA_ "GenSigSendType" SG_ 873 SDF2_Pos_Inhibitzeit 0;
BA_ "GenSigSendType" SG_ 873 SDF2_Pos_Offset 0;
BA_ "GenSigSendType" SG_ 873 SDF2_Pos_Segment_ID 0;
BA_ "GenSigSendType" SG_ 873 SDF2_Pos_Spurnummer 0;
BA_ "GenSigStartValue" SG_ 873 SDF2_Pos_Spurnummer 15;
BA_ "GenSigSendType" SG_ 873 SDF2_Pos_Spurtype 0;
BA_ "GenSigStartValue" SG_ 873 SDF2_Pos_Spurtype 31;
BA_ "GenSigSendType" SG_ 873 SDF2_Pos_Standort_Eindeutig 0;
BA_ "GenSigSwitchedByIgnition" SG_ 1167 SK1_Key_Data_1 0;
BA_ "GenSigSwitchedByIgnition" SG_ 1167 SK1_Key_Data_10 0;
BA_ "GenSigSwitchedByIgnition" SG_ 1167 SK1_Key_Data_2 0;
BA_ "GenSigSwitchedByIgnition" SG_ 1167 SK1_Key_Data_3 0;
BA_ "GenSigSwitchedByIgnition" SG_ 1167 SK1_Key_Data_4 0;
BA_ "GenSigSwitchedByIgnition" SG_ 1167 SK1_Key_Data_5 0;
BA_ "GenSigSwitchedByIgnition" SG_ 1167 SK1_Key_Data_6 0;
BA_ "GenSigSwitchedByIgnition" SG_ 1167 SK1_Key_Data_7 0;
BA_ "GenSigSwitchedByIgnition" SG_ 1167 SK1_Key_Data_8 0;
BA_ "GenSigSwitchedByIgnition" SG_ 1167 SK1_Key_Data_9 0;
BA_ "GenSigSendType" SG_ 1167 SK1_MUX 3;
BA_ "GenSigSwitchedByIgnition" SG_ 1167 SK1_MUX 0;
BA_ "GenSigSendType" SG_ 1363 SitzMemo_SR3_01_BZ 0;
BA_ "GenSigFuncType" SG_ 1363 SitzMemo_SR3_01_BZ 1;
BA_ "GenSigSwitchedByIgnition" SG_ 1363 SitzMemo_SR3_01_BZ 0;
BA_ "GenSigSendType" SG_ 1363 SitzMemo_SR3_01_CRC 0;
BA_ "GenSigFuncType" SG_ 1363 SitzMemo_SR3_01_CRC 2;
BA_ "GenSigSwitchedByIgnition" SG_ 1363 SitzMemo_SR3_01_CRC 0;
BA_ "GenSigSendType" SG_ 1363 SR3_Entriegl_Motor_li 0;
BA_ "GenSigSwitchedByIgnition" SG_ 1363 SR3_Entriegl_Motor_li 0;
BA_ "Fehlerwert" SG_ 1363 SR3_Entriegl_Motor_li 7;
BA_ "GenSigSendType" SG_ 1363 SR3_Entriegl_Motor_re 0;
BA_ "GenSigSwitchedByIgnition" SG_ 1363 SR3_Entriegl_Motor_re 0;
BA_ "Fehlerwert" SG_ 1363 SR3_Entriegl_Motor_re 7;
BA_ "GenSigSendType" SG_ 1363 SR3_Fahrpos_HBFS_erzeugen 0;
BA_ "GenSigSwitchedByIgnition" SG_ 1363 SR3_Fahrpos_HBFS_erzeugen 0;
BA_ "GenSigSendType" SG_ 1363 SR3_Fahrpos_HFS_erzeugen 0;
BA_ "GenSigSwitchedByIgnition" SG_ 1363 SR3_Fahrpos_HFS_erzeugen 0;
BA_ "GenSigSendType" SG_ 1363 SR3_Fahrpos_HFS_HBFS_erzeugen 0;
BA_ "GenSigSwitchedByIgnition" SG_ 1363 SR3_Fahrpos_HFS_HBFS_erzeugen 0;
BA_ "GenSigSendType" SG_ 1363 SR3_Fahrposition_links 0;
BA_ "GenSigSwitchedByIgnition" SG_ 1363 SR3_Fahrposition_links 0;
BA_ "Fehlerwert" SG_ 1363 SR3_Fahrposition_links 3;
BA_ "GenSigSendType" SG_ 1363 SR3_Fahrposition_rechts 0;
BA_ "GenSigSwitchedByIgnition" SG_ 1363 SR3_Fahrposition_rechts 0;
BA_ "Fehlerwert" SG_ 1363 SR3_Fahrposition_rechts 3;
BA_ "GenSigSendType" SG_ 1363 SR3_Ladeboden_HBFS_erzeugen 0;
BA_ "GenSigSwitchedByIgnition" SG_ 1363 SR3_Ladeboden_HBFS_erzeugen 0;
BA_ "GenSigSendType" SG_ 1363 SR3_Ladeboden_HBFS_HFS_erzeugen 0;
BA_ "GenSigSwitchedByIgnition" SG_ 1363 SR3_Ladeboden_HBFS_HFS_erzeugen 0;
BA_ "GenSigSendType" SG_ 1363 SR3_Ladeboden_HFS_erzeugen 0;
BA_ "GenSigSwitchedByIgnition" SG_ 1363 SR3_Ladeboden_HFS_erzeugen 0;
BA_ "GenSigSendType" SG_ 1363 SR3_Status_Lehne_Links 0;
BA_ "GenSigSwitchedByIgnition" SG_ 1363 SR3_Status_Lehne_Links 0;
BA_ "GenSigSendType" SG_ 1363 SR3_Status_Lehne_Rechts 0;
BA_ "GenSigSwitchedByIgnition" SG_ 1363 SR3_Status_Lehne_Rechts 0;
BA_ "GenSigSendType" SG_ 1363 SR3_Verriegelungssensor_li 0;
BA_ "GenSigSwitchedByIgnition" SG_ 1363 SR3_Verriegelungssensor_li 0;
BA_ "Fehlerwert" SG_ 1363 SR3_Verriegelungssensor_li 5;
BA_ "GenSigSendType" SG_ 1363 SR3_Verriegelungssensor_re 0;
BA_ "GenSigSwitchedByIgnition" SG_ 1363 SR3_Verriegelungssensor_re 0;
BA_ "Fehlerwert" SG_ 1363 SR3_Verriegelungssensor_re 5;
BA_ "GenSigSendType" SG_ 980 BH_Blinker_Fehler 4;
BA_ "GenSigSwitchedByIgnition" SG_ 980 BH_Blinker_Fehler 0;
BA_ "Fehlerwert" SG_ 980 BH_Blinker_Fehler 1;
BA_ "GenSigSendType" SG_ 980 BH_Blinker_li 4;
BA_ "GenSigSwitchedByIgnition" SG_ 980 BH_Blinker_li 0;
BA_ "GenSigSendType" SG_ 980 BH_Blinker_re 4;
BA_ "GenSigSwitchedByIgnition" SG_ 980 BH_Blinker_re 0;
BA_ "GenSigSendType" SG_ 980 BH_Fernlicht 3;
BA_ "GenSigSwitchedByIgnition" SG_ 980 BH_Fernlicht 0;
BA_ "GenSigSendType" SG_ 980 BH_Lichthupe 4;
BA_ "GenSigSwitchedByIgnition" SG_ 980 BH_Lichthupe 0;
BA_ "GenSigSendType" SG_ 980 FAS_Taster 3;
BA_ "GenSigSwitchedByIgnition" SG_ 980 FAS_Taster 0;
BA_ "GenSigSendType" SG_ 980 FAS_Taster_Fehler 3;
BA_ "GenSigSwitchedByIgnition" SG_ 980 FAS_Taster_Fehler 0;
BA_ "Fehlerwert" SG_ 980 FAS_Taster_Fehler 1;
BA_ "GenSigSendType" SG_ 980 LRH_aktiv 3;
BA_ "GenSigSwitchedByIgnition" SG_ 980 LRH_aktiv 0;
BA_ "GenSigSendType" SG_ 980 LRH_On_Off 3;
BA_ "GenSigSwitchedByIgnition" SG_ 980 LRH_On_Off 0;
BA_ "Fehlerwert" SG_ 980 LRH_On_Off 3;
BA_ "GenSigSendType" SG_ 980 LSS_Tastencode 3;
BA_ "GenSigSwitchedByIgnition" SG_ 980 LSS_Tastencode 0;
BA_ "GenSigSendType" SG_ 980 SMLS_01_BZ 0;
BA_ "GenSigFuncType" SG_ 980 SMLS_01_BZ 1;
BA_ "GenSigSwitchedByIgnition" SG_ 980 SMLS_01_BZ 0;
BA_ "GenSigSendType" SG_ 980 SMLS_01_CRC 0;
BA_ "GenSigFuncType" SG_ 980 SMLS_01_CRC 2;
BA_ "GenSigSwitchedByIgnition" SG_ 980 SMLS_01_CRC 0;
BA_ "GenSigSendType" SG_ 980 SMLS_Hupe 4;
BA_ "GenSigSwitchedByIgnition" SG_ 980 SMLS_Hupe 0;
BA_ "GenSigSendType" SG_ 980 SMLS_P_verriegelt 4;
BA_ "GenSigSwitchedByIgnition" SG_ 980 SMLS_P_verriegelt 0;
BA_ "Fehlerwert" SG_ 980 SMLS_P_verriegelt 3;
BA_ "GenSigSendType" SG_ 980 SMLS_P_verriegelt_plausibel 3;
BA_ "GenSigSwitchedByIgnition" SG_ 980 SMLS_P_verriegelt_plausibel 0;
BA_ "GenSigSendType" SG_ 980 SMLS_PTT 4;
BA_ "GenSigSendType" SG_ 980 WH_Frontwaschen 3;
BA_ "GenSigSwitchedByIgnition" SG_ 980 WH_Frontwaschen 0;
BA_ "GenSigSendType" SG_ 980 WH_Heckintervall 3;
BA_ "GenSigSwitchedByIgnition" SG_ 980 WH_Heckintervall 0;
BA_ "GenSigSendType" SG_ 980 WH_Heckwaschen 3;
BA_ "GenSigSwitchedByIgnition" SG_ 980 WH_Heckwaschen 0;
BA_ "GenSigSendType" SG_ 980 WH_Intervall 3;
BA_ "GenSigSwitchedByIgnition" SG_ 980 WH_Intervall 0;
BA_ "GenSigSendType" SG_ 980 WH_Intervallstufen 3;
BA_ "GenSigSwitchedByIgnition" SG_ 980 WH_Intervallstufen 0;
BA_ "Fehlerwert" SG_ 980 WH_Intervallstufen 15;
BA_ "GenSigMissingSourceValue" SG_ 980 WH_Intervallstufen 15;
BA_ "GenSigSendType" SG_ 980 WH_SRA 3;
BA_ "GenSigSwitchedByIgnition" SG_ 980 WH_SRA 0;
BA_ "GenSigSendType" SG_ 980 WH_Tipwischen 4;
BA_ "GenSigSwitchedByIgnition" SG_ 980 WH_Tipwischen 0;
BA_ "GenSigSendType" SG_ 980 WH_Tipwischen_lang 4;
BA_ "GenSigSwitchedByIgnition" SG_ 980 WH_Tipwischen_lang 0;
BA_ "GenSigSendType" SG_ 980 WH_Wischer_Fehler 3;
BA_ "GenSigSwitchedByIgnition" SG_ 980 WH_Wischer_Fehler 0;
BA_ "Fehlerwert" SG_ 980 WH_Wischer_Fehler 1;
BA_ "GenSigSendType" SG_ 980 WH_WischerStufe1 3;
BA_ "GenSigSwitchedByIgnition" SG_ 980 WH_WischerStufe1 0;
BA_ "GenSigSendType" SG_ 980 WH_WischerStufe2 3;
BA_ "GenSigSwitchedByIgnition" SG_ 980 WH_WischerStufe2 0;
BA_ "GenSigSendType" SG_ 2464161907 SOK_FoD_Info_El_Req_Challenge 3;
BA_ "GenSigSwitchedByIgnition" SG_ 2464161907 SOK_FoD_Info_El_Req_Challenge 0;
BA_ "GenSigSendType" SG_ 2464301171 SOK_FoD_Info_El_Resp_Challenge 3;
BA_ "GenSigSwitchedByIgnition" SG_ 2464301171 SOK_FoD_Info_El_Resp_Challenge 0;
BA_ "GenSigSendType" SG_ 2589283756 SOK_ungeschuetzte_Zeit 3;
BA_ "GenSigSwitchedByIgnition" SG_ 2589283756 SOK_ungeschuetzte_Zeit 0;
BA_ "GenSigSendType" SG_ 2464153703 SOK_Zeit_OCU_Challenge 3;
BA_ "GenSigSwitchedByIgnition" SG_ 2464153703 SOK_Zeit_OCU_Challenge 0;
BA_ "GenSigSendType" SG_ 2464284775 SOK_Zeit_OCU_Signatur 3;
BA_ "GenSigFuncType" SG_ 2464284775 SOK_Zeit_OCU_Signatur 15;
BA_ "GenSigSwitchedByIgnition" SG_ 2464284775 SOK_Zeit_OCU_Signatur 0;
BA_ "GenSigSendType" SG_ 2464288871 SOK_Zeit_OCU_Zeit 3;
BA_ "GenSigSwitchedByIgnition" SG_ 2464288871 SOK_Zeit_OCU_Zeit 0;
BA_ "GenSigSendType" SG_ 2464153715 SOK_Zeit_Info_El_Challenge 3;
BA_ "GenSigSwitchedByIgnition" SG_ 2464153715 SOK_Zeit_Info_El_Challenge 0;
BA_ "GenSigSendType" SG_ 2464288883 SOK_Zeit_Info_El_Signatur 3;
BA_ "GenSigFuncType" SG_ 2464288883 SOK_Zeit_Info_El_Signatur 15;
BA_ "GenSigSwitchedByIgnition" SG_ 2464288883 SOK_Zeit_Info_El_Signatur 0;
BA_ "GenSigSendType" SG_ 2464292979 SOK_Zeit_Info_El_Zeit 3;
BA_ "GenSigSwitchedByIgnition" SG_ 2464292979 SOK_Zeit_Info_El_Zeit 0;
BA_ "GenSigSendType" SG_ 1467 SoSe_SunInt_2D_Li 0;
BA_ "GenSigStartValue" SG_ 1467 SoSe_SunInt_2D_Li 254;
BA_ "GenSigSwitchedByIgnition" SG_ 1467 SoSe_SunInt_2D_Li 0;
BA_ "Fehlerwert" SG_ 1467 SoSe_SunInt_2D_Li 255;
BA_ "GenSigSendType" SG_ 1467 SoSe_SunInt_2D_Re 0;
BA_ "GenSigStartValue" SG_ 1467 SoSe_SunInt_2D_Re 254;
BA_ "GenSigSwitchedByIgnition" SG_ 1467 SoSe_SunInt_2D_Re 0;
BA_ "Fehlerwert" SG_ 1467 SoSe_SunInt_2D_Re 255;
BA_ "GenSigSendType" SG_ 1313 STH_EKP_Anst 0;
BA_ "GenSigSwitchedByIgnition" SG_ 1313 STH_EKP_Anst 0;
BA_ "GenSigSendType" SG_ 1313 STH_Fehler_ElWaPu 0;
BA_ "GenSigSwitchedByIgnition" SG_ 1313 STH_Fehler_ElWaPu 0;
BA_ "Fehlerwert" SG_ 1313 STH_Fehler_ElWaPu 1;
BA_ "GenSigSendType" SG_ 1313 STH_Fehlerstatus 0;
BA_ "GenSigSwitchedByIgnition" SG_ 1313 STH_Fehlerstatus 0;
BA_ "GenSigSendType" SG_ 1313 STH_Funk_aus 0;
BA_ "GenSigSwitchedByIgnition" SG_ 1313 STH_Funk_aus 0;
BA_ "GenSigSendType" SG_ 1313 STH_Funk_ein 0;
BA_ "GenSigSwitchedByIgnition" SG_ 1313 STH_Funk_ein 0;
BA_ "GenSigSendType" SG_ 1313 STH_Geblaese 0;
BA_ "GenSigSwitchedByIgnition" SG_ 1313 STH_Geblaese 0;
BA_ "GenSigSendType" SG_ 1313 STH_Heizleistung 0;
BA_ "GenSigSwitchedByIgnition" SG_ 1313 STH_Heizleistung 0;
BA_ "GenSigSendType" SG_ 1313 STH_KL_HUP 0;
BA_ "GenSigSwitchedByIgnition" SG_ 1313 STH_KL_HUP 0;
BA_ "GenSigSendType" SG_ 1313 STH_KVS 0;
BA_ "GenSigSwitchedByIgnition" SG_ 1313 STH_KVS 0;
BA_ "GenSigSendType" SG_ 1313 STH_KVS_Ueberlauf 0;
BA_ "GenSigSwitchedByIgnition" SG_ 1313 STH_KVS_Ueberlauf 0;
BA_ "GenSigSendType" SG_ 1313 STH_LED 0;
BA_ "GenSigSwitchedByIgnition" SG_ 1313 STH_LED 0;
BA_ "GenSigSendType" SG_ 1313 STH_Motorvorwaermung 0;
BA_ "GenSigSwitchedByIgnition" SG_ 1313 STH_Motorvorwaermung 0;
BA_ "GenSigSendType" SG_ 1313 STH_Pumpe_ein 0;
BA_ "GenSigSwitchedByIgnition" SG_ 1313 STH_Pumpe_ein 0;
BA_ "GenSigSendType" SG_ 1313 STH_Pumpen_Anf_extern 0;
BA_ "GenSigSwitchedByIgnition" SG_ 1313 STH_Pumpen_Anf_extern 0;
BA_ "GenSigSendType" SG_ 1313 STH_Servicemode 0;
BA_ "GenSigSwitchedByIgnition" SG_ 1313 STH_Servicemode 0;
BA_ "GenSigSendType" SG_ 1313 STH_SH_ZH 0;
BA_ "GenSigSwitchedByIgnition" SG_ 1313 STH_SH_ZH 0;
BA_ "GenSigSendType" SG_ 1313 STH_Start_folgt 0;
BA_ "GenSigSwitchedByIgnition" SG_ 1313 STH_Start_folgt 0;
BA_ "GenSigSendType" SG_ 1313 STH_Texte 0;
BA_ "GenSigSwitchedByIgnition" SG_ 1313 STH_Texte 0;
BA_ "GenSigSendType" SG_ 1313 STH_Ventil_Status 0;
BA_ "GenSigSwitchedByIgnition" SG_ 1313 STH_Ventil_Status 0;
BA_ "GenSigSendType" SG_ 1313 STH_Ventiloeffnungszeit 0;
BA_ "GenSigSwitchedByIgnition" SG_ 1313 STH_Ventiloeffnungszeit 0;
BA_ "GenSigSendType" SG_ 1313 STH_Waermeeintrag 0;
BA_ "GenSigSwitchedByIgnition" SG_ 1313 STH_Waermeeintrag 0;
BA_ "GenSigSendType" SG_ 1313 STH_war_aktiv 0;
BA_ "GenSigSwitchedByIgnition" SG_ 1313 STH_war_aktiv 0;
BA_ "GenSigSendType" SG_ 1313 STH_Wassertemp 0;
BA_ "GenSigStartValue" SG_ 1313 STH_Wassertemp 254;
BA_ "GenSigSwitchedByIgnition" SG_ 1313 STH_Wassertemp 0;
BA_ "Fehlerwert" SG_ 1313 STH_Wassertemp 255;
BA_ "GenSigSendType" SG_ 1313 STH_Zusatzheizung 0;
BA_ "GenSigSwitchedByIgnition" SG_ 1313 STH_Zusatzheizung 0;
BA_ "GenSigSendType" SG_ 673 ASW_Kombiausgabe 3;
BA_ "GenSigSendType" SG_ 673 ASW_Ton_Richtung_HL 3;
BA_ "GenSigSwitchedByIgnition" SG_ 673 ASW_Ton_Richtung_HL 0;
BA_ "GenSigSendType" SG_ 673 ASW_Ton_Richtung_HR 3;
BA_ "GenSigSwitchedByIgnition" SG_ 673 ASW_Ton_Richtung_HR 0;
BA_ "GenSigSendType" SG_ 673 ASW_Ton_Richtung_VL 3;
BA_ "GenSigSwitchedByIgnition" SG_ 673 ASW_Ton_Richtung_VL 0;
BA_ "GenSigSendType" SG_ 673 ASW_Ton_Richtung_VR 3;
BA_ "GenSigSwitchedByIgnition" SG_ 673 ASW_Ton_Richtung_VR 0;
BA_ "GenSigSendType" SG_ 673 SWA_Brightness_Mode_FPM 3;
BA_ "GenSigSwitchedByIgnition" SG_ 673 SWA_Brightness_Mode_FPM 0;
BA_ "Fehlerwert" SG_ 673 SWA_Brightness_Mode_FPM 15;
BA_ "GenSigSendType" SG_ 673 SWA_Infostufe_Assist_li 3;
BA_ "GenSigSendType" SG_ 673 SWA_Infostufe_Assist_re 3;
BA_ "GenSigSendType" SG_ 673 SWA_Kombiausgabe 3;
BA_ "GenSigSendType" SG_ 673 SWA_Kombiwarnung 3;
BA_ "GenSigSwitchedByIgnition" SG_ 673 SWA_Kombiwarnung 0;
BA_ "GenSigSendType" SG_ 673 SWA_LED_Ausgabemodus_BFS 3;
BA_ "GenSigSendType" SG_ 673 SWA_LED_Ausgabemodus_FS 3;
BA_ "GenSigSendType" SG_ 673 SWA_LED_Hell_BFS 3;
BA_ "GenSigStartValue" SG_ 673 SWA_LED_Hell_BFS 126;
BA_ "Fehlerwert" SG_ 673 SWA_LED_Hell_BFS 127;
BA_ "GenSigSendType" SG_ 673 SWA_LED_Hell_FS 3;
BA_ "GenSigStartValue" SG_ 673 SWA_LED_Hell_FS 126;
BA_ "Fehlerwert" SG_ 673 SWA_LED_Hell_FS 127;
BA_ "GenSigSendType" SG_ 673 SWA_Modus_System 3;
BA_ "GenSigSendType" SG_ 673 SWA_Status 3;
BA_ "Fehlerwert" SG_ 673 SWA_Status 3;
BA_ "GenSigSendType" SG_ 673 SWA_Status_KuFu 3;
BA_ "Fehlerwert" SG_ 673 SWA_Status_KuFu 3;
BA_ "GenSigSendType" SG_ 673 SWA_Status_System 3;
BA_ "Fehlerwert" SG_ 673 SWA_Status_System 3;
BA_ "GenSigSendType" SG_ 673 SWA_Warnstufe_Assist_li 3;
BA_ "GenSigSendType" SG_ 673 SWA_Warnstufe_Assist_re 3;
BA_ "GenSigSendType" SG_ 1413 GW_KD_Fehler 3;
BA_ "GenSigSendType" SG_ 1413 SI_BUS_01 3;
BA_ "GenSigStartValue" SG_ 1413 SI_BUS_01 1;
BA_ "GenSigSwitchedByIgnition" SG_ 1413 SI_BUS_01 0;
BA_ "GenSigSendType" SG_ 1413 SI_BUS_02 3;
BA_ "GenSigStartValue" SG_ 1413 SI_BUS_02 1;
BA_ "GenSigSwitchedByIgnition" SG_ 1413 SI_BUS_02 0;
BA_ "GenSigSendType" SG_ 1413 SI_BUS_03 3;
BA_ "GenSigStartValue" SG_ 1413 SI_BUS_03 1;
BA_ "GenSigSwitchedByIgnition" SG_ 1413 SI_BUS_03 0;
BA_ "GenSigSendType" SG_ 1413 SI_BUS_04 3;
BA_ "GenSigStartValue" SG_ 1413 SI_BUS_04 1;
BA_ "GenSigSwitchedByIgnition" SG_ 1413 SI_BUS_04 0;
BA_ "GenSigSendType" SG_ 1413 SI_BUS_05 3;
BA_ "GenSigStartValue" SG_ 1413 SI_BUS_05 1;
BA_ "GenSigSwitchedByIgnition" SG_ 1413 SI_BUS_05 0;
BA_ "GenSigSendType" SG_ 1413 SI_BUS_06 3;
BA_ "GenSigStartValue" SG_ 1413 SI_BUS_06 1;
BA_ "GenSigSwitchedByIgnition" SG_ 1413 SI_BUS_06 0;
BA_ "GenSigSendType" SG_ 1413 SI_BUS_07 3;
BA_ "GenSigStartValue" SG_ 1413 SI_BUS_07 1;
BA_ "GenSigSwitchedByIgnition" SG_ 1413 SI_BUS_07 0;
BA_ "GenSigSendType" SG_ 1413 SI_BUS_08 3;
BA_ "GenSigStartValue" SG_ 1413 SI_BUS_08 1;
BA_ "GenSigSwitchedByIgnition" SG_ 1413 SI_BUS_08 0;
BA_ "GenSigSendType" SG_ 1413 SI_BUS_09 3;
BA_ "GenSigStartValue" SG_ 1413 SI_BUS_09 1;
BA_ "GenSigSwitchedByIgnition" SG_ 1413 SI_BUS_09 0;
BA_ "GenSigSendType" SG_ 1413 SI_BUS_10 3;
BA_ "GenSigStartValue" SG_ 1413 SI_BUS_10 1;
BA_ "GenSigSwitchedByIgnition" SG_ 1413 SI_BUS_10 0;
BA_ "GenSigSendType" SG_ 1413 SI_BUS_11 3;
BA_ "GenSigStartValue" SG_ 1413 SI_BUS_11 1;
BA_ "GenSigSwitchedByIgnition" SG_ 1413 SI_BUS_11 0;
BA_ "GenSigSendType" SG_ 1413 SI_BUS_12 3;
BA_ "GenSigStartValue" SG_ 1413 SI_BUS_12 1;
BA_ "GenSigSwitchedByIgnition" SG_ 1413 SI_BUS_12 0;
BA_ "GenSigSendType" SG_ 1413 SI_BUS_13 3;
BA_ "GenSigStartValue" SG_ 1413 SI_BUS_13 1;
BA_ "GenSigSwitchedByIgnition" SG_ 1413 SI_BUS_13 0;
BA_ "GenSigSendType" SG_ 1413 SI_BUS_14 3;
BA_ "GenSigStartValue" SG_ 1413 SI_BUS_14 1;
BA_ "GenSigSwitchedByIgnition" SG_ 1413 SI_BUS_14 0;
BA_ "GenSigSendType" SG_ 1413 SI_BUS_15 3;
BA_ "GenSigStartValue" SG_ 1413 SI_BUS_15 1;
BA_ "GenSigSwitchedByIgnition" SG_ 1413 SI_BUS_15 0;
BA_ "GenSigSendType" SG_ 1413 SI_Bus_Identifikation 0;
BA_ "GenSigSwitchedByIgnition" SG_ 1413 SI_Bus_Identifikation 0;
BA_ "GenSigSendType" SG_ 1413 SI_CAB_V14 3;
BA_ "GenSigSwitchedByIgnition" SG_ 1413 SI_CAB_V14 0;
BA_ "GenSigSendType" SG_ 1413 SI_Diagnose_Aktiv 3;
BA_ "GenSigSwitchedByIgnition" SG_ 1413 SI_Diagnose_Aktiv 0;
BA_ "GenSigSendType" SG_ 1413 SI_NWDF 3;
BA_ "GenSigSwitchedByIgnition" SG_ 1413 SI_NWDF 0;
BA_ "GenSigSendType" SG_ 1413 SI_NWDF_30 3;
BA_ "GenSigSwitchedByIgnition" SG_ 1413 SI_NWDF_30 0;
BA_ "GenSigSendType" SG_ 1413 SI_NWDF_gueltig 3;
BA_ "GenSigFuncType" SG_ 1413 SI_NWDF_gueltig 8;
BA_ "GenSigSwitchedByIgnition" SG_ 1413 SI_NWDF_gueltig 0;
BA_ "GenSigSendType" SG_ 1413 SI_P_Mode 3;
BA_ "GenSigSwitchedByIgnition" SG_ 1413 SI_P_Mode 0;
BA_ "GenSigSendType" SG_ 1413 SI_P_Mode_gueltig 3;
BA_ "GenSigSwitchedByIgnition" SG_ 1413 SI_P_Mode_gueltig 0;
BA_ "GenSigSendType" SG_ 1413 SI_QRS_Mode 3;
BA_ "GenSigSwitchedByIgnition" SG_ 1413 SI_QRS_Mode 0;
BA_ "GenSigSendType" SG_ 1413 SI_Sammel_SG_Fehler 0;
BA_ "GenSigStartValue" SG_ 1413 SI_Sammel_SG_Fehler 63;
BA_ "GenSigSwitchedByIgnition" SG_ 1413 SI_Sammel_SG_Fehler 0;
BA_ "GenSigSendType" SG_ 1413 SI_Sammelfehler 3;
BA_ "GenSigSwitchedByIgnition" SG_ 1413 SI_Sammelfehler 0;
BA_ "GenSigSendType" SG_ 1413 SI_T_Mode 3;
BA_ "GenSigSwitchedByIgnition" SG_ 1413 SI_T_Mode 0;
BA_ "GenSigSendType" SG_ 1413 SI_T_Schutz 3;
BA_ "GenSigSwitchedByIgnition" SG_ 1413 SI_T_Schutz 0;
BA_ "GenSigSendType" SG_ 1637 TF_BT_ConnectionState 3;
BA_ "GenSigSwitchedByIgnition" SG_ 1637 TF_BT_ConnectionState 0;
BA_ "GenSigSendType" SG_ 1637 TF_Mute_Msg_Code 3;
BA_ "GenSigSwitchedByIgnition" SG_ 1637 TF_Mute_Msg_Code 0;
BA_ "GenSigSendType" SG_ 1637 TF_Phone_active_call 3;
BA_ "GenSigSwitchedByIgnition" SG_ 1637 TF_Phone_active_call 0;
BA_ "GenSigSendType" SG_ 1637 TF_Phone_CountryCode 3;
BA_ "GenSigSwitchedByIgnition" SG_ 1637 TF_Phone_CountryCode 0;
BA_ "GenSigSendType" SG_ 1637 TF_Phone_err_fieldstrength 3;
BA_ "GenSigSwitchedByIgnition" SG_ 1637 TF_Phone_err_fieldstrength 0;
BA_ "GenSigSendType" SG_ 1637 TF_Phone_Error_Flag 3;
BA_ "GenSigSwitchedByIgnition" SG_ 1637 TF_Phone_Error_Flag 0;
BA_ "GenSigSendType" SG_ 1637 TF_Phone_FieldStrength 3;
BA_ "GenSigSwitchedByIgnition" SG_ 1637 TF_Phone_FieldStrength 0;
BA_ "GenSigSendType" SG_ 1637 TF_Phone_init 3;
BA_ "GenSigSwitchedByIgnition" SG_ 1637 TF_Phone_init 0;
BA_ "GenSigSendType" SG_ 1637 TF_Phone_mute 3;
BA_ "GenSigSwitchedByIgnition" SG_ 1637 TF_Phone_mute 0;
BA_ "GenSigSendType" SG_ 1637 TF_Phone_on 3;
BA_ "GenSigSwitchedByIgnition" SG_ 1637 TF_Phone_on 0;
BA_ "GenSigSendType" SG_ 1637 TF_Phone_PIN_ok 3;
BA_ "GenSigSwitchedByIgnition" SG_ 1637 TF_Phone_PIN_ok 0;
BA_ "GenSigSendType" SG_ 1637 TF_Phone_Provider 3;
BA_ "GenSigSwitchedByIgnition" SG_ 1637 TF_Phone_Provider 0;
BA_ "GenSigSendType" SG_ 1637 TF_Phone_RegistrationState 3;
BA_ "GenSigSwitchedByIgnition" SG_ 1637 TF_Phone_RegistrationState 0;
BA_ "GenSigSendType" SG_ 1637 TF_Phone_ring 3;
BA_ "GenSigSwitchedByIgnition" SG_ 1637 TF_Phone_ring 0;
BA_ "GenSigSendType" SG_ 1637 TF_Phone_SIM_ok 3;
BA_ "GenSigSwitchedByIgnition" SG_ 1637 TF_Phone_SIM_ok 0;
BA_ "GenSigSendType" SG_ 1637 TF_Phone_Status 3;
BA_ "GenSigSwitchedByIgnition" SG_ 1637 TF_Phone_Status 0;
BA_ "GenSigSendType" SG_ 1637 TF_Telephone_State 3;
BA_ "GenSigSwitchedByIgnition" SG_ 1637 TF_Telephone_State 0;
BA_ "GenSigSendType" SG_ 2589283622 TLO_01_Zaehler 3;
BA_ "GenSigSwitchedByIgnition" SG_ 2589283622 TLO_01_Zaehler 0;
BA_ "GenSigSendType" SG_ 2589283622 TLO_HMI_Status 3;
BA_ "GenSigSwitchedByIgnition" SG_ 2589283622 TLO_HMI_Status 0;
BA_ "GenSigSendType" SG_ 2589283622 TLO_LSA1_PSD_Seg_Offset 3;
BA_ "GenSigStartValue" SG_ 2589283622 TLO_LSA1_PSD_Seg_Offset 255;
BA_ "GenSigSwitchedByIgnition" SG_ 2589283622 TLO_LSA1_PSD_Seg_Offset 0;
BA_ "GenSigSendType" SG_ 2589283622 TLO_LSA1_PSD_Segment_ID 3;
BA_ "GenSigSwitchedByIgnition" SG_ 2589283622 TLO_LSA1_PSD_Segment_ID 0;
BA_ "GenSigSendType" SG_ 2589283622 TLO_LSA1_Zeit1_CF 3;
BA_ "GenSigSwitchedByIgnition" SG_ 2589283622 TLO_LSA1_Zeit1_CF 0;
BA_ "GenSigSendType" SG_ 2589283622 TLO_LSA1_Zeit1_Pred 3;
BA_ "GenSigSwitchedByIgnition" SG_ 2589283622 TLO_LSA1_Zeit1_Pred 0;
BA_ "GenSigSendType" SG_ 2589283622 TLO_LSA1_Zeit1_Status 3;
BA_ "GenSigSwitchedByIgnition" SG_ 2589283622 TLO_LSA1_Zeit1_Status 0;
BA_ "GenSigSendType" SG_ 2589283622 TLO_LSA1_Zeit2_CF 3;
BA_ "GenSigSwitchedByIgnition" SG_ 2589283622 TLO_LSA1_Zeit2_CF 0;
BA_ "GenSigSendType" SG_ 2589283622 TLO_LSA1_Zeit2_Pred 3;
BA_ "GenSigSwitchedByIgnition" SG_ 2589283622 TLO_LSA1_Zeit2_Pred 0;
BA_ "GenSigSendType" SG_ 2589283622 TLO_LSA1_Zeit2_Status 3;
BA_ "GenSigSwitchedByIgnition" SG_ 2589283622 TLO_LSA1_Zeit2_Status 0;
BA_ "GenSigSendType" SG_ 2589283622 TLO_StartStoppInfo 3;
BA_ "GenSigSwitchedByIgnition" SG_ 2589283622 TLO_StartStoppInfo 0;
BA_ "GenSigSendType" SG_ 2589283623 TLO_02_Zaehler 3;
BA_ "GenSigSwitchedByIgnition" SG_ 2589283623 TLO_02_Zaehler 0;
BA_ "GenSigSendType" SG_ 2589283623 TLO_LSA1_Layout 3;
BA_ "GenSigSwitchedByIgnition" SG_ 2589283623 TLO_LSA1_Layout 0;
BA_ "GenSigSendType" SG_ 2589283623 TLO_LSA2_PSD_Seg_Offset 3;
BA_ "GenSigStartValue" SG_ 2589283623 TLO_LSA2_PSD_Seg_Offset 255;
BA_ "GenSigSwitchedByIgnition" SG_ 2589283623 TLO_LSA2_PSD_Seg_Offset 0;
BA_ "GenSigSendType" SG_ 2589283623 TLO_LSA2_PSD_Segment_ID 3;
BA_ "GenSigSwitchedByIgnition" SG_ 2589283623 TLO_LSA2_PSD_Segment_ID 0;
BA_ "GenSigSendType" SG_ 2589283623 TLO_LSA2_Zeit1_CF 3;
BA_ "GenSigSwitchedByIgnition" SG_ 2589283623 TLO_LSA2_Zeit1_CF 0;
BA_ "GenSigSendType" SG_ 2589283623 TLO_LSA2_Zeit1_Pred 3;
BA_ "GenSigSwitchedByIgnition" SG_ 2589283623 TLO_LSA2_Zeit1_Pred 0;
BA_ "GenSigSendType" SG_ 2589283623 TLO_LSA2_Zeit1_Status 3;
BA_ "GenSigSwitchedByIgnition" SG_ 2589283623 TLO_LSA2_Zeit1_Status 0;
BA_ "GenSigSendType" SG_ 2589283623 TLO_LSA2_Zeit2_CF 3;
BA_ "GenSigSwitchedByIgnition" SG_ 2589283623 TLO_LSA2_Zeit2_CF 0;
BA_ "GenSigSendType" SG_ 2589283623 TLO_LSA2_Zeit2_Pred 3;
BA_ "GenSigSwitchedByIgnition" SG_ 2589283623 TLO_LSA2_Zeit2_Pred 0;
BA_ "GenSigSendType" SG_ 2589283623 TLO_LSA2_Zeit2_Status 3;
BA_ "GenSigSwitchedByIgnition" SG_ 2589283623 TLO_LSA2_Zeit2_Status 0;
BA_ "GenSigSendType" SG_ 1447 bCall_active 3;
BA_ "GenSigSwitchedByIgnition" SG_ 1447 bCall_active 0;
BA_ "GenSigSendType" SG_ 1447 eCall_Funktionsstatus 0;
BA_ "GenSigSwitchedByIgnition" SG_ 1447 eCall_Funktionsstatus 0;
BA_ "GenSigSendType" SG_ 1447 eCall_Funktionsstatus_02 0;
BA_ "GenSigStartValue" SG_ 1447 eCall_Funktionsstatus_02 7;
BA_ "GenSigSwitchedByIgnition" SG_ 1447 eCall_Funktionsstatus_02 0;
BA_ "GenSigSendType" SG_ 1447 eCall_MCC 0;
BA_ "GenSigSwitchedByIgnition" SG_ 1447 eCall_MCC 0;
BA_ "GenSigSendType" SG_ 1447 eCall_Mute_Anf 3;
BA_ "GenSigSwitchedByIgnition" SG_ 1447 eCall_Mute_Anf 0;
BA_ "GenSigSendType" SG_ 1447 FaceRec_Enroll_Challenge_Request 3;
BA_ "GenSigSwitchedByIgnition" SG_ 1447 FaceRec_Enroll_Challenge_Request 0;
BA_ "GenSigSendType" SG_ 1447 FoD_Anz_Funktionsabschaltung 3;
BA_ "GenSigSwitchedByIgnition" SG_ 1447 FoD_Anz_Funktionsabschaltung 0;
BA_ "GenSigSendType" SG_ 1447 iCall_active 3;
BA_ "GenSigSwitchedByIgnition" SG_ 1447 iCall_active 0;
BA_ "GenSigSendType" SG_ 1447 MOD_Energie_Anf 0;
BA_ "GenSigSwitchedByIgnition" SG_ 1447 MOD_Energie_Anf 0;
BA_ "Fehlerwert" SG_ 1447 MOD_Energie_Anf 3;
BA_ "GenSigSendType" SG_ 1447 MOD_Request_ServiceKey 3;
BA_ "GenSigSwitchedByIgnition" SG_ 1447 MOD_Request_ServiceKey 0;
BA_ "GenSigSendType" SG_ 1447 ORU_KombiTimer 0;
BA_ "GenSigSwitchedByIgnition" SG_ 1447 ORU_KombiTimer 0;
BA_ "GenSigSendType" SG_ 1447 TM_Door_Lock 5;
BA_ "GenSigSwitchedByIgnition" SG_ 1447 TM_Door_Lock 0;
BA_ "GenSigSendType" SG_ 1447 TM_Door_Unlock 5;
BA_ "GenSigSwitchedByIgnition" SG_ 1447 TM_Door_Unlock 0;
BA_ "GenSigSendType" SG_ 1447 TM_Nur_Hupen 5;
BA_ "GenSigSwitchedByIgnition" SG_ 1447 TM_Nur_Hupen 0;
BA_ "GenSigSendType" SG_ 1447 TM_Panik_Alarm 5;
BA_ "GenSigSwitchedByIgnition" SG_ 1447 TM_Panik_Alarm 0;
BA_ "GenSigSendType" SG_ 1447 TM_Spiegel_Anklappen 5;
BA_ "GenSigSwitchedByIgnition" SG_ 1447 TM_Spiegel_Anklappen 0;
BA_ "GenSigSendType" SG_ 1447 TM_Warnblinken 5;
BA_ "GenSigSwitchedByIgnition" SG_ 1447 TM_Warnblinken 0;
BA_ "GenSigSendType" SG_ 1447 TM_ZV_Signatur 0;
BA_ "GenSigSwitchedByIgnition" SG_ 1447 TM_ZV_Signatur 0;
BA_ "GenSigSendType" SG_ 977 ASW_Warnung_aktiv_BFS 3;
BA_ "GenSigSwitchedByIgnition" SG_ 977 ASW_Warnung_aktiv_BFS 0;
BA_ "GenSigSendType" SG_ 977 BFS_Status_eTAG 0;
BA_ "GenSigSwitchedByIgnition" SG_ 977 BFS_Status_eTAG 0;
BA_ "Fehlerwert" SG_ 977 BFS_Status_eTAG 3;
BA_ "GenSigSendType" SG_ 977 BT_ASW_HMI_defekt 0;
BA_ "GenSigSwitchedByIgnition" SG_ 977 BT_ASW_HMI_defekt 0;
BA_ "GenSigSendType" SG_ 977 BT_EC_Spiegel_Helligkeit 3;
BA_ "GenSigSwitchedByIgnition" SG_ 977 BT_EC_Spiegel_Helligkeit 0;
BA_ "GenSigSendType" SG_ 977 BT_FH_Bew_hoch 3;
BA_ "GenSigSwitchedByIgnition" SG_ 977 BT_FH_Bew_hoch 0;
BA_ "GenSigSendType" SG_ 977 BT_FH_Bew_tief 3;
BA_ "GenSigSwitchedByIgnition" SG_ 977 BT_FH_Bew_tief 0;
BA_ "GenSigSendType" SG_ 977 BT_FH_Block 3;
BA_ "GenSigSwitchedByIgnition" SG_ 977 BT_FH_Block 0;
BA_ "GenSigSendType" SG_ 977 BT_FH_Fang 3;
BA_ "GenSigSwitchedByIgnition" SG_ 977 BT_FH_Fang 0;
BA_ "GenSigSendType" SG_ 977 BT_FH_normiert 3;
BA_ "GenSigSwitchedByIgnition" SG_ 977 BT_FH_normiert 0;
BA_ "GenSigSendType" SG_ 977 BT_FH_Oeffnung 3;
BA_ "GenSigSwitchedByIgnition" SG_ 977 BT_FH_Oeffnung 0;
BA_ "GenSigSendType" SG_ 977 BT_FH_Pos_oben 3;
BA_ "GenSigSwitchedByIgnition" SG_ 977 BT_FH_Pos_oben 0;
BA_ "GenSigSendType" SG_ 977 BT_FH_S_AutoHoch 3;
BA_ "GenSigSwitchedByIgnition" SG_ 977 BT_FH_S_AutoHoch 0;
BA_ "GenSigSendType" SG_ 977 BT_FH_S_AutoTief 3;
BA_ "GenSigSwitchedByIgnition" SG_ 977 BT_FH_S_AutoTief 0;
BA_ "GenSigSendType" SG_ 977 BT_FH_S_ManHoch 3;
BA_ "GenSigSwitchedByIgnition" SG_ 977 BT_FH_S_ManHoch 0;
BA_ "GenSigSendType" SG_ 977 BT_FH_S_ManTief 3;
BA_ "GenSigSwitchedByIgnition" SG_ 977 BT_FH_S_ManTief 0;
BA_ "GenSigSendType" SG_ 977 BT_FH_Thermo 3;
BA_ "GenSigSwitchedByIgnition" SG_ 977 BT_FH_Thermo 0;
BA_ "GenSigSendType" SG_ 977 BT_gesafet 3;
BA_ "GenSigSwitchedByIgnition" SG_ 977 BT_gesafet 0;
BA_ "GenSigSendType" SG_ 977 BT_Kisi_Fehler 3;
BA_ "GenSigSwitchedByIgnition" SG_ 977 BT_Kisi_Fehler 0;
BA_ "Fehlerwert" SG_ 977 BT_Kisi_Fehler 1;
BA_ "GenSigSendType" SG_ 977 BT_Lock_Taster 3;
BA_ "GenSigSwitchedByIgnition" SG_ 977 BT_Lock_Taster 0;
BA_ "GenSigSendType" SG_ 977 BT_Lock_Taster_inv 3;
BA_ "GenSigSwitchedByIgnition" SG_ 977 BT_Lock_Taster_inv 0;
BA_ "GenSigSendType" SG_ 977 BT_Lock_Unlock_Taster 3;
BA_ "GenSigSwitchedByIgnition" SG_ 977 BT_Lock_Unlock_Taster 0;
BA_ "GenSigSendType" SG_ 977 BT_Oben_Block_erw 3;
BA_ "GenSigSwitchedByIgnition" SG_ 977 BT_Oben_Block_erw 0;
BA_ "GenSigSendType" SG_ 977 BT_Schliesstaster 3;
BA_ "GenSigSwitchedByIgnition" SG_ 977 BT_Schliesstaster 0;
BA_ "GenSigSendType" SG_ 977 BT_Schluesselschalter_auf 3;
BA_ "GenSigSwitchedByIgnition" SG_ 977 BT_Schluesselschalter_auf 0;
BA_ "GenSigSendType" SG_ 977 BT_Schluesselschalter_zu 3;
BA_ "GenSigSwitchedByIgnition" SG_ 977 BT_Schluesselschalter_zu 0;
BA_ "GenSigSendType" SG_ 977 BT_Schluesselschalter_zu_inv 3;
BA_ "GenSigSwitchedByIgnition" SG_ 977 BT_Schluesselschalter_zu_inv 0;
BA_ "GenSigSendType" SG_ 977 BT_SP_ausgerastet 3;
BA_ "GenSigSwitchedByIgnition" SG_ 977 BT_SP_ausgerastet 0;
BA_ "GenSigSendType" SG_ 977 BT_Sp_Blk_def 3;
BA_ "GenSigSwitchedByIgnition" SG_ 977 BT_Sp_Blk_def 0;
BA_ "GenSigSendType" SG_ 977 BT_SP_Heizung_aktiv 3;
BA_ "GenSigSwitchedByIgnition" SG_ 977 BT_SP_Heizung_aktiv 0;
BA_ "GenSigSendType" SG_ 977 BT_Sp_Heizung_Anf 0;
BA_ "GenSigSwitchedByIgnition" SG_ 977 BT_Sp_Heizung_Anf 0;
BA_ "GenSigSendType" SG_ 977 BT_SP_Heizung_Status 3;
BA_ "GenSigSwitchedByIgnition" SG_ 977 BT_SP_Heizung_Status 0;
BA_ "GenSigSendType" SG_ 977 BT_SP_ht_aktiv 3;
BA_ "GenSigSwitchedByIgnition" SG_ 977 BT_SP_ht_aktiv 0;
BA_ "GenSigSendType" SG_ 977 BT_SP_lr_aktiv 3;
BA_ "GenSigSwitchedByIgnition" SG_ 977 BT_SP_lr_aktiv 0;
BA_ "GenSigSendType" SG_ 977 BT_Sperrklinke 3;
BA_ "GenSigSwitchedByIgnition" SG_ 977 BT_Sperrklinke 0;
BA_ "GenSigSendType" SG_ 977 BT_SWA_HMI_defekt 0;
BA_ "GenSigSwitchedByIgnition" SG_ 977 BT_SWA_HMI_defekt 0;
BA_ "GenSigSendType" SG_ 977 BT_TAG_betaetigt 3;
BA_ "GenSigSwitchedByIgnition" SG_ 977 BT_TAG_betaetigt 0;
BA_ "GenSigSendType" SG_ 977 BT_TCR_Mode_aktiv 3;
BA_ "GenSigSwitchedByIgnition" SG_ 977 BT_TCR_Mode_aktiv 0;
BA_ "GenSigSendType" SG_ 977 BT_TIG_betaetigt 3;
BA_ "GenSigSwitchedByIgnition" SG_ 977 BT_TIG_betaetigt 0;
BA_ "GenSigSendType" SG_ 977 BT_TSG_hinten_verbaut 3;
BA_ "GenSigSwitchedByIgnition" SG_ 977 BT_TSG_hinten_verbaut 0;
BA_ "GenSigSendType" SG_ 977 BT_Tuer_geoeffnet 3;
BA_ "GenSigSwitchedByIgnition" SG_ 977 BT_Tuer_geoeffnet 0;
BA_ "GenSigSendType" SG_ 977 BT_Tuer_Status 3;
BA_ "GenSigSwitchedByIgnition" SG_ 977 BT_Tuer_Status 0;
BA_ "Fehlerwert" SG_ 977 BT_Tuer_Status 3;
BA_ "GenSigSendType" SG_ 977 BT_Tuer_Status_QBit 0;
BA_ "GenSigSwitchedByIgnition" SG_ 977 BT_Tuer_Status_QBit 0;
BA_ "GenSigSendType" SG_ 977 BT_Tueroeffnen_Warnung 3;
BA_ "GenSigSwitchedByIgnition" SG_ 977 BT_Tueroeffnen_Warnung 0;
BA_ "GenSigSendType" SG_ 977 BT_Tuerschloss_defekt 0;
BA_ "GenSigSwitchedByIgnition" SG_ 977 BT_Tuerschloss_defekt 0;
BA_ "GenSigSendType" SG_ 977 BT_UEKB_aktiviert 3;
BA_ "GenSigSwitchedByIgnition" SG_ 977 BT_UEKB_aktiviert 0;
BA_ "GenSigSendType" SG_ 977 BT_Unlock_Taster 3;
BA_ "GenSigSwitchedByIgnition" SG_ 977 BT_Unlock_Taster 0;
BA_ "GenSigSendType" SG_ 977 BT_Unten_Block_erw 3;
BA_ "GenSigSwitchedByIgnition" SG_ 977 BT_Unten_Block_erw 0;
BA_ "GenSigSendType" SG_ 977 BT_verriegelt 3;
BA_ "GenSigSwitchedByIgnition" SG_ 977 BT_verriegelt 0;
BA_ "GenSigSendType" SG_ 977 BT_Zuziehhilfe_aktiv 3;
BA_ "GenSigSwitchedByIgnition" SG_ 977 BT_Zuziehhilfe_aktiv 0;
BA_ "GenSigSendType" SG_ 976 ASW_HMI_defekt 0;
BA_ "GenSigSwitchedByIgnition" SG_ 976 ASW_HMI_defekt 0;
BA_ "GenSigSendType" SG_ 976 ASW_wakeup 3;
BA_ "GenSigSwitchedByIgnition" SG_ 976 ASW_wakeup 0;
BA_ "GenSigSendType" SG_ 976 ASW_Warnung_aktiv_FS 3;
BA_ "GenSigSwitchedByIgnition" SG_ 976 ASW_Warnung_aktiv_FS 0;
BA_ "GenSigSendType" SG_ 976 FS_Status_eTAG 3;
BA_ "GenSigSwitchedByIgnition" SG_ 976 FS_Status_eTAG 0;
BA_ "Fehlerwert" SG_ 976 FS_Status_eTAG 3;
BA_ "GenSigSendType" SG_ 976 FT_BFS_Fond_Freigabe 3;
BA_ "GenSigSwitchedByIgnition" SG_ 976 FT_BFS_Fond_Freigabe 0;
BA_ "GenSigSendType" SG_ 976 FT_Daemmglas 3;
BA_ "GenSigSwitchedByIgnition" SG_ 976 FT_Daemmglas 0;
BA_ "GenSigSendType" SG_ 976 FT_FH_Bew_hoch 3;
BA_ "GenSigSwitchedByIgnition" SG_ 976 FT_FH_Bew_hoch 0;
BA_ "GenSigSendType" SG_ 976 FT_FH_Bew_tief 3;
BA_ "GenSigSwitchedByIgnition" SG_ 976 FT_FH_Bew_tief 0;
BA_ "GenSigSendType" SG_ 976 FT_FH_Block 3;
BA_ "GenSigSwitchedByIgnition" SG_ 976 FT_FH_Block 0;
BA_ "GenSigSendType" SG_ 976 FT_FH_Fang 3;
BA_ "GenSigSwitchedByIgnition" SG_ 976 FT_FH_Fang 0;
BA_ "GenSigSendType" SG_ 976 FT_FH_normiert 3;
BA_ "GenSigSwitchedByIgnition" SG_ 976 FT_FH_normiert 0;
BA_ "GenSigSendType" SG_ 976 FT_FH_Oeffnung 3;
BA_ "GenSigSwitchedByIgnition" SG_ 976 FT_FH_Oeffnung 0;
BA_ "GenSigSendType" SG_ 976 FT_FH_Pos_oben 3;
BA_ "GenSigSwitchedByIgnition" SG_ 976 FT_FH_Pos_oben 0;
BA_ "GenSigSendType" SG_ 976 FT_FH_S_AutoHoch 3;
BA_ "GenSigSwitchedByIgnition" SG_ 976 FT_FH_S_AutoHoch 0;
BA_ "GenSigSendType" SG_ 976 FT_FH_S_AutoTief 3;
BA_ "GenSigSwitchedByIgnition" SG_ 976 FT_FH_S_AutoTief 0;
BA_ "GenSigSendType" SG_ 976 FT_FH_S_ManHoch 3;
BA_ "GenSigSwitchedByIgnition" SG_ 976 FT_FH_S_ManHoch 0;
BA_ "GenSigSendType" SG_ 976 FT_FH_S_ManTief 3;
BA_ "GenSigSwitchedByIgnition" SG_ 976 FT_FH_S_ManTief 0;
BA_ "GenSigSendType" SG_ 976 FT_FH_Thermo 3;
BA_ "GenSigSwitchedByIgnition" SG_ 976 FT_FH_Thermo 0;
BA_ "GenSigSendType" SG_ 976 FT_gesafet 3;
BA_ "GenSigSwitchedByIgnition" SG_ 976 FT_gesafet 0;
BA_ "GenSigSendType" SG_ 976 FT_HD_Taste 3;
BA_ "GenSigSwitchedByIgnition" SG_ 976 FT_HD_Taste 0;
BA_ "GenSigSendType" SG_ 976 FT_HD_Taste_2 3;
BA_ "GenSigSwitchedByIgnition" SG_ 976 FT_HD_Taste_2 0;
BA_ "GenSigSendType" SG_ 976 FT_IRUE_Taste 3;
BA_ "GenSigSwitchedByIgnition" SG_ 976 FT_IRUE_Taste 0;
BA_ "GenSigSendType" SG_ 976 FT_Kisi_Fehler 3;
BA_ "GenSigSwitchedByIgnition" SG_ 976 FT_Kisi_Fehler 0;
BA_ "Fehlerwert" SG_ 976 FT_Kisi_Fehler 1;
BA_ "GenSigSendType" SG_ 976 FT_Kisi_li_aktiv 3;
BA_ "GenSigSwitchedByIgnition" SG_ 976 FT_Kisi_li_aktiv 0;
BA_ "GenSigSendType" SG_ 976 FT_Kisi_re_aktiv 3;
BA_ "GenSigSwitchedByIgnition" SG_ 976 FT_Kisi_re_aktiv 0;
BA_ "GenSigSendType" SG_ 976 FT_Kisi_Taster_li 3;
BA_ "GenSigSwitchedByIgnition" SG_ 976 FT_Kisi_Taster_li 0;
BA_ "GenSigSendType" SG_ 976 FT_Kisi_Taster_re 3;
BA_ "GenSigSwitchedByIgnition" SG_ 976 FT_Kisi_Taster_re 0;
BA_ "GenSigSendType" SG_ 976 FT_Lock_Taster 3;
BA_ "GenSigSwitchedByIgnition" SG_ 976 FT_Lock_Taster 0;
BA_ "GenSigSendType" SG_ 976 FT_Lock_Unlock_Taster 3;
BA_ "GenSigSwitchedByIgnition" SG_ 976 FT_Lock_Unlock_Taster 0;
BA_ "GenSigSendType" SG_ 976 FT_Oben_Block_erw 3;
BA_ "GenSigSwitchedByIgnition" SG_ 976 FT_Oben_Block_erw 0;
BA_ "GenSigSendType" SG_ 976 FT_Schliesstaster 3;
BA_ "GenSigSwitchedByIgnition" SG_ 976 FT_Schliesstaster 0;
BA_ "GenSigSendType" SG_ 976 FT_Schluesselschalter_auf 3;
BA_ "GenSigSwitchedByIgnition" SG_ 976 FT_Schluesselschalter_auf 0;
BA_ "GenSigSendType" SG_ 976 FT_Schluesselschalter_zu 3;
BA_ "GenSigSwitchedByIgnition" SG_ 976 FT_Schluesselschalter_zu 0;
BA_ "GenSigSendType" SG_ 976 FT_SP_ausgerastet 3;
BA_ "GenSigSwitchedByIgnition" SG_ 976 FT_SP_ausgerastet 0;
BA_ "GenSigSendType" SG_ 976 FT_Sp_Blk_def 3;
BA_ "GenSigSwitchedByIgnition" SG_ 976 FT_Sp_Blk_def 0;
BA_ "GenSigSendType" SG_ 976 FT_Sp_Heizung_Anf 0;
BA_ "GenSigSwitchedByIgnition" SG_ 976 FT_Sp_Heizung_Anf 0;
BA_ "GenSigSendType" SG_ 976 FT_SP_Heizung_Status 3;
BA_ "GenSigSwitchedByIgnition" SG_ 976 FT_SP_Heizung_Status 0;
BA_ "GenSigSendType" SG_ 976 FT_SP_ht_aktiv 3;
BA_ "GenSigSwitchedByIgnition" SG_ 976 FT_SP_ht_aktiv 0;
BA_ "GenSigSendType" SG_ 976 FT_SP_lr_aktiv 3;
BA_ "GenSigSwitchedByIgnition" SG_ 976 FT_SP_lr_aktiv 0;
BA_ "GenSigSendType" SG_ 976 FT_Sperrklinke 3;
BA_ "GenSigSwitchedByIgnition" SG_ 976 FT_Sperrklinke 0;
BA_ "GenSigSendType" SG_ 976 FT_SWA_Taster 3;
BA_ "GenSigSwitchedByIgnition" SG_ 976 FT_SWA_Taster 0;
BA_ "GenSigSendType" SG_ 976 FT_TAG_betaetigt 3;
BA_ "GenSigSwitchedByIgnition" SG_ 976 FT_TAG_betaetigt 0;
BA_ "GenSigSendType" SG_ 976 FT_TD_Taste 3;
BA_ "GenSigSwitchedByIgnition" SG_ 976 FT_TD_Taste 0;
BA_ "GenSigSendType" SG_ 976 FT_TD_Taste_Fehler 0;
BA_ "GenSigSwitchedByIgnition" SG_ 976 FT_TD_Taste_Fehler 0;
BA_ "GenSigSendType" SG_ 976 FT_TIG_betaetigt 3;
BA_ "GenSigSwitchedByIgnition" SG_ 976 FT_TIG_betaetigt 0;
BA_ "GenSigSendType" SG_ 976 FT_TSG_hinten_verbaut 3;
BA_ "GenSigSwitchedByIgnition" SG_ 976 FT_TSG_hinten_verbaut 0;
BA_ "GenSigSendType" SG_ 976 FT_Tuer_geoeffnet 3;
BA_ "GenSigSwitchedByIgnition" SG_ 976 FT_Tuer_geoeffnet 0;
BA_ "GenSigSendType" SG_ 976 FT_Tuerschloss_defekt 0;
BA_ "GenSigSwitchedByIgnition" SG_ 976 FT_Tuerschloss_defekt 0;
BA_ "GenSigSendType" SG_ 976 FT_UEKB_aktiviert 3;
BA_ "GenSigSwitchedByIgnition" SG_ 976 FT_UEKB_aktiviert 0;
BA_ "GenSigSendType" SG_ 976 FT_Unlock_Taster 3;
BA_ "GenSigSwitchedByIgnition" SG_ 976 FT_Unlock_Taster 0;
BA_ "GenSigSendType" SG_ 976 FT_Unten_Block_erw 3;
BA_ "GenSigSwitchedByIgnition" SG_ 976 FT_Unten_Block_erw 0;
BA_ "GenSigSendType" SG_ 976 FT_verriegelt 3;
BA_ "GenSigSwitchedByIgnition" SG_ 976 FT_verriegelt 0;
BA_ "GenSigSendType" SG_ 976 FT_Zuziehhilfe_aktiv 3;
BA_ "GenSigSwitchedByIgnition" SG_ 976 FT_Zuziehhilfe_aktiv 0;
BA_ "GenSigSendType" SG_ 976 SSR_Temp_Freigabe 0;
BA_ "GenSigSwitchedByIgnition" SG_ 976 SSR_Temp_Freigabe 0;
BA_ "GenSigSendType" SG_ 976 SWA_HMI_Diagnose 0;
BA_ "GenSigSwitchedByIgnition" SG_ 976 SWA_HMI_Diagnose 0;
BA_ "GenSigSendType" SG_ 997 eTAB_FS_Bowdenzug_Auswerfen 3;
BA_ "GenSigSwitchedByIgnition" SG_ 997 eTAB_FS_Bowdenzug_Auswerfen 0;
BA_ "GenSigSendType" SG_ 997 FS_Push_Tuergriff 3;
BA_ "GenSigSwitchedByIgnition" SG_ 997 FS_Push_Tuergriff 0;
BA_ "GenSigSendType" SG_ 997 FS_Status_eTAG_ext 3;
BA_ "GenSigStartValue" SG_ 997 FS_Status_eTAG_ext 3;
BA_ "GenSigSwitchedByIgnition" SG_ 997 FS_Status_eTAG_ext 0;
BA_ "Fehlerwert" SG_ 997 FS_Status_eTAG_ext 4;
BA_ "GenSigSendType" SG_ 997 FT_ASW_Warnton 0;
BA_ "GenSigSwitchedByIgnition" SG_ 997 FT_ASW_Warnton 0;
BA_ "Fehlerwert" SG_ 997 FT_ASW_Warnton 3;
BA_ "GenSigSendType" SG_ 997 FT_BFS_Tuer_Status 3;
BA_ "GenSigSwitchedByIgnition" SG_ 997 FT_BFS_Tuer_Status 0;
BA_ "Fehlerwert" SG_ 997 FT_BFS_Tuer_Status 3;
BA_ "GenSigSendType" SG_ 997 FT_Cargolock_bet 3;
BA_ "GenSigSwitchedByIgnition" SG_ 997 FT_Cargolock_bet 0;
BA_ "GenSigSendType" SG_ 997 FT_HBFS_Tuer_Status 3;
BA_ "GenSigSwitchedByIgnition" SG_ 997 FT_HBFS_Tuer_Status 0;
BA_ "Fehlerwert" SG_ 997 FT_HBFS_Tuer_Status 3;
BA_ "GenSigSendType" SG_ 997 FT_HFS_Tuer_Status 3;
BA_ "GenSigSwitchedByIgnition" SG_ 997 FT_HFS_Tuer_Status 0;
BA_ "Fehlerwert" SG_ 997 FT_HFS_Tuer_Status 3;
BA_ "GenSigSendType" SG_ 997 FT_kisi_asynchron 3;
BA_ "GenSigSwitchedByIgnition" SG_ 997 FT_kisi_asynchron 0;
BA_ "GenSigSendType" SG_ 997 FT_KiSi_Status_Soll_HBFS 0;
BA_ "GenSigSwitchedByIgnition" SG_ 997 FT_KiSi_Status_Soll_HBFS 0;
BA_ "GenSigSendType" SG_ 997 FT_KiSi_Status_Soll_HFS 0;
BA_ "GenSigSwitchedByIgnition" SG_ 997 FT_KiSi_Status_Soll_HFS 0;
BA_ "GenSigSendType" SG_ 997 FT_Kisi_Taster_li_02 3;
BA_ "GenSigSwitchedByIgnition" SG_ 997 FT_Kisi_Taster_li_02 0;
BA_ "GenSigSendType" SG_ 997 FT_Kisi_Taster_re_02 3;
BA_ "GenSigSwitchedByIgnition" SG_ 997 FT_Kisi_Taster_re_02 0;
BA_ "GenSigSendType" SG_ 997 FT_Lock_Taster_02 0;
BA_ "GenSigSwitchedByIgnition" SG_ 997 FT_Lock_Taster_02 0;
BA_ "GenSigSendType" SG_ 997 FT_Schluesselschalter_zu_02 0;
BA_ "GenSigSwitchedByIgnition" SG_ 997 FT_Schluesselschalter_zu_02 0;
BA_ "GenSigSendType" SG_ 997 FT_SP_Heizung_ein 3;
BA_ "GenSigSwitchedByIgnition" SG_ 997 FT_SP_Heizung_ein 0;
BA_ "GenSigSendType" SG_ 997 FT_TCR_Mode_aktiv 3;
BA_ "GenSigSwitchedByIgnition" SG_ 997 FT_TCR_Mode_aktiv 0;
BA_ "GenSigSendType" SG_ 997 FT_TD_Taste_Status 3;
BA_ "GenSigSwitchedByIgnition" SG_ 997 FT_TD_Taste_Status 0;
BA_ "GenSigSendType" SG_ 997 FT_Tuer_Status 3;
BA_ "GenSigSwitchedByIgnition" SG_ 997 FT_Tuer_Status 0;
BA_ "Fehlerwert" SG_ 997 FT_Tuer_Status 3;
BA_ "GenSigSendType" SG_ 997 FT_Tuer_Status_QBit 0;
BA_ "GenSigSwitchedByIgnition" SG_ 997 FT_Tuer_Status_QBit 0;
BA_ "GenSigSendType" SG_ 997 FT_Tueroeffnen_Warnung 3;
BA_ "GenSigSwitchedByIgnition" SG_ 997 FT_Tueroeffnen_Warnung 0;
BA_ "GenSigSendType" SG_ 997 SSA_FT_ASW_Status 3;
BA_ "GenSigSwitchedByIgnition" SG_ 997 SSA_FT_ASW_Status 0;
BA_ "GenSigSendType" SG_ 997 TBF_FS_Touch_Event 3;
BA_ "GenSigSwitchedByIgnition" SG_ 997 TBF_FS_Touch_Event 0;
BA_ "GenSigSendType" SG_ 997 TSG_FS_Spiegel_angeklappt 3;
BA_ "GenSigSwitchedByIgnition" SG_ 997 TSG_FS_Spiegel_angeklappt 0;
BA_ "GenSigSendType" SG_ 997 TSG_FT_02_BZ 0;
BA_ "GenSigFuncType" SG_ 997 TSG_FT_02_BZ 1;
BA_ "GenSigSwitchedByIgnition" SG_ 997 TSG_FT_02_BZ 0;
BA_ "GenSigSendType" SG_ 997 TSG_FT_02_CRC 0;
BA_ "GenSigFuncType" SG_ 997 TSG_FT_02_CRC 2;
BA_ "GenSigSwitchedByIgnition" SG_ 997 TSG_FT_02_CRC 0;
BA_REL_ "GenSigTimeoutTime" BU_SG_REL_ BedienDisp_mi SG_ 1363 SR3_Verriegelungssensor_li 1000;
BA_REL_ "GenSigTimeoutTime" BU_SG_REL_ BedienDisp_mi SG_ 1363 SR3_Verriegelungssensor_re 1000;
BA_REL_ "GenSigTimeoutTime" BU_SG_REL_ BedienDisp_mi SG_ 1413 SI_QRS_Mode 5000;
BA_REL_ "GenSigTimeoutTime" BU_SG_REL_ BedienDisp_mi SG_ 1413 SI_T_Mode 5000;
BA_REL_ "GenSigTimeoutTime" BU_SG_REL_ BedienDisp_mi SG_ 1413 SI_NWDF 5000;
BA_REL_ "GenSigTimeoutTime" BU_SG_REL_ BedienDisp_mi SG_ 1413 SI_NWDF_gueltig 5000;
BA_REL_ "GenSigTimeoutTime" BU_SG_REL_ BedienDisp_mi SG_ 1413 SI_T_Schutz 5000;
BA_REL_ "GenSigTimeoutTime" BU_SG_REL_ BedienDisp_mi SG_ 997 FT_Tuer_Status 1000;
BA_REL_ "GenSigTimeoutTime" BU_SG_REL_ BedienDisp_vo_mi SG_ 1413 SI_P_Mode_gueltig 5000;
BA_REL_ "GenSigTimeoutTime" BU_SG_REL_ BedienDisp_vo_mi SG_ 1413 SI_QRS_Mode 5000;
BA_REL_ "GenSigTimeoutTime" BU_SG_REL_ BedienDisp_vo_mi SG_ 1413 SI_T_Mode 5000;
BA_REL_ "GenSigTimeoutTime" BU_SG_REL_ BedienDisp_vo_mi SG_ 1413 SI_NWDF 5000;
BA_REL_ "GenSigTimeoutTime" BU_SG_REL_ BedienDisp_vo_mi SG_ 1413 SI_NWDF_gueltig 5000;
BA_REL_ "GenSigTimeoutTime" BU_SG_REL_ BedienDisp_vo_mi SG_ 1413 SI_T_Schutz 5000;
BA_REL_ "GenSigTimeoutTime" BU_SG_REL_ BedienDisp_vo_mi SG_ 1413 SI_P_Mode 5000;
BA_REL_ "GenSigTimeoutTime" BU_SG_REL_ BedienDisp_vo_mi SG_ 997 FT_Tuer_Status 1000;
BA_REL_ "GenSigTimeoutTime" BU_SG_REL_ CDI SG_ 1413 SI_QRS_Mode 5000;
BA_REL_ "GenSigTimeoutTime" BU_SG_REL_ CDI SG_ 1413 SI_T_Mode 5000;
BA_REL_ "GenSigTimeoutTime" BU_SG_REL_ CDI SG_ 1413 SI_P_Mode 5000;
BA_REL_ "GenSigTimeoutTime" BU_SG_REL_ ConMod_CD SG_ 1413 SI_P_Mode_gueltig 5000;
BA_REL_ "GenSigTimeoutTime" BU_SG_REL_ ConMod_CD SG_ 1413 SI_QRS_Mode 5000;
BA_REL_ "GenSigTimeoutTime" BU_SG_REL_ ConMod_CD SG_ 1413 SI_T_Mode 5000;
BA_REL_ "GenSigTimeoutTime" BU_SG_REL_ ConMod_CD SG_ 1413 SI_NWDF 5000;
BA_REL_ "GenSigTimeoutTime" BU_SG_REL_ ConMod_CD SG_ 1413 SI_NWDF_gueltig 5000;
BA_REL_ "GenSigTimeoutTime" BU_SG_REL_ ConMod_CD SG_ 1413 SI_T_Schutz 5000;
BA_REL_ "GenSigTimeoutTime" BU_SG_REL_ ConMod_CD SG_ 1413 SI_P_Mode 5000;
BA_REL_ "GenSigTimeoutTime" BU_SG_REL_ DashCAM SG_ 1413 SI_QRS_Mode 5000;
BA_REL_ "GenSigTimeoutTime" BU_SG_REL_ DashCAM SG_ 1413 SI_T_Mode 5000;
BA_REL_ "GenSigTimeoutTime" BU_SG_REL_ DashCAM SG_ 1413 SI_NWDF 5000;
BA_REL_ "GenSigTimeoutTime" BU_SG_REL_ DashCAM SG_ 1413 SI_NWDF_gueltig 5000;
BA_REL_ "GenSigTimeoutTime" BU_SG_REL_ DashCAM SG_ 1413 SI_T_Schutz 5000;
BA_REL_ "GenSigTimeoutTime" BU_SG_REL_ Gateway_Max SG_ 1313 STH_Funk_ein 2000;
BA_REL_ "GenSigTimeoutTime" BU_SG_REL_ Gateway_Max SG_ 1313 STH_Funk_aus 2000;
BA_REL_ "GenSigTimeoutTime" BU_SG_REL_ Gateway_Max SG_ 1313 STH_Zusatzheizung 2000;
BA_REL_ "GenSigTimeoutTime" BU_SG_REL_ Gateway_Max SG_ 1313 STH_LED 2000;
BA_REL_ "GenSigTimeoutTime" BU_SG_REL_ Gateway_Max SG_ 1313 STH_Geblaese 2000;
BA_REL_ "GenSigTimeoutTime" BU_SG_REL_ Gateway_Max SG_ 1313 STH_Heizleistung 2000;
BA_REL_ "GenSigTimeoutTime" BU_SG_REL_ Gateway_Max SG_ 1313 STH_Texte 2000;
BA_REL_ "GenSigTimeoutTime" BU_SG_REL_ Gateway_Max SG_ 1637 TF_Telephone_State 5000;
BA_REL_ "GenSigTimeoutTime" BU_SG_REL_ Gateway_Max SG_ 1447 MOD_Energie_Anf 5000;
BA_REL_ "GenSigTimeoutTime" BU_SG_REL_ Gateway_Max SG_ 1447 eCall_Mute_Anf 5000;
BA_REL_ "GenSigTimeoutTime" BU_SG_REL_ Gateway_Max SG_ 1447 eCall_Funktionsstatus_02 5000;
BA_REL_ "GenSigTimeoutTime" BU_SG_REL_ ICC_IO_Node SG_ 1413 SI_P_Mode_gueltig 5000;
BA_REL_ "GenSigTimeoutTime" BU_SG_REL_ ICC_IO_Node SG_ 1413 SI_QRS_Mode 5000;
BA_REL_ "GenSigTimeoutTime" BU_SG_REL_ ICC_IO_Node SG_ 1413 SI_T_Mode 5000;
BA_REL_ "GenSigTimeoutTime" BU_SG_REL_ ICC_IO_Node SG_ 1413 SI_NWDF 5000;
BA_REL_ "GenSigTimeoutTime" BU_SG_REL_ ICC_IO_Node SG_ 1413 SI_NWDF_gueltig 5000;
BA_REL_ "GenSigTimeoutTime" BU_SG_REL_ ICC_IO_Node SG_ 1413 SI_T_Schutz 5000;
BA_REL_ "GenSigTimeoutTime" BU_SG_REL_ ICC_IO_Node SG_ 1413 SI_P_Mode 5000;
BA_REL_ "GenSigTimeoutTime" BU_SG_REL_ ICC_IO_Node SG_ 1413 SI_BUS_01 5000;
BA_REL_ "GenSigTimeoutTime" BU_SG_REL_ ICC_IO_Node SG_ 1413 SI_BUS_02 5000;
BA_REL_ "GenSigTimeoutTime" BU_SG_REL_ ICC_IO_Node SG_ 1413 SI_BUS_03 5000;
BA_REL_ "GenSigTimeoutTime" BU_SG_REL_ ICC_IO_Node SG_ 1413 SI_BUS_04 5000;
BA_REL_ "GenSigTimeoutTime" BU_SG_REL_ ICC_IO_Node SG_ 1413 SI_BUS_05 5000;
BA_REL_ "GenSigTimeoutTime" BU_SG_REL_ ICC_IO_Node SG_ 1413 SI_BUS_06 5000;
BA_REL_ "GenSigTimeoutTime" BU_SG_REL_ ICC_IO_Node SG_ 1413 SI_BUS_07 5000;
BA_REL_ "GenSigTimeoutTime" BU_SG_REL_ ICC_IO_Node SG_ 1413 SI_BUS_08 5000;
BA_REL_ "GenSigTimeoutTime" BU_SG_REL_ ICC_IO_Node SG_ 1413 SI_BUS_09 5000;
BA_REL_ "GenSigTimeoutTime" BU_SG_REL_ ICC_IO_Node SG_ 1413 SI_BUS_10 5000;
BA_REL_ "GenSigTimeoutTime" BU_SG_REL_ ICC_IO_Node SG_ 1413 SI_BUS_12 5000;
BA_REL_ "GenSigTimeoutTime" BU_SG_REL_ ICC_IO_Node SG_ 1413 SI_BUS_13 5000;
BA_REL_ "GenSigTimeoutTime" BU_SG_REL_ ICC_IO_Node SG_ 1413 SI_BUS_14 5000;
BA_REL_ "GenSigTimeoutTime" BU_SG_REL_ ICC_IO_Node SG_ 1413 SI_Bus_Identifikation 5000;
BA_REL_ "GenSigTimeoutTime" BU_SG_REL_ ICC_IO_Node SG_ 1413 SI_CAB_V14 5000;
BA_REL_ "GenSigTimeoutTime" BU_SG_REL_ ICC_IO_Node SG_ 997 TBF_FS_Touch_Event 1000;
BA_REL_ "GenSigTimeoutTime" BU_SG_REL_ LSH SG_ 1313 STH_Zusatzheizung 2000;
BA_REL_ "GenSigTimeoutTime" BU_SG_REL_ LSH SG_ 1313 STH_LED 2000;
BA_REL_ "GenSigTimeoutTime" BU_SG_REL_ LSH SG_ 1313 STH_EKP_Anst 2000;
BA_REL_ "GenSigTimeoutTime" BU_SG_REL_ LSH SG_ 1313 STH_Fehlerstatus 2000;
BA_REL_ "GenSigTimeoutTime" BU_SG_REL_ LSH SG_ 1313 STH_Heizleistung 2000;
BA_REL_ "GenSigTimeoutTime" BU_SG_REL_ LSH SG_ 1413 SI_QRS_Mode 5000;
BA_REL_ "GenSigTimeoutTime" BU_SG_REL_ LSH SG_ 1413 SI_NWDF 5000;
BA_REL_ "GenSigTimeoutTime" BU_SG_REL_ LSH SG_ 1413 SI_NWDF_gueltig 5000;
BA_REL_ "GenSigTimeoutTime" BU_SG_REL_ LSH SG_ 1413 SI_T_Schutz 5000;
BA_REL_ "GenSigTimeoutTime" BU_SG_REL_ LSH SG_ 1413 SI_BUS_01 5000;
BA_REL_ "GenSigTimeoutTime" BU_SG_REL_ LSH SG_ 1413 SI_BUS_03 5000;
BA_REL_ "GenSigTimeoutTime" BU_SG_REL_ OCU SG_ 1529 RDK_FMVSS138_Lampe 5000;
BA_REL_ "GenSigTimeoutTime" BU_SG_REL_ OCU SG_ 1529 RDK_FMVSS138_MIL 5000;
BA_REL_ "GenSigTimeoutTime" BU_SG_REL_ OCU SG_ 1529 RDK_Kalibrierung 5000;
BA_REL_ "GenSigTimeoutTime" BU_SG_REL_ OCU SG_ 1527 RW_Texte 5000;
BA_REL_ "GenSigTimeoutTime" BU_SG_REL_ OCU SG_ 1527 RW_Reservewarnung_aktiv 5000;
BA_REL_ "GenSigTimeoutTime" BU_SG_REL_ OCU SG_ 1527 RW_Reichweite_Einheit_Anzeige 5000;
BA_REL_ "GenSigTimeoutTime" BU_SG_REL_ OCU SG_ 1527 RW_Gesamt_Reichweite_Anzeige 5000;
BA_REL_ "GenSigTimeoutTime" BU_SG_REL_ OCU SG_ 1527 RW_Primaer_Reichweite_Anzeige 5000;
BA_REL_ "GenSigTimeoutTime" BU_SG_REL_ OCU SG_ 1527 RW_Sekundaer_Reichweite_Anzeige 5000;
BA_REL_ "GenSigTimeoutTime" BU_SG_REL_ OCU SG_ 1527 RW_Sekundaer_Reichweite 5000;
BA_REL_ "GenSigTimeoutTime" BU_SG_REL_ OCU SG_ 1527 RW_Sek_Reichweitenv_Einheit 5000;
BA_REL_ "GenSigTimeoutTime" BU_SG_REL_ OCU SG_ 1527 RW_Sek_Reichweitenverbrauch 5000;
BA_REL_ "GenSigTimeoutTime" BU_SG_REL_ OCU SG_ 1610 RKA_FMVSS138_Lampe 5000;
BA_REL_ "GenSigTimeoutTime" BU_SG_REL_ OCU SG_ 1610 RKA_FMVSS138_MIL 5000;
BA_REL_ "GenSigTimeoutTime" BU_SG_REL_ OCU SG_ 1610 RKA_Warnungen_02 5000;
BA_REL_ "GenSigTimeoutTime" BU_SG_REL_ OCU SG_ 1610 RKA_Reifentyp 5000;
BA_REL_ "GenSigTimeoutTime" BU_SG_REL_ OCU SG_ 1440 LS_Helligkeit_IR 2000;
BA_REL_ "GenSigTimeoutTime" BU_SG_REL_ OCU SG_ 1440 LS_Helligkeit_FW 2000;
BA_REL_ "GenSigTimeoutTime" BU_SG_REL_ OCU SG_ 1440 LS_defekt 2000;
BA_REL_ "GenSigTimeoutTime" BU_SG_REL_ OCU SG_ 1440 LS_Verbau 2000;
BA_REL_ "GenSigTimeoutTime" BU_SG_REL_ OCU SG_ 1440 RS_Regenmenge 2000;
BA_REL_ "GenSigTimeoutTime" BU_SG_REL_ OCU SG_ 1440 RS_Schwall 2000;
BA_REL_ "GenSigTimeoutTime" BU_SG_REL_ OCU SG_ 1440 RS_Verbau 2000;
BA_REL_ "GenSigTimeoutTime" BU_SG_REL_ OCU SG_ 1440 RS_defekt 2000;
BA_REL_ "GenSigTimeoutTime" BU_SG_REL_ OCU SG_ 1440 RS_Wischergeschwindigkeit 2000;
BA_REL_ "GenSigTimeoutTime" BU_SG_REL_ OCU SG_ 1504 MD1_Position 5000;
BA_REL_ "GenSigTimeoutTime" BU_SG_REL_ OCU SG_ 1504 MD1_Lage 5000;
BA_REL_ "GenSigTimeoutTime" BU_SG_REL_ OCU SG_ 1504 MD3_Position 5000;
BA_REL_ "GenSigTimeoutTime" BU_SG_REL_ OCU SG_ 1504 MD3_Lage 5000;
BA_REL_ "GenSigTimeoutTime" BU_SG_REL_ OCU SG_ 1504 MRollo_Position 5000;
BA_REL_ "GenSigTimeoutTime" BU_SG_REL_ OCU SG_ 1504 MRollo_Lage 5000;
BA_REL_ "GenSigTimeoutTime" BU_SG_REL_ OCU SG_ 1167 SK1_MUX 1000;
BA_REL_ "GenSigTimeoutTime" BU_SG_REL_ OCU SG_ 1167 SK1_Key_Data_1 1000;
BA_REL_ "GenSigTimeoutTime" BU_SG_REL_ OCU SG_ 1167 SK1_Key_Data_2 1000;
BA_REL_ "GenSigTimeoutTime" BU_SG_REL_ OCU SG_ 1167 SK1_Key_Data_3 1000;
BA_REL_ "GenSigTimeoutTime" BU_SG_REL_ OCU SG_ 1167 SK1_Key_Data_4 1000;
BA_REL_ "GenSigTimeoutTime" BU_SG_REL_ OCU SG_ 1167 SK1_Key_Data_5 1000;
BA_REL_ "GenSigTimeoutTime" BU_SG_REL_ OCU SG_ 1167 SK1_Key_Data_6 1000;
BA_REL_ "GenSigTimeoutTime" BU_SG_REL_ OCU SG_ 1167 SK1_Key_Data_7 1000;
BA_REL_ "GenSigTimeoutTime" BU_SG_REL_ OCU SG_ 1167 SK1_Key_Data_8 1000;
BA_REL_ "GenSigTimeoutTime" BU_SG_REL_ OCU SG_ 1167 SK1_Key_Data_9 1000;
BA_REL_ "GenSigTimeoutTime" BU_SG_REL_ OCU SG_ 980 BH_Blinker_li 5000;
BA_REL_ "GenSigTimeoutTime" BU_SG_REL_ OCU SG_ 980 BH_Blinker_re 5000;
BA_REL_ "GenSigTimeoutTime" BU_SG_REL_ OCU SG_ 980 BH_Lichthupe 5000;
BA_REL_ "GenSigTimeoutTime" BU_SG_REL_ OCU SG_ 980 BH_Fernlicht 5000;
BA_REL_ "GenSigTimeoutTime" BU_SG_REL_ OCU SG_ 980 WH_Tipwischen 5000;
BA_REL_ "GenSigTimeoutTime" BU_SG_REL_ OCU SG_ 980 WH_Intervall 5000;
BA_REL_ "GenSigTimeoutTime" BU_SG_REL_ OCU SG_ 980 WH_WischerStufe1 5000;
BA_REL_ "GenSigTimeoutTime" BU_SG_REL_ OCU SG_ 980 WH_WischerStufe2 5000;
BA_REL_ "GenSigTimeoutTime" BU_SG_REL_ OCU SG_ 980 WH_Frontwaschen 5000;
BA_REL_ "GenSigTimeoutTime" BU_SG_REL_ OCU SG_ 980 WH_Heckintervall 5000;
BA_REL_ "GenSigTimeoutTime" BU_SG_REL_ OCU SG_ 980 WH_Heckwaschen 5000;
BA_REL_ "GenSigTimeoutTime" BU_SG_REL_ OCU SG_ 980 WH_Intervallstufen 5000;
BA_REL_ "GenSigTimeoutTime" BU_SG_REL_ OCU SG_ 980 SMLS_Hupe 5000;
BA_REL_ "GenSigTimeoutTime" BU_SG_REL_ OCU SG_ 1467 SoSe_SunInt_2D_Li 5000;
BA_REL_ "GenSigTimeoutTime" BU_SG_REL_ OCU SG_ 1467 SoSe_SunInt_2D_Re 5000;
BA_REL_ "GenSigTimeoutTime" BU_SG_REL_ OCU SG_ 1313 STH_KVS 2000;
BA_REL_ "GenSigTimeoutTime" BU_SG_REL_ OCU SG_ 1313 STH_KVS_Ueberlauf 2000;
BA_REL_ "GenSigTimeoutTime" BU_SG_REL_ OCU SG_ 673 SWA_Status 2000;
BA_REL_ "GenSigTimeoutTime" BU_SG_REL_ OCU SG_ 1413 SI_P_Mode_gueltig 5000;
BA_REL_ "GenSigTimeoutTime" BU_SG_REL_ OCU SG_ 1413 SI_QRS_Mode 5000;
BA_REL_ "GenSigTimeoutTime" BU_SG_REL_ OCU SG_ 1413 SI_T_Mode 5000;
BA_REL_ "GenSigTimeoutTime" BU_SG_REL_ OCU SG_ 1413 SI_NWDF 5000;
BA_REL_ "GenSigTimeoutTime" BU_SG_REL_ OCU SG_ 1413 SI_NWDF_gueltig 5000;
BA_REL_ "GenSigTimeoutTime" BU_SG_REL_ OCU SG_ 1413 SI_T_Schutz 5000;
BA_REL_ "GenSigTimeoutTime" BU_SG_REL_ OCU SG_ 1413 SI_P_Mode 5000;
BA_REL_ "GenSigTimeoutTime" BU_SG_REL_ OCU SG_ 977 BT_Tuer_geoeffnet 1000;
BA_REL_ "GenSigTimeoutTime" BU_SG_REL_ OCU SG_ 977 BT_verriegelt 1000;
BA_REL_ "GenSigTimeoutTime" BU_SG_REL_ OCU SG_ 977 BT_gesafet 1000;
BA_REL_ "GenSigTimeoutTime" BU_SG_REL_ OCU SG_ 977 BT_Tuer_Status 1000;
BA_REL_ "GenSigTimeoutTime" BU_SG_REL_ OCU SG_ 977 BT_FH_Oeffnung 1000;
BA_REL_ "GenSigTimeoutTime" BU_SG_REL_ OCU SG_ 977 BT_FH_Fang 1000;
BA_REL_ "GenSigTimeoutTime" BU_SG_REL_ OCU SG_ 977 BT_FH_normiert 1000;
BA_REL_ "GenSigTimeoutTime" BU_SG_REL_ OCU SG_ 976 FT_Tuer_geoeffnet 1000;
BA_REL_ "GenSigTimeoutTime" BU_SG_REL_ OCU SG_ 976 FT_verriegelt 1000;
BA_REL_ "GenSigTimeoutTime" BU_SG_REL_ OCU SG_ 976 FT_gesafet 1000;
BA_REL_ "GenSigTimeoutTime" BU_SG_REL_ OCU SG_ 976 FT_FH_Oeffnung 1000;
BA_REL_ "GenSigTimeoutTime" BU_SG_REL_ OCU SG_ 976 FT_FH_Fang 1000;
BA_REL_ "GenSigTimeoutTime" BU_SG_REL_ OCU SG_ 976 FT_FH_normiert 1000;
BA_REL_ "GenSigTimeoutTime" BU_SG_REL_ OCU SG_ 976 FT_Kisi_li_aktiv 1000;
BA_REL_ "GenSigTimeoutTime" BU_SG_REL_ OCU SG_ 976 FT_Kisi_re_aktiv 1000;
BA_REL_ "GenSigTimeoutTime" BU_SG_REL_ OCU SG_ 997 FT_Tuer_Status 1000;
BA_REL_ "GenSigTimeoutTime" BU_SG_REL_ RDK_RS3 SG_ 1413 SI_QRS_Mode 5000;
BA_REL_ "GenSigTimeoutTime" BU_SG_REL_ RDK_RS3 SG_ 1413 SI_T_Mode 5000;
BA_REL_ "GenSigTimeoutTime" BU_SG_REL_ RDK_RS3 SG_ 1413 SI_NWDF 5000;
BA_REL_ "GenSigTimeoutTime" BU_SG_REL_ RDK_RS3 SG_ 1413 SI_NWDF_gueltig 5000;
BA_REL_ "GenSigTimeoutTime" BU_SG_REL_ STH SG_ 1413 SI_QRS_Mode 5000;
BA_REL_ "GenSigTimeoutTime" BU_SG_REL_ STH SG_ 1413 SI_NWDF 5000;
BA_REL_ "GenSigTimeoutTime" BU_SG_REL_ STH SG_ 1413 SI_NWDF_gueltig 5000;
BA_REL_ "GenSigTimeoutTime" BU_SG_REL_ STH SG_ 1413 SI_T_Schutz 5000;
BA_REL_ "GenSigTimeoutTime" BU_SG_REL_ STH SG_ 1413 SI_BUS_01 5000;
BA_REL_ "GenSigTimeoutTime" BU_SG_REL_ STH SG_ 1413 SI_BUS_03 5000;
BA_REL_ "GenSigTimeoutTime" BU_SG_REL_ ZR_MIB_EINSTIEG_ab_Gen3 SG_ 1711 RV_Video_on 5000;
BA_REL_ "GenSigTimeoutTime" BU_SG_REL_ ZR_MIB_EINSTIEG_ab_Gen3 SG_ 2463978734 VPS_PaCo_CurrentVideoState 1000;
BA_REL_ "GenSigTimeoutTime" BU_SG_REL_ ZR_MIB_EINSTIEG_ab_Gen3 SG_ 1167 SK1_MUX 1000;
BA_REL_ "GenSigTimeoutTime" BU_SG_REL_ ZR_MIB_EINSTIEG_ab_Gen3 SG_ 1167 SK1_Key_Data_1 1000;
BA_REL_ "GenSigTimeoutTime" BU_SG_REL_ ZR_MIB_EINSTIEG_ab_Gen3 SG_ 1167 SK1_Key_Data_2 1000;
BA_REL_ "GenSigTimeoutTime" BU_SG_REL_ ZR_MIB_EINSTIEG_ab_Gen3 SG_ 1167 SK1_Key_Data_3 1000;
BA_REL_ "GenSigTimeoutTime" BU_SG_REL_ ZR_MIB_EINSTIEG_ab_Gen3 SG_ 1167 SK1_Key_Data_4 1000;
BA_REL_ "GenSigTimeoutTime" BU_SG_REL_ ZR_MIB_EINSTIEG_ab_Gen3 SG_ 1167 SK1_Key_Data_5 1000;
BA_REL_ "GenSigTimeoutTime" BU_SG_REL_ ZR_MIB_EINSTIEG_ab_Gen3 SG_ 1167 SK1_Key_Data_6 1000;
BA_REL_ "GenSigTimeoutTime" BU_SG_REL_ ZR_MIB_EINSTIEG_ab_Gen3 SG_ 1167 SK1_Key_Data_7 1000;
BA_REL_ "GenSigTimeoutTime" BU_SG_REL_ ZR_MIB_EINSTIEG_ab_Gen3 SG_ 1167 SK1_Key_Data_8 1000;
BA_REL_ "GenSigTimeoutTime" BU_SG_REL_ ZR_MIB_EINSTIEG_ab_Gen3 SG_ 1167 SK1_Key_Data_9 1000;
BA_REL_ "GenSigTimeoutTime" BU_SG_REL_ ZR_MIB_EINSTIEG_ab_Gen3 SG_ 980 BH_Blinker_li 5000;
BA_REL_ "GenSigTimeoutTime" BU_SG_REL_ ZR_MIB_EINSTIEG_ab_Gen3 SG_ 980 BH_Blinker_re 5000;
BA_REL_ "GenSigTimeoutTime" BU_SG_REL_ ZR_MIB_EINSTIEG_ab_Gen3 SG_ 673 ASW_Ton_Richtung_VL 2000;
BA_REL_ "GenSigTimeoutTime" BU_SG_REL_ ZR_MIB_EINSTIEG_ab_Gen3 SG_ 673 ASW_Ton_Richtung_VR 2000;
BA_REL_ "GenSigTimeoutTime" BU_SG_REL_ ZR_MIB_EINSTIEG_ab_Gen3 SG_ 673 ASW_Ton_Richtung_HL 2000;
BA_REL_ "GenSigTimeoutTime" BU_SG_REL_ ZR_MIB_EINSTIEG_ab_Gen3 SG_ 673 ASW_Ton_Richtung_HR 2000;
BA_REL_ "GenSigTimeoutTime" BU_SG_REL_ ZR_MIB_EINSTIEG_ab_Gen3 SG_ 1413 SI_P_Mode_gueltig 5000;
BA_REL_ "GenSigTimeoutTime" BU_SG_REL_ ZR_MIB_EINSTIEG_ab_Gen3 SG_ 1413 SI_QRS_Mode 5000;
BA_REL_ "GenSigTimeoutTime" BU_SG_REL_ ZR_MIB_EINSTIEG_ab_Gen3 SG_ 1413 SI_T_Mode 5000;
BA_REL_ "GenSigTimeoutTime" BU_SG_REL_ ZR_MIB_EINSTIEG_ab_Gen3 SG_ 1413 SI_NWDF 5000;
BA_REL_ "GenSigTimeoutTime" BU_SG_REL_ ZR_MIB_EINSTIEG_ab_Gen3 SG_ 1413 SI_NWDF_gueltig 5000;
BA_REL_ "GenSigTimeoutTime" BU_SG_REL_ ZR_MIB_EINSTIEG_ab_Gen3 SG_ 1413 SI_T_Schutz 5000;
BA_REL_ "GenSigTimeoutTime" BU_SG_REL_ ZR_MIB_EINSTIEG_ab_Gen3 SG_ 1413 SI_P_Mode 5000;
BA_REL_ "GenSigTimeoutTime" BU_SG_REL_ ZR_MIB_EINSTIEG_ab_Gen3 SG_ 1413 SI_BUS_01 5000;
BA_REL_ "GenSigTimeoutTime" BU_SG_REL_ ZR_MIB_EINSTIEG_ab_Gen3 SG_ 1413 SI_BUS_02 5000;
BA_REL_ "GenSigTimeoutTime" BU_SG_REL_ ZR_MIB_EINSTIEG_ab_Gen3 SG_ 1413 SI_BUS_03 5000;
BA_REL_ "GenSigTimeoutTime" BU_SG_REL_ ZR_MIB_EINSTIEG_ab_Gen3 SG_ 1413 SI_BUS_04 5000;
BA_REL_ "GenSigTimeoutTime" BU_SG_REL_ ZR_MIB_EINSTIEG_ab_Gen3 SG_ 1413 SI_BUS_05 5000;
BA_REL_ "GenSigTimeoutTime" BU_SG_REL_ ZR_MIB_EINSTIEG_ab_Gen3 SG_ 1413 SI_BUS_06 5000;
BA_REL_ "GenSigTimeoutTime" BU_SG_REL_ ZR_MIB_EINSTIEG_ab_Gen3 SG_ 1413 SI_BUS_07 5000;
BA_REL_ "GenSigTimeoutTime" BU_SG_REL_ ZR_MIB_EINSTIEG_ab_Gen3 SG_ 1413 SI_BUS_08 5000;
BA_REL_ "GenSigTimeoutTime" BU_SG_REL_ ZR_MIB_EINSTIEG_ab_Gen3 SG_ 1413 SI_BUS_09 5000;
BA_REL_ "GenSigTimeoutTime" BU_SG_REL_ ZR_MIB_EINSTIEG_ab_Gen3 SG_ 1413 SI_BUS_10 5000;
BA_REL_ "GenSigTimeoutTime" BU_SG_REL_ ZR_MIB_EINSTIEG_ab_Gen3 SG_ 1413 SI_BUS_12 5000;
BA_REL_ "GenSigTimeoutTime" BU_SG_REL_ ZR_MIB_EINSTIEG_ab_Gen3 SG_ 1413 SI_BUS_13 5000;
BA_REL_ "GenSigTimeoutTime" BU_SG_REL_ ZR_MIB_EINSTIEG_ab_Gen3 SG_ 1413 SI_BUS_14 5000;
BA_REL_ "GenSigTimeoutTime" BU_SG_REL_ ZR_MIB_EINSTIEG_ab_Gen3 SG_ 1413 SI_Bus_Identifikation 5000;
BA_REL_ "GenSigTimeoutTime" BU_SG_REL_ ZR_MIB_EINSTIEG_ab_Gen3 SG_ 1413 SI_CAB_V14 5000;
BA_REL_ "GenSigTimeoutTime" BU_SG_REL_ ZR_MIB_OPTION_ab_Gen3 SG_ 2463978734 VPS_PaCo_CurrentVideoState 1000;
BA_REL_ "GenSigTimeoutTime" BU_SG_REL_ ZR_MIB_OPTION_ab_Gen3 SG_ 1167 SK1_MUX 1000;
BA_REL_ "GenSigTimeoutTime" BU_SG_REL_ ZR_MIB_OPTION_ab_Gen3 SG_ 1167 SK1_Key_Data_1 1000;
BA_REL_ "GenSigTimeoutTime" BU_SG_REL_ ZR_MIB_OPTION_ab_Gen3 SG_ 1167 SK1_Key_Data_2 1000;
BA_REL_ "GenSigTimeoutTime" BU_SG_REL_ ZR_MIB_OPTION_ab_Gen3 SG_ 1167 SK1_Key_Data_3 1000;
BA_REL_ "GenSigTimeoutTime" BU_SG_REL_ ZR_MIB_OPTION_ab_Gen3 SG_ 1167 SK1_Key_Data_4 1000;
BA_REL_ "GenSigTimeoutTime" BU_SG_REL_ ZR_MIB_OPTION_ab_Gen3 SG_ 1167 SK1_Key_Data_5 1000;
BA_REL_ "GenSigTimeoutTime" BU_SG_REL_ ZR_MIB_OPTION_ab_Gen3 SG_ 1167 SK1_Key_Data_6 1000;
BA_REL_ "GenSigTimeoutTime" BU_SG_REL_ ZR_MIB_OPTION_ab_Gen3 SG_ 1167 SK1_Key_Data_7 1000;
BA_REL_ "GenSigTimeoutTime" BU_SG_REL_ ZR_MIB_OPTION_ab_Gen3 SG_ 1167 SK1_Key_Data_8 1000;
BA_REL_ "GenSigTimeoutTime" BU_SG_REL_ ZR_MIB_OPTION_ab_Gen3 SG_ 1167 SK1_Key_Data_9 1000;
BA_REL_ "GenSigTimeoutTime" BU_SG_REL_ ZR_MIB_OPTION_ab_Gen3 SG_ 980 BH_Blinker_li 5000;
BA_REL_ "GenSigTimeoutTime" BU_SG_REL_ ZR_MIB_OPTION_ab_Gen3 SG_ 980 BH_Blinker_re 5000;
BA_REL_ "GenSigTimeoutTime" BU_SG_REL_ ZR_MIB_OPTION_ab_Gen3 SG_ 673 ASW_Ton_Richtung_VL 2000;
BA_REL_ "GenSigTimeoutTime" BU_SG_REL_ ZR_MIB_OPTION_ab_Gen3 SG_ 673 ASW_Ton_Richtung_VR 2000;
BA_REL_ "GenSigTimeoutTime" BU_SG_REL_ ZR_MIB_OPTION_ab_Gen3 SG_ 673 ASW_Ton_Richtung_HL 2000;
BA_REL_ "GenSigTimeoutTime" BU_SG_REL_ ZR_MIB_OPTION_ab_Gen3 SG_ 673 ASW_Ton_Richtung_HR 2000;
BA_REL_ "GenSigTimeoutTime" BU_SG_REL_ ZR_MIB_OPTION_ab_Gen3 SG_ 1413 SI_P_Mode_gueltig 5000;
BA_REL_ "GenSigTimeoutTime" BU_SG_REL_ ZR_MIB_OPTION_ab_Gen3 SG_ 1413 SI_QRS_Mode 5000;
BA_REL_ "GenSigTimeoutTime" BU_SG_REL_ ZR_MIB_OPTION_ab_Gen3 SG_ 1413 SI_T_Mode 5000;
BA_REL_ "GenSigTimeoutTime" BU_SG_REL_ ZR_MIB_OPTION_ab_Gen3 SG_ 1413 SI_NWDF 5000;
BA_REL_ "GenSigTimeoutTime" BU_SG_REL_ ZR_MIB_OPTION_ab_Gen3 SG_ 1413 SI_NWDF_gueltig 5000;
BA_REL_ "GenSigTimeoutTime" BU_SG_REL_ ZR_MIB_OPTION_ab_Gen3 SG_ 1413 SI_T_Schutz 5000;
BA_REL_ "GenSigTimeoutTime" BU_SG_REL_ ZR_MIB_OPTION_ab_Gen3 SG_ 1413 SI_P_Mode 5000;
BA_REL_ "GenSigTimeoutTime" BU_SG_REL_ ZR_MIB_OPTION_ab_Gen3 SG_ 1413 SI_BUS_01 5000;
BA_REL_ "GenSigTimeoutTime" BU_SG_REL_ ZR_MIB_OPTION_ab_Gen3 SG_ 1413 SI_BUS_02 5000;
BA_REL_ "GenSigTimeoutTime" BU_SG_REL_ ZR_MIB_OPTION_ab_Gen3 SG_ 1413 SI_BUS_03 5000;
BA_REL_ "GenSigTimeoutTime" BU_SG_REL_ ZR_MIB_OPTION_ab_Gen3 SG_ 1413 SI_BUS_04 5000;
BA_REL_ "GenSigTimeoutTime" BU_SG_REL_ ZR_MIB_OPTION_ab_Gen3 SG_ 1413 SI_BUS_05 5000;
BA_REL_ "GenSigTimeoutTime" BU_SG_REL_ ZR_MIB_OPTION_ab_Gen3 SG_ 1413 SI_BUS_06 5000;
BA_REL_ "GenSigTimeoutTime" BU_SG_REL_ ZR_MIB_OPTION_ab_Gen3 SG_ 1413 SI_BUS_07 5000;
BA_REL_ "GenSigTimeoutTime" BU_SG_REL_ ZR_MIB_OPTION_ab_Gen3 SG_ 1413 SI_BUS_08 5000;
BA_REL_ "GenSigTimeoutTime" BU_SG_REL_ ZR_MIB_OPTION_ab_Gen3 SG_ 1413 SI_BUS_09 5000;
BA_REL_ "GenSigTimeoutTime" BU_SG_REL_ ZR_MIB_OPTION_ab_Gen3 SG_ 1413 SI_BUS_10 5000;
BA_REL_ "GenSigTimeoutTime" BU_SG_REL_ ZR_MIB_OPTION_ab_Gen3 SG_ 1413 SI_BUS_12 5000;
BA_REL_ "GenSigTimeoutTime" BU_SG_REL_ ZR_MIB_OPTION_ab_Gen3 SG_ 1413 SI_BUS_13 5000;
BA_REL_ "GenSigTimeoutTime" BU_SG_REL_ ZR_MIB_OPTION_ab_Gen3 SG_ 1413 SI_BUS_14 5000;
BA_REL_ "GenSigTimeoutTime" BU_SG_REL_ ZR_MIB_OPTION_ab_Gen3 SG_ 1413 SI_Bus_Identifikation 5000;
BA_REL_ "GenSigTimeoutTime" BU_SG_REL_ ZR_MIB_OPTION_ab_Gen3 SG_ 1413 SI_CAB_V14 5000;
BA_REL_ "GenSigTimeoutTime" BU_SG_REL_ ZR_MIB_TOP_ab_Gen3 SG_ 1711 RV_Video_on 5000;
BA_REL_ "GenSigTimeoutTime" BU_SG_REL_ ZR_MIB_TOP_ab_Gen3 SG_ 2463978734 VPS_PaCo_CurrentVideoState 1000;
BA_REL_ "GenSigTimeoutTime" BU_SG_REL_ ZR_MIB_TOP_ab_Gen3 SG_ 873 SDF2_Pos_Inhibitzeit 800;
BA_REL_ "GenSigTimeoutTime" BU_SG_REL_ ZR_MIB_TOP_ab_Gen3 SG_ 873 SDF2_Pos_Segment_ID 800;
BA_REL_ "GenSigTimeoutTime" BU_SG_REL_ ZR_MIB_TOP_ab_Gen3 SG_ 873 SDF2_Pos_Offset 800;
BA_REL_ "GenSigTimeoutTime" BU_SG_REL_ ZR_MIB_TOP_ab_Gen3 SG_ 873 SDF2_Pos_Standort_Eindeutig 800;
BA_REL_ "GenSigTimeoutTime" BU_SG_REL_ ZR_MIB_TOP_ab_Gen3 SG_ 873 SDF2_Pos_Distanz_Rampe_rechts 800;
BA_REL_ "GenSigTimeoutTime" BU_SG_REL_ ZR_MIB_TOP_ab_Gen3 SG_ 873 SDF2_Pos_Spurtype 800;
BA_REL_ "GenSigTimeoutTime" BU_SG_REL_ ZR_MIB_TOP_ab_Gen3 SG_ 873 SDF2_Pos_Distanz_Rampe_links 800;
BA_REL_ "GenSigTimeoutTime" BU_SG_REL_ ZR_MIB_TOP_ab_Gen3 SG_ 873 SDF2_Pos_AnzRampenRechts 800;
BA_REL_ "GenSigTimeoutTime" BU_SG_REL_ ZR_MIB_TOP_ab_Gen3 SG_ 873 SDF2_Pos_AnzRampenLinks 800;
BA_REL_ "GenSigTimeoutTime" BU_SG_REL_ ZR_MIB_TOP_ab_Gen3 SG_ 873 SDF2_Pos_Fehler_Laengsrichtung 800;
BA_REL_ "GenSigTimeoutTime" BU_SG_REL_ ZR_MIB_TOP_ab_Gen3 SG_ 873 SDF2_Pos_AnzHauptspuren 800;
BA_REL_ "GenSigTimeoutTime" BU_SG_REL_ ZR_MIB_TOP_ab_Gen3 SG_ 873 SDF2_Pos_Spurnummer 800;
BA_REL_ "GenSigTimeoutTime" BU_SG_REL_ ZR_MIB_TOP_ab_Gen3 SG_ 873 SDF2_Pos_GueteZuordnung 800;
BA_REL_ "GenSigTimeoutTime" BU_SG_REL_ ZR_MIB_TOP_ab_Gen3 SG_ 1167 SK1_MUX 1000;
BA_REL_ "GenSigTimeoutTime" BU_SG_REL_ ZR_MIB_TOP_ab_Gen3 SG_ 1167 SK1_Key_Data_1 1000;
BA_REL_ "GenSigTimeoutTime" BU_SG_REL_ ZR_MIB_TOP_ab_Gen3 SG_ 1167 SK1_Key_Data_2 1000;
BA_REL_ "GenSigTimeoutTime" BU_SG_REL_ ZR_MIB_TOP_ab_Gen3 SG_ 1167 SK1_Key_Data_3 1000;
BA_REL_ "GenSigTimeoutTime" BU_SG_REL_ ZR_MIB_TOP_ab_Gen3 SG_ 1167 SK1_Key_Data_4 1000;
BA_REL_ "GenSigTimeoutTime" BU_SG_REL_ ZR_MIB_TOP_ab_Gen3 SG_ 1167 SK1_Key_Data_5 1000;
BA_REL_ "GenSigTimeoutTime" BU_SG_REL_ ZR_MIB_TOP_ab_Gen3 SG_ 1167 SK1_Key_Data_6 1000;
BA_REL_ "GenSigTimeoutTime" BU_SG_REL_ ZR_MIB_TOP_ab_Gen3 SG_ 1167 SK1_Key_Data_7 1000;
BA_REL_ "GenSigTimeoutTime" BU_SG_REL_ ZR_MIB_TOP_ab_Gen3 SG_ 1167 SK1_Key_Data_8 1000;
BA_REL_ "GenSigTimeoutTime" BU_SG_REL_ ZR_MIB_TOP_ab_Gen3 SG_ 1167 SK1_Key_Data_9 1000;
BA_REL_ "GenSigTimeoutTime" BU_SG_REL_ ZR_MIB_TOP_ab_Gen3 SG_ 980 BH_Blinker_li 5000;
BA_REL_ "GenSigTimeoutTime" BU_SG_REL_ ZR_MIB_TOP_ab_Gen3 SG_ 980 BH_Blinker_re 5000;
BA_REL_ "GenSigTimeoutTime" BU_SG_REL_ ZR_MIB_TOP_ab_Gen3 SG_ 673 ASW_Ton_Richtung_VL 2000;
BA_REL_ "GenSigTimeoutTime" BU_SG_REL_ ZR_MIB_TOP_ab_Gen3 SG_ 673 ASW_Ton_Richtung_VR 2000;
BA_REL_ "GenSigTimeoutTime" BU_SG_REL_ ZR_MIB_TOP_ab_Gen3 SG_ 673 ASW_Ton_Richtung_HL 2000;
BA_REL_ "GenSigTimeoutTime" BU_SG_REL_ ZR_MIB_TOP_ab_Gen3 SG_ 673 ASW_Ton_Richtung_HR 2000;
BA_REL_ "GenSigTimeoutTime" BU_SG_REL_ ZR_MIB_TOP_ab_Gen3 SG_ 1413 SI_P_Mode_gueltig 5000;
BA_REL_ "GenSigTimeoutTime" BU_SG_REL_ ZR_MIB_TOP_ab_Gen3 SG_ 1413 SI_QRS_Mode 5000;
BA_REL_ "GenSigTimeoutTime" BU_SG_REL_ ZR_MIB_TOP_ab_Gen3 SG_ 1413 SI_T_Mode 5000;
BA_REL_ "GenSigTimeoutTime" BU_SG_REL_ ZR_MIB_TOP_ab_Gen3 SG_ 1413 SI_NWDF 5000;
BA_REL_ "GenSigTimeoutTime" BU_SG_REL_ ZR_MIB_TOP_ab_Gen3 SG_ 1413 SI_NWDF_gueltig 5000;
BA_REL_ "GenSigTimeoutTime" BU_SG_REL_ ZR_MIB_TOP_ab_Gen3 SG_ 1413 SI_T_Schutz 5000;
BA_REL_ "GenSigTimeoutTime" BU_SG_REL_ ZR_MIB_TOP_ab_Gen3 SG_ 1413 SI_P_Mode 5000;
BA_REL_ "GenSigTimeoutTime" BU_SG_REL_ ZR_MIB_TOP_ab_Gen3 SG_ 1413 SI_BUS_01 5000;
BA_REL_ "GenSigTimeoutTime" BU_SG_REL_ ZR_MIB_TOP_ab_Gen3 SG_ 1413 SI_BUS_02 5000;
BA_REL_ "GenSigTimeoutTime" BU_SG_REL_ ZR_MIB_TOP_ab_Gen3 SG_ 1413 SI_BUS_03 5000;
BA_REL_ "GenSigTimeoutTime" BU_SG_REL_ ZR_MIB_TOP_ab_Gen3 SG_ 1413 SI_BUS_04 5000;
BA_REL_ "GenSigTimeoutTime" BU_SG_REL_ ZR_MIB_TOP_ab_Gen3 SG_ 1413 SI_BUS_05 5000;
BA_REL_ "GenSigTimeoutTime" BU_SG_REL_ ZR_MIB_TOP_ab_Gen3 SG_ 1413 SI_BUS_06 5000;
BA_REL_ "GenSigTimeoutTime" BU_SG_REL_ ZR_MIB_TOP_ab_Gen3 SG_ 1413 SI_BUS_07 5000;
BA_REL_ "GenSigTimeoutTime" BU_SG_REL_ ZR_MIB_TOP_ab_Gen3 SG_ 1413 SI_BUS_08 5000;
BA_REL_ "GenSigTimeoutTime" BU_SG_REL_ ZR_MIB_TOP_ab_Gen3 SG_ 1413 SI_BUS_09 5000;
BA_REL_ "GenSigTimeoutTime" BU_SG_REL_ ZR_MIB_TOP_ab_Gen3 SG_ 1413 SI_BUS_10 5000;
BA_REL_ "GenSigTimeoutTime" BU_SG_REL_ ZR_MIB_TOP_ab_Gen3 SG_ 1413 SI_BUS_12 5000;
BA_REL_ "GenSigTimeoutTime" BU_SG_REL_ ZR_MIB_TOP_ab_Gen3 SG_ 1413 SI_BUS_13 5000;
BA_REL_ "GenSigTimeoutTime" BU_SG_REL_ ZR_MIB_TOP_ab_Gen3 SG_ 1413 SI_BUS_14 5000;
BA_REL_ "GenSigTimeoutTime" BU_SG_REL_ ZR_MIB_TOP_ab_Gen3 SG_ 1413 SI_Bus_Identifikation 5000;
BA_REL_ "GenSigTimeoutTime" BU_SG_REL_ ZR_MIB_TOP_ab_Gen3 SG_ 1413 SI_CAB_V14 5000;
BA_REL_ "GenSigTimeoutTime" BU_SG_REL_ ZR_MIB_TOP_ab_Gen3 SG_ 977 BT_Tuer_geoeffnet 1000;
BA_REL_ "GenSigTimeoutTime" BU_SG_REL_ ZR_MIB_TOP_ab_Gen3 SG_ 977 BT_FH_Oeffnung 1000;
BA_REL_ "GenSigTimeoutTime" BU_SG_REL_ ZR_MIB_TOP_ab_Gen3 SG_ 976 FT_Tuer_geoeffnet 1000;
BA_REL_ "GenSigTimeoutTime" BU_SG_REL_ ZR_MIB_TOP_ab_Gen3 SG_ 976 FT_FH_Oeffnung 1000;
BA_REL_ "GenSigTimeoutTime" BU_SG_REL_ ZR_MIB_TOP_ab_Gen3 SG_ 976 FT_Kisi_li_aktiv 1000;
BA_REL_ "GenSigTimeoutTime" BU_SG_REL_ ZR_MIB_TOP_ab_Gen3 SG_ 976 FT_Kisi_re_aktiv 1000;
VAL_ 1529 RDK_FMVSS138_Lampe 0 "RDK_WaLa_inaktiv" 1 "RDK_WaLa_aktiv" ;
VAL_ 1529 RDK_FMVSS138_MIL 0 "keine_Stoerungsanzeige" 1 "Stoerungsanzeige" ;
VAL_ 1529 RDK_Kalibrierung 0 "BAP_Kalibrierung" 1 "CAN_Kombitaster_Kalibrierung" ;
VAL_ 1529 RDK_Reifendruck_Lampe 0 "RDK_WaLa_inaktiv" 1 "RDK_WaLa_aktiv" ;
VAL_ 1529 RDK_Warnungen_02 0 "keine_Anzeige" 1 "Reifen_allgemein_Warnstufe_1" 2 "Reifen_vorne_links_Warnstufe_1" 3 "Reifen_vorne_rechts_Warnstufe_1" 4 "Reifen_hinten_links_Warnstufe_1" 5 "Reifen_hinten_rechts_Warnstufe_1" 6 "Reifen_allgemein_Warnstufe_2" 7 "Reifen_vorne_links_Warnstufe_2" 8 "Reifen_vorne_rechts_Warnstufe_2" 9 "Reifen_hinten_links_Warnstufe_2" 10 "Reifen_hinten_rechts_Warnstufe_2" 11 "Reifen_allgemein_Warnstufe_3" 12 "Reifen_vorne_links_Warnstufe_3" 13 "Reifen_vorne_rechts_Warnstufe_3" 14 "Reifen_hinten_links_Warnstufe_3" 15 "Reifen_hinten_rechts_Warnstufe_3" 16 "Akustikausgabe_Kalibrierung_io" 17 "Textausgabe_Kalibrierung_io" 18 "Akustik_Textausgabe_Kalibrier_io" 19 "RDK_aktiviert" 20 "RDK_deaktiviert" 21 "RDK_Systemstoerung" 22 "RDK_Systemstoerung_temporaer" 23 "V_Warnschwelle_1" 24 "V_Warnschwelle_2" 25 "Radwechsel_allgemein" 26 "Teilueberwachung" 27 "V_Warnschwelle_3" 28 "V_Warnschwelle_4" 29 "V_Warnschwelle_5" 30 "Reifendruecke_kalibrieren" ;
VAL_ 1529 RDK_angelernt 0 "nicht_angelernt" 1 "angelernt" ;
VAL_ 1529 RDK_Reifentemperatur_Lampe 0 "RDK_WaLa_inaktiv" 1 "RDK_WaLa_aktiv" ;
VAL_ 1529 RDK_RS_aktiv 0 "inaktiv" 1 "aktiv" ;
VAL_ 1529 RDK_Text_7 0 "inaktiv" 1 "aktiv" ;
VAL_ 1529 RDK_W_1_Reifen_HL 0 "inaktiv" 1 "aktiv" ;
VAL_ 1529 RDK_W_1_Reifen_HR 0 "inaktiv" 1 "aktiv" ;
VAL_ 1529 RDK_W_1_Reifen_VL 0 "inaktiv" 1 "aktiv" ;
VAL_ 1529 RDK_W_1_Reifen_VR 0 "inaktiv" 1 "aktiv" ;
VAL_ 1529 RDK_W_2_Reifen_HL 0 "inaktiv" 1 "aktiv" ;
VAL_ 1529 RDK_W_2_Reifen_HR 0 "inaktiv" 1 "aktiv" ;
VAL_ 1529 RDK_W_2_Reifen_VL 0 "inaktiv" 1 "aktiv" ;
VAL_ 1529 RDK_W_2_Reifen_VR 0 "inaktiv" 1 "aktiv" ;
VAL_ 1711 RV_Video_on 0 "Kamerabild wird nicht angezeigt" 1 "Kamerabild wird angezeigt" ;
VAL_ 1711 RV_Dark_Screen 0 "Kamerabild nicht verdunkeln" 1 "Kamerabild verdunkeln" ;
VAL_ 1711 RV_HMI_Mode 0 "Parkluecke  (Modus 1)" 1 "Parallel zur Straße (Modus 2)" 2 "reserviert" 3 "Kalibrierung (nur Diagnose)" ;
VAL_ 1711 RV_GL_side 0 "Guidelines_abgeschaltet" 1 "Guidelines_Anzeige_rechte_Seite" 2 "Guiedelines_Anzeige_linke_Seite" 3 "Guiedelines_Anzeige_beide_Seiten" ;
VAL_ 1711 RV_System_aktiv 0 "System nicht betriebsbereit" 1 "System betriebsbereit" ;
VAL_ 1711 RV_Reinigung_Anf 0 "nicht_reinigen" 1 "reinigen" ;
VAL_ 1711 RV_Settings_enabled 0 "Menu 'Einstellungen' nicht aktiviert" 1 "Menu 'Einstellungen' aktiviert" ;
VAL_ 1711 RV_Menu_Item 0 "HMI Mode als ausgewaehlt markiert" 1 "Helligkeit als ausgewaehlt markiert" 2 "Kontrast als ausgewaehlt markiert" 3 "Farbsaettigung als ausgewaehlt markiert" ;
VAL_ 1711 SV_Video_on 0 "SideView_aus_/_nicht_verbaut" 1 "SideView_an" ;
VAL_ 1711 RV_Calib_Fehler 0 "Kalibrierung_i.O." 1 "RearView_nicht_kalibriert" ;
VAL_ 1711 RV_GL_Trailer_connect 0 "Guidelines_werden_angezeigt" 1 "Guidelines_wegen_angekoppeltem_Anhänger_deaktiviert" ;
VAL_ 1711 RV_GL_Trunk_open 0 "Guidelines_werden_angezeigt" 1 "Guidelines_wegen_geöffneter_Heckklappe_deaktiviert" ;
VAL_ 1711 RV_GL_LWS_Fehler 0 "Guidelines_werden_angezeigt" 1 "Guidelines_wegen_nicht_kalibriertem_Lenkwinkelsensor_deaktiviert" ;
VAL_ 1711 ZFAS_Umfeldbeleuchtung_Anf 0 "nicht_angefordert" 1 "angefordert" ;
VAL_ 2463978734 SLCV_PaCo_MainState 0 "Init" 1 "InOperation_NoError" 7 "Fehler" ;
VAL_ 2463978734 SLCV_PaCo_CurrentView 0 "NoView" 1 "SLCV_Both" 2 "SLCV_Left" 3 "SLCV_Right" ;
VAL_ 2463978734 VPS_PaCo_CurrentCarOverlay 0 "noCarOverlay" 1 "normalCarOverlay" 2 "transparentCarOverlay" ;
VAL_ 2463978734 VPS_PaCo_CurrentBowl 0 "NoBowl" 1 "Preset_1" 2 "Preset_2" 3 "Preset_3" 4 "Preset_4" 5 "Preset_5" 6 "Preset_6" 7 "Preset_7" 8 "Preset_8" 9 "Preset_9" 10 "Modified" 11 "Preset_AWC" 12 "Preset_IPA" 13 "Preset_ParkingFront" 14 "Preset_ParkingRear" 15 "Preset_RPA" 16 "Preset_CarWash" ;
VAL_ 2463978734 VPS_PaCo_CurrGraphOverlay 0 "NoGraphic" 1 "IPA" 2 "ARA" 3 "AAA" 4 "TrailerAssist" 5 "AR" 6 "AWC" 7 "Parkbox" 8 "CarWash" 9 "RPA" 10 "TPA_Training" 11 "TPA_AutomatedDriving" 12 "TPA_Remote" 13 "legal" ;
VAL_ 2463978734 VPS_PaCo_CurrentRVCscreen 0 "NoScreen" 1 "Fullscreen" 2 "SidebySide_Splitscreen" ;
VAL_ 2463978734 VPS_PaCo_CurrentBirdview 0 "NoBirdView" 1 "BirdView_2D" 2 "BirdView_3D" 3 "BirdView_Autoakt" 4 "OPS_only" 5 "TPA_Trajectory" ;
VAL_ 2463978734 VPS_PaCo_CurrentMode 0 "NoMode" 1 "Parking_Manual" 2 "Parking_Automatic" 3 "Crossing" 4 "BumperFocus" 5 "TrailerAssist_Manual" 6 "SV_Focus_Front" 7 "SV_Focus_Rear" 8 "SV_Focus_All" 9 "Legal" 10 "TrailerAssist_AAA" 11 "TrailerAssist_ARA" 12 "Smartphone" 13 "VirtualView" 14 "BumperFocus_AWC" ;
VAL_ 2463978734 VPS_PaCo_CurrentView 0 "NoView" 1 "RearView" 2 "FrontView" 3 "SV_Left" 4 "SV_Right" 5 "SV_Both" 6 "BirdView_2D" 7 "BirdView_3D" 8 "VirtualView" ;
VAL_ 2463978734 VPS_PaCo_MainState 0 "Init" 1 "InOperation_NoError" 7 "Fehler" ;
VAL_ 2463978734 VPS_PaCo_CurrentVideoState 0 "Inactive_ImageNotPossible" 1 "Inactive_ImagePossible" 2 "Active_ImageNotPossible" 3 "Active_ImagePossible" 4 "Active_ACA_recording" ;
VAL_ 2463978734 VPS_PaCo_Button 0 "Init_or_not_equipped" 1 "Button_not_pressed" 2 "Button_pressed_debounced" 3 "Error" ;
VAL_ 1527 RW_Tendenz 0 "keine_Tendenz" 1 "konstant" 2 "steigend" 3 "sinkend" ;
VAL_ 1527 RW_Texte 0 "kein_Text" 1 "Text_1" 2 "Text_2" 3 "Text_3" ;
VAL_ 1527 RW_Reservewarnung_aktiv 0 "inaktiv" 1 "aktiv" ;
VAL_ 1527 RW_Reichweite_Einheit_Anzeige 0 "km" 1 "miles" ;
VAL_ 1527 RW_Gesamt_Reichweite_Anzeige 2045 "nicht_verbaut" 2046 "Init" 2047 "Fehler" ;
VAL_ 1527 RW_Primaer_Reichweite_Anzeige 2045 "nicht_verbaut" 2046 "Init" 2047 "Fehler" ;
VAL_ 1527 RW_Sekundaer_Reichweite_Anzeige 2045 "nicht_verbaut" 2046 "Init" 2047 "Fehler" ;
VAL_ 1527 RW_Sekundaer_Reichweite 2045 "nicht_verbaut" 2046 "Init" 2047 "Fehler" ;
VAL_ 1527 RW_Sek_Reichweitenv_Einheit 0 "Liter_pro_100km" 1 "kWh_pro_100km" 2 "Kg_pro_100km" 3 "nicht_verbaut" ;
VAL_ 1527 RW_Sek_Reichweitenverbrauch 2047 "Init" ;
VAL_ 1610 RKA_FMVSS138_Lampe 0 "keine Warnung" 1 "Warnlampe FMVSS 138, gelbe Lampe statisch an" ;
VAL_ 1610 RKA_Warnungen_02 0 "keine_Anzeige" 1 "Kontrollleuchte" 2 "Systemfehler" 3 "Reifen_allgemein_Warnstufe_1" 4 "Reifen_vorne_links_Warnstufe_1" 5 "Reifen_vorne_rechts_Warnstufe_1" 6 "Reifen_hinten_links_Warnstufe_1" 7 "Reifen_hinten_rechts_Warnstufe_1" 8 "Reifen_allgemein_Warnstufe_2" 9 "Reifen_vorne_links_Warnstufe_2" 10 "Reifen_vorne_rechts_Warnstufe_2" 11 "Reifen_hinten_links_Warnstufe_2" 12 "Reifen_hinten_rechts_Warnstufe_2" 13 "Reifen_allgemein_Warnstufe_3" 14 "Reifen_vorne_links_Warnstufe_3" 15 "Reifen_vorne_rechts_Warnstufe_3" 16 "Reifen_hinten_links_Warnstufe_3" 17 "Reifen_hinten_rechts_Warnstufe_3" 18 "Reifendruecke_kalibrieren" 19 "Akustik" 20 "Systemfehler_Lampe_Text" 21 "Reifen_allgemein_Lampe_Text" 22 "Reifen_vorne_links_Lampe_Text" 23 "Reifen_vorne_rechts_Lampe_Text" 24 "Reifen_hinten_links_Lampe_Text" 25 "Reifen_hinten_rechts_Lampe_Text" 26 "Reifendruecke_kalibrieren_Text_Gong" 27 "Reifendruecke_kalibrieren_Text_Gong_Lampe" 28 "Reifenwechsel_erkannt" ;
VAL_ 1610 RKA_Reifentyp 0 "Init" 1 "Winter" 2 "Sommer" 3 "Ganzjahresreifen" 4 "Kundenspezifisch" ;
VAL_ 1440 LS_Helligkeit_IR 254 "Init" 255 "Fehler" ;
VAL_ 1440 LS_Helligkeit_FW 1022 "Init" 1023 "Fehler" ;
VAL_ 1440 LS_defekt 0 "OK" 1 "defekt" ;
VAL_ 1440 LS_Verbau 0 "Init" 1 "Lichtsensor_verbaut" ;
VAL_ 1440 RS_Regenmenge 0 "0" 1 "0,0_bis_0,3" 2 "0,31_bis_1,4" 3 "1,41_bis_2,0" 4 "2,01_bis_2,8" 5 "2,81_bis_3,3" 6 "3,31_bis_4,0" 7 "4,01_bis_5,0" 8 "5,01_bis_7,0" 9 "7,01_bis_9,0" 10 "9,01_bis_11,0" 11 "11,01_bis_15,0" 12 "15,01_bis_22,0" 13 ">22,01" 14 "Init" 15 "Fehler" ;
VAL_ 1440 RS_Schwall 0 "Aus" 1 "Ein" ;
VAL_ 1440 RS_Verbau 0 "Init" 1 "Regensensor verbaut" ;
VAL_ 1440 RS_Verglasung_schliessen 0 "Verglasung nicht schliessen" 1 "Verglasung schliessen" ;
VAL_ 1440 RS_defekt 0 "OK" 1 "defekt" ;
VAL_ 1440 RS_Wischergeschwindigkeit 0 "kein Wischen" 1 "42 Huebe/min" 2 "45 Huebe/min" 3 "48 Huebe/min" 4 "51 Huebe/min" 5 "54 Huebe/min" 6 "57 Huebe/min" 7 "60 Huebe/min" ;
VAL_ 1440 RLS_Vorfeldhelligkeit_Boost 0 "groesser_24413_Lux" 1 "bis_24413_Lux" 2 "bis_22193_Lux" 3 "bis_20176_Lux" 4 "bis_18342_Lux" 5 "bis_16647_Lux" 6 "bis_15158_Lux" 7 "bis_13780_Lux" 8 "bis_12527_Lux" 9 "bis_11388_Lux" 10 "bis_10353_Lux" 11 "bis_9412_Lux" 12 "bis_8556_Lux" 13 "bis_7778_Lux" 14 "bis_7071_Lux" 15 "bis_6428_Lux" ;
VAL_ 1440 SLS_Helligkeit_IR 254 "Init" 255 "Fehler" ;
VAL_ 1504 MD1_Position 126 "Init" 127 "nicht_normiert" ;
VAL_ 1504 MD1_Lage 0 "Ausstelllage" 1 "Schiebelage" ;
VAL_ 1504 MD3_Lage 0 "Ausstelllage" 1 "Schiebelage" ;
VAL_ 1504 MRollo_Position 126 "Init" 127 "nicht_normiert" ;
VAL_ 1504 MRollo_Lage 0 "Ausstelllage" 1 "Schiebelage" ;
VAL_ 1504 SAD_normiert 0 "inaktiv" 1 "aktiv" ;
VAL_ 1504 SAD_Thermoschutz 0 "inaktiv" 1 "aktiv" ;
VAL_ 1504 SAD_UEKB_aktiv 0 "inaktiv" 1 "aktiv" ;
VAL_ 1504 Rollo_normiert 0 "inaktiv" 1 "aktiv" ;
VAL_ 1504 Rollo_Thermoschutz 0 "inaktiv" 1 "aktiv" ;
VAL_ 1504 Rollo_UEKB_aktiv 0 "inaktiv" 1 "aktiv" ;
VAL_ 1504 SAD_Taster_Deckel_hi 0 "nicht_betaetigt" 1 "man_sl_zu" 2 "auto_sl_zu" 3 "man_sl_auf" 4 "auto_sl_auf" 5 "man_al_auf" 6 "auto_al_auf" 7 "man_al_zu" 8 "auto_al_zu" 14 "fehler_schalter_haengt" 15 "fehler_schalter_unplausibel" ;
VAL_ 1504 SAD_Taster_Deckel_vo 0 "nicht_betaetigt" 1 "man_sl_zu" 2 "auto_sl_zu" 3 "man_sl_auf" 4 "auto_sl_auf" 5 "man_al_auf" 6 "auto_al_auf" 7 "man_al_zu" 8 "auto_al_zu" 14 "fehler_schalter_haengt" 15 "fehler_schalter_unplausibel" ;
VAL_ 1504 SAD_Taster_Rollo_hi 0 "nicht_betaetigt" 1 "man_zu" 2 "auto_zu" 3 "man_auf" 4 "auto_auf" 6 "fehler_schalter_haengt" 7 "fehler_schalter_unplausibel" ;
VAL_ 1504 SAD_Taster_Rollo_vo 0 "nicht_betaetigt" 1 "man_zu" 2 "auto_zu" 3 "man_auf" 4 "auto_auf" 6 "fehler_schalter_haengt" 7 "fehler_schalter_unplausibel" ;
VAL_ 1504 SAD_Anf_ESC_Zuschaltung 0 "inaktiv" 1 "aktiv" ;
VAL_ 2463978605 SCode_Target 0 "Init" ;
VAL_ 2463978605 SCode_Data 0 "Init" ;
VAL_ 873 SDF2_Pos_Segment_ID 0 "KeineSegmentinformation" 1 "Fehlerwert" ;
VAL_ 873 SDF2_Pos_Standort_Eindeutig 0 "mehrdeutiger_Standort" 1 "eindeutiger_Standort" ;
VAL_ 873 SDF2_Pos_Distanz_Rampe_rechts 62 "keine" 63 "Init" ;
VAL_ 873 SDF2_Pos_Spurtype 0 "Hauptspur" 1 "Ausfahrt_Rampe_links" 2 "Ausfahrt_Rampe_rechts" 3 "HOV_Spur" 4 "Expressspur" 5 "Nur_Ausfahrt_links" 6 "Nur_Ausfahrt_rechts" 7 "Kombinierte_Ausfahrt_links" 8 "Kombinierte_Ausfahrt_rechts" 9 "Nur_Auffahrt_links" 10 "Nur_Auffahrt_rechts" 11 "Kombinierte_Auffahrt_links" 12 "Kombinierte_Auffahrt_rechts" 13 "Auffahrt_Rampe_links" 14 "Auffahrt_Rampe_rechts" 30 "Unbekannt" 31 "Init" ;
VAL_ 873 SDF2_Pos_Distanz_Rampe_links 62 "keine" 63 "Init" ;
VAL_ 873 SDF2_Pos_AnzRampenRechts 7 "Init" ;
VAL_ 873 SDF2_Pos_AnzRampenLinks 7 "Init" ;
VAL_ 873 SDF2_Pos_Fehler_Laengsrichtung 0 "Init" 1 "kleiner_2m" 2 "kleiner_5m" 3 "kleiner_10m" 4 "kleiner_20m" 5 "kleiner_50m" 6 "groesser_50m" 7 "offroad" ;
VAL_ 873 SDF2_Pos_AnzHauptspuren 15 "Init" ;
VAL_ 873 SDF2_Pos_Spurnummer 0 "Spur_minus_5" 1 "Spur_minus_4" 2 "Spur_minus_3" 3 "Spur_minus_2" 4 "Spur_minus_1" 5 "Standstreifen" 6 "Spur_1" 7 "Spur_2" 8 "Spur_3" 9 "Spur_4" 10 "Spur_5" 11 "Spur_6" 12 "Spur_7" 13 "Spur_8" 14 "Spur_9" 15 "Init" ;
VAL_ 873 SDF2_Pos_GueteZuordnung 15 "Init" ;
VAL_ 1167 SK1_Key_Data_10 0 "Init" ;
VAL_ 1363 SR3_Status_Lehne_Links 0 "nicht_entriegelt" 1 "entriegelt" ;
VAL_ 1363 SR3_Status_Lehne_Rechts 0 "nicht_entriegelt" 1 "entriegelt" ;
VAL_ 1363 SR3_Fahrpos_HBFS_erzeugen 0 "nicht_betaetigt" 1 "betaetigt" ;
VAL_ 1363 SR3_Fahrpos_HFS_erzeugen 0 "nicht_betaetigt" 1 "betaetigt" ;
VAL_ 1363 SR3_Fahrpos_HFS_HBFS_erzeugen 0 "nicht_betaetigt" 1 "betaetigt" ;
VAL_ 1363 SR3_Fahrposition_links 0 "init" 1 "Ladeboden_links" 2 "Fahrposition_links" 3 "Fehler" ;
VAL_ 1363 SR3_Fahrposition_rechts 0 "init" 1 "Ladeboden_rechts" 2 "Fahrposition_rechts" 3 "Fehler" ;
VAL_ 1363 SR3_Entriegl_Motor_li 0 "init" 1 "offen_innen" 2 "offen_aussen" 3 "offen_beide" 4 "geschlossen_innen" 5 "geschlossen_aussen" 6 "geschlossen_beide" 7 "Fehler" ;
VAL_ 1363 SR3_Entriegl_Motor_re 0 "init" 1 "offen_innen" 2 "offen_aussen" 3 "offen_beide" 4 "geschlossen_innen" 5 "geschlossen_aussen" 6 "geschlossen_beide" 7 "Fehler" ;
VAL_ 1363 SR3_Ladeboden_HBFS_erzeugen 0 "nicht_betaetigt" 1 "betaetigt" ;
VAL_ 1363 SR3_Ladeboden_HBFS_HFS_erzeugen 0 "nicht_betaetigt" 1 "betaetigt" ;
VAL_ 1363 SR3_Ladeboden_HFS_erzeugen 0 "nicht_betaetigt" 1 "betaetigt" ;
VAL_ 1363 SR3_Verriegelungssensor_li 0 "init" 1 "offen" 2 "geschlossen_innen" 3 "geschlossen_aussen" 4 "geschlossen_beide" 5 "Fehler" ;
VAL_ 1363 SR3_Verriegelungssensor_re 0 "init" 1 "offen" 2 "geschlossen_innen" 3 "geschlossen_aussen" 4 "geschlossen_beide" 5 "Fehler" ;
VAL_ 980 BH_Blinker_li 0 "nicht_betaetigt" 1 "Blinkerhebel_Pos_li_betaetigt" ;
VAL_ 980 BH_Blinker_re 0 "nicht_betaetigt" 1 "Blinkerhebel_Pos_re_betaetigt" ;
VAL_ 980 BH_Lichthupe 0 "nicht_betaetigt" 1 "Blinkerhebel in Richtung Lichthupe betaetigt" ;
VAL_ 980 BH_Fernlicht 0 "nicht_betaetigt" 1 "Blinkerhebel_in_Richtung_Fernlicht_betaetigt" ;
VAL_ 980 WH_Tipwischen 0 "nicht_betaetigt" 1 "betaetigt" ;
VAL_ 980 WH_Intervall 0 "aus" 1 "Wischerhebel in Stellung Intervall" ;
VAL_ 980 WH_WischerStufe1 0 "aus" 1 "Wischerhebel in Stufe Wischen 1" ;
VAL_ 980 WH_WischerStufe2 0 "aus" 1 "Wischerhebel in Stufe Wischen 2" ;
VAL_ 980 WH_Frontwaschen 0 "aus" 1 "Wischerhebel in Stellung Wisch Wasch vorne" ;
VAL_ 980 WH_Heckintervall 0 "nicht_betaetigt" 1 "Wischerhebel in Stellung Heckintervall" ;
VAL_ 980 WH_Heckwaschen 0 "nicht_betaetigt" 1 "Wischerhebel in Stellung Wisch Wasch hinten" ;
VAL_ 980 WH_Intervallstufen 0 "Init / Default" 1 "Intervallstufe 1" 5 "Intervallstufe 2" 9 "Intervallstufe 3" 13 "Intervallstufe 4" 15 "Fehler" ;
VAL_ 980 FAS_Taster 0 "nicht_betaetigt" 1 "betaetigt" ;
VAL_ 980 FAS_Taster_Fehler 0 "kein_Fehler" 1 "Fehler" ;
VAL_ 980 SMLS_Hupe 0 "nicht_betaetigt" 1 "Hupe_gedrueckt" ;
VAL_ 980 LRH_On_Off 0 "LRH_aus__keine Anzeige" 1 "LRH_aus" 2 "LRH_ein" 3 "Fehler" ;
VAL_ 980 LSS_Tastencode 0 "Key_Released__No_Key" 4 "Up" 5 "Down" 7 "OK__ThumbWheel_Button" ;
VAL_ 980 LRH_aktiv 0 "inaktiv" 1 "aktiv" ;
VAL_ 980 SMLS_P_verriegelt 0 "Init" 1 "nicht_verriegelt" 2 "verriegelt" 3 "Fehler" ;
VAL_ 980 SMLS_P_verriegelt_plausibel 0 "unplausibel" 1 "plausibel" ;
VAL_ 980 WH_SRA 0 "SRA_Aus" 1 "SRA_Ein" ;
VAL_ 980 WH_Wischer_Fehler 0 "kein_Fehler" 1 "Fehler" ;
VAL_ 980 BH_Blinker_Fehler 0 "kein_Fehler" 1 "Fehler" ;
VAL_ 980 SMLS_PTT 0 "nicht_betaetigt" 1 "PTT_gedrueckt" ;
VAL_ 980 WH_Tipwischen_lang 0 "nicht_betaetigt" 1 "betaetigt" ;
VAL_ 2589283756 SOK_ungeschuetzte_Zeit 0 "Init" ;
VAL_ 1467 SoSe_SunInt_2D_Li 254 "Init" 255 "Fehler" ;
VAL_ 1467 SoSe_SunInt_2D_Re 254 "Init" 255 "Fehler" ;
VAL_ 1313 STH_Funk_ein 0 "kein Funkbefehl zum Einschalten" 1 "Funkbefehl zum Einschalten erhalten" ;
VAL_ 1313 STH_Funk_aus 0 "kein Funkbefehl" 1 "Funkbefehl zum Ausschalten erhalten" ;
VAL_ 1313 STH_Zusatzheizung 0 "Zuheizer aus" 1 "Zuheizer ein" ;
VAL_ 1313 STH_LED 0 "keine Rückmeldung" 1 "Rueckmeldung Standheizung in Betrieb" ;
VAL_ 1313 STH_Geblaese 0 "kein Einschaltbefehl an die Klimaanlage, Gebläse" 1 "Einschaltbefehl an die Klimaanlage, Gebläse" ;
VAL_ 1313 STH_EKP_Anst 0 "EKP nicht ansteuern" 1 "EKP ansteuern" ;
VAL_ 1313 STH_Start_folgt 0 "kein_Start_folgt" 1 "Start_folgt" ;
VAL_ 1313 STH_Ventil_Status 0 "Ventil_offen__grosser_Kreislauf" 1 "Ventil_geschlossen__kleiner_Kreislauf" ;
VAL_ 1313 STH_Fehler_ElWaPu 0 "kein_Fehler" 1 "Fehler" ;
VAL_ 1313 STH_Pumpen_Anf_extern 0 "nicht_angefordert" 1 "angefordert" ;
VAL_ 1313 STH_KL_HUP 0 "Aus" 1 "Ein" ;
VAL_ 1313 STH_Fehlerstatus 0 "kein_Fehler" 1 "Unterspannung" 2 "Tankfuellstand_zu_gering" 3 "Fehler_Betrieb_verhindert" 4 "Heizgeraet_verriegelt" 5 "Fehler_Betrieb_nicht_verhindert" 6 "Emissionsüberschreitung" ;
VAL_ 1313 STH_Wassertemp 254 "Init" 255 "Fehler" ;
VAL_ 1313 STH_Texte 0 "keine_Anzeige" 1 "Batteriemanagementeinschraenkung" 2 "Kraftstoffmangel" 3 "interner_Systemfehler" 4 "Heizzeitueberschreitung" ;
VAL_ 1313 STH_Motorvorwaermung 0 "keine Motorvorwärmung erfolgt" 1 "Aufheizung mit Motorvorwärmung erfolgt" ;
VAL_ 1313 STH_Servicemode 0 "Servicemode nicht aktiv" 1 "Servicemode aktiv" ;
VAL_ 1313 STH_war_aktiv 0 "war inaktiv" 1 "Standheizung war letzte halbe Stunde aktiv" ;
VAL_ 1313 STH_KVS_Ueberlauf 0 "kein Überlauf" 1 "Kraftstoffverbrauchssignal, mindestens ein Überlauf hat stattgefunden" ;
VAL_ 1313 STH_SH_ZH 0 "Heizgeraet_WZH" 1 "Heizgeraet_ZH" ;
VAL_ 673 SWA_LED_Hell_BFS 126 "Init" 127 "Fehler" ;
VAL_ 673 SWA_LED_Hell_FS 126 "Init" 127 "Fehler" ;
VAL_ 673 SWA_LED_Ausgabemodus_BFS 0 "LED_aus" 1 "Infostufe" 2 "Warnstufe" 3 "Aufpruefen_SWAABAHeck_ASW" 4 "Aufpruefen_SWAABAHeck" 5 "Demolauf" ;
VAL_ 673 SWA_LED_Ausgabemodus_FS 0 "LED_aus" 1 "Infostufe" 2 "Warnstufe" 3 "Aufpruefen_SWAABAHeck_ASW" 4 "Aufpruefen_SWAABAHeck" 5 "Demolauf" ;
VAL_ 673 SWA_Status 0 "aus" 1 "passiv" 2 "aktiv" 3 "Fehler" ;
VAL_ 673 ASW_Ton_Richtung_VL 0 "kein_Warnton" 1 "Warnton" ;
VAL_ 673 ASW_Ton_Richtung_VR 0 "kein_Warnton" 1 "Warnton" ;
VAL_ 673 ASW_Ton_Richtung_HL 0 "kein_Warnton" 1 "Warnton" ;
VAL_ 673 ASW_Ton_Richtung_HR 0 "kein_Warnton" 1 "Warnton" ;
VAL_ 673 SWA_Status_System 0 "aus" 1 "passiv" 2 "aktiv" 3 "Fehler" ;
VAL_ 673 SWA_Brightness_Mode_FPM 0 "Init" 1 "No_error" 2 "Trailer_active" 3 "Muted_by_driver" 4 "Blind" 5 "not_selectable" 6 "not_available" 7 "Privacy_Mode" 8 "No_License" 9 "License_expired" 14 "Temporary_error" 15 "Fehler" ;
VAL_ 673 SWA_Status_KuFu 0 "aus" 1 "passiv" 2 "aktiv" 3 "Fehler" ;
VAL_ 673 SWA_Infostufe_Assist_li 0 "keine_Infostufe" 1 "Infostufe_aktiv" ;
VAL_ 673 SWA_Infostufe_Assist_re 0 "keine_Infostufe" 1 "Infostufe_aktiv" ;
VAL_ 673 SWA_Warnstufe_Assist_li 0 "keine_Warnstufe" 1 "Warnstufe_aktiv" ;
VAL_ 673 SWA_Warnstufe_Assist_re 0 "keine_Warnstufe" 1 "Warnstufe_aktiv" ;
VAL_ 673 SWA_Modus_System 0 "nicht_verfuegbar" 1 "verfuegbar" 2 "Anhaengerbetrieb" 3 "eingeschraenkte_Sensorsicht" 4 "keine_Sensorsicht" 5 "reserved" 6 "temporaerer_Fehler" 7 "dauerhafter_Fehler" ;
VAL_ 673 SWA_Kombiausgabe 0 "Keine_Anzeige" 1 "zur_Zeit_nicht_verfuegbar" 2 "Systemfehler" 3 "Sensor_blockiert" 4 "Anhaengerbetrb_nicht_verfuegbar" 5 "Sensor_teilweise_blockiert" ;
VAL_ 673 ASW_Kombiausgabe 0 "Keine_Anzeige" 1 "zur_Zeit_nicht_verfuegbar" 2 "Systemfehler" 3 "Sensor_blockiert" 4 "Anhaengerbetrb_nicht_verfuegbar" ;
VAL_ 673 SWA_Kombiwarnung 0 "Keine_Warnung" 1 "Akustik_Warnung" ;
VAL_ 1413 SI_Sammel_SG_Fehler 61 "Reserviert" 62 "Overflow" 63 "ungueltig" ;
VAL_ 1413 SI_P_Mode_gueltig 0 "dezentraler_Produktionsmode" 1 "zentraler_Produktionsmode" ;
VAL_ 1413 SI_Diagnose_Aktiv 0 "inaktiv" 1 "aktiv" ;
VAL_ 1413 SI_QRS_Mode 0 "QRS_Messmodus_nicht_aktiv" 1 "QRS_Messmodus_aktiv" ;
VAL_ 1413 SI_T_Mode 0 "Transportmodus_nicht_aktiv" 1 "Transportmodus_aktiv" ;
VAL_ 1413 SI_NWDF 0 "Ueberwachung_nicht_freigegeben" 1 "Ueberwachung_freigegeben" ;
VAL_ 1413 SI_NWDF_gueltig 0 "NWDF_wird_nicht_unterstuetzt" 1 "NWDF_wird_unterstuetzt" ;
VAL_ 1413 SI_Sammelfehler 0 "kein_Sammelfehler" 1 "Sammelfehler" ;
VAL_ 1413 GW_KD_Fehler 0 "kein_KD_Fehler" 1 "KD_Fehler" ;
VAL_ 1413 SI_T_Schutz 0 "Transportschutz_nicht_aktiv" 1 "Transportschutz_aktiv" ;
VAL_ 1413 SI_P_Mode 0 "inaktiv" 1 "aktiv" ;
VAL_ 1413 SI_BUS_01 0 "keine_Busruhe" 1 "Busruhe" ;
VAL_ 1413 SI_BUS_02 0 "keine_Busruhe" 1 "Busruhe" ;
VAL_ 1413 SI_BUS_03 0 "keine_Busruhe" 1 "Busruhe" ;
VAL_ 1413 SI_BUS_04 0 "keine_Busruhe" 1 "Busruhe" ;
VAL_ 1413 SI_BUS_05 0 "keine_Busruhe" 1 "Busruhe" ;
VAL_ 1413 SI_BUS_06 0 "keine_Busruhe" 1 "Busruhe" ;
VAL_ 1413 SI_BUS_07 0 "keine_Busruhe" 1 "Busruhe" ;
VAL_ 1413 SI_BUS_08 0 "keine_Busruhe" 1 "Busruhe" ;
VAL_ 1413 SI_BUS_09 0 "keine_Busruhe" 1 "Busruhe" ;
VAL_ 1413 SI_BUS_10 0 "keine_Busruhe" 1 "Busruhe" ;
VAL_ 1413 SI_BUS_11 0 "keine_Busruhe" 1 "Busruhe" ;
VAL_ 1413 SI_BUS_12 0 "keine_Busruhe" 1 "Busruhe" ;
VAL_ 1413 SI_BUS_13 0 "keine_Busruhe" 1 "Busruhe" ;
VAL_ 1413 SI_BUS_14 0 "keine_Busruhe" 1 "Busruhe" ;
VAL_ 1413 SI_BUS_15 0 "keine_Busruhe" 1 "Busruhe" ;
VAL_ 1413 SI_NWDF_30 0 "Ueberwachung_nicht_freigegeben" 1 "Ueberwachung_freigegeben" ;
VAL_ 1413 SI_Bus_Identifikation 16 "CAN_Diagnose" 17 "CAN_Antrieb" 18 "CAN_Komfort" 19 "CAN_Infotainment" 20 "CAN_Fahrwerk" 21 "CAN_Extended" 22 "CAN_Hybrid" 23 "CAN_Lade" 24 "CAN_Kombi" 25 "CAN_Komfort_2" 26 "CAN_AFS" 27 "CAN_MIB" 28 "CAN_Batterie_BMC" 29 "CAN_Motor" 31 "CAN_Airbag_Sicherheitssysteme" 33 "CAN_FahrerAssistenzSysteme" 34 "CAN_Migration" 35 "CAN_Connect" 36 "CAN_AnzeigeBedienung" 37 "CAN_ElectricalVehicle" 40 "CAN_Telematik" 41 "CAN_MFL" 42 "CAN_FahrerAssistenzSysteme_2" 43 "CAN_FahrerAssistenzSysteme_3" 47 "CAN_Komfort_3" 48 "FlexRay_A" 49 "FlexRay_B" 97 "VLAN_FAS" 98 "VLAN_Infotainment" 99 "VLAN_Connect" 100 "VLAN_Komfort" 101 "VLAN_Antrieb" 102 "VLAN_Diagnose" 103 "VLAN_Internet" 104 "VLAN_Gateway" 105 "VLAN_Remote_FC" 106 "VLAN_Connect_2" 107 "VLAN_Licht" 108 "VLAN_Charge" 109 "VLAN_Cockpit" 110 "VLAN_Connect_3" 111 "VLAN_IoT" 112 "VLAN_CarPerformance" 113 "VLAN_ConMod" 114 "VLAN_FAS2" 176 "HCP1_CANFD01" 177 "HCP1_CANFD02" 178 "HCP1_CANFD03" 179 "HCP1_CANFD04" 180 "HCP1_CANFD05" 181 "HCP1_CANFD06" 182 "HCP1_CANFD07" 183 "HCP1_CANFD08" 186 "HCP4_CANFD03" 187 "HCP4_CANFD04" 188 "HCP1_CANFD09" 189 "HCP4_CANFD06" 190 "HCP4_CANFD07" 191 "HCP4_CANFD08" 192 "HCP4_CANFD09" 193 "HCP4_CANFD10" 194 "HCP1_CANFD10" 195 "ICAS1_CANFD2_HCP5_CANFD02" 196 "HCP1_CANFD11" 197 "WU_HCP1_CANFD" 199 "WU_HCP2_CANFD" 200 "WU_HCP3_CANFD" 201 "WU_HCP4_CANFD" 202 "HCP3_CANFD02" 204 "ESC_CANFD" 205 "HCP4_CANFD11" 206 "HCP4_CANFD12" 207 "CAN_Innenraumsensorik" 212 "WU_ConMod_CANFD" 213 "WU_PASD_CANFD" 215 "CAN_MobileDeviceKey" 217 "CAN_Tuerantrieb_VL" 218 "CAN_Tuerantrieb_VR" 219 "CAN_Tuerantrieb_HL" 220 "CAN_Tuerantrieb_HR" ;
VAL_ 1413 SI_CAB_V14 0 "Init" 1 "CAB_01_Antrieb" 2 "CAB_02_Hybrid_Laden" 4 "CAB_03_Fahrwerk" 8 "CAB_04_Fahrerassistenz" 16 "CAB_05_Komfort" 32 "CAB_06_Anzeige" 64 "CAB_07_Connect" 128 "CAB_08_MIB" 256 "CAB_09_Standheizung" 1024 "CAB_11_VLAN_Fahrerassistenz" 2048 "CAB_12_VLAN_Komfort" 4096 "CAB_13_VLAN_Connect" 8192 "CAB_14_VLAN_Infotainment" 16384 "CAB_15_Laden" 32768 "CAB_16_Licht" ;
VAL_ 1637 TF_Telephone_State 0 "idle" 1 "not_active" 2 "Call_active" 3 "eCall_active" 4 "not_available" 5 "reserved" 6 "reserved" 7 "reserved" ;
VAL_ 1637 TF_Mute_Msg_Code 0 "Phonecall" 1 "Speech Recognition active" 2 "Emergency Call" 3 "beep-signal" 4 "Operator Call" 5 "Ring" 6 "Phonecall wideband" 7 "Stereo Audio (source mobile)" ;
VAL_ 1637 TF_Phone_Status 0 "idle_state" 1 "incoming_call" 2 "waiting_call" 3 "active_call" 4 "outgoing_call" ;
VAL_ 1637 TF_BT_ConnectionState 0 "keine_Verbindung" 1 "Verbindung" ;
VAL_ 2589283622 TLO_LSA1_Zeit1_Pred 0 "Init" ;
VAL_ 2589283622 TLO_LSA1_Zeit1_Status 0 "UNAVAILABLE" 1 "STOP_THEN_PROCEED" 2 "STOP_AND_REMAIN" 3 "PRE_MOVEMENT" 4 "PERMISSIVE_MOVEMENT_ALLOWED" 5 "PROTECTED_MOVEMENT_ALLOWED" 6 "PERMISSIVE_CLEARANCE" 7 "PROTECTED_CLEARANCE" 8 "CAUTION_CONFLICTING_TRAFFIC" ;
VAL_ 2589283622 TLO_LSA1_Zeit2_Pred 0 "Init" ;
VAL_ 2589283622 TLO_LSA1_Zeit2_Status 0 "UNAVAILABLE" 1 "STOP_THEN_PROCEED" 2 "STOP_AND_REMAIN" 3 "PRE_MOVEMENT" 4 "PERMISSIVE_MOVEMENT_ALLOWED" 5 "PROTECTED_MOVEMENT_ALLOWED" 6 "PERMISSIVE_CLEARANCE" 7 "PROTECTED_CLEARANCE" 8 "CAUTION_CONFLICTING_TRAFFIC" ;
VAL_ 2589283622 TLO_HMI_Status 0 "Init" 1 "Active__Funktion_Verbindung_iO" 2 "Standby_Normal_Mode__Warten_auf_neue_Daten" 3 "SwitchedOff__Durch_Fahrer_deaktiviert" 4 "FilteredOut__Nicht_angezeigter_Hinweis" 5 "ActiveFunktionVerbindung_iO_A_Gl" 6 "ActiveFunktionVerbindung_iO_A_Tg" ;
VAL_ 2589283622 TLO_LSA1_PSD_Segment_ID 0 "Init" ;
VAL_ 2589283622 TLO_StartStoppInfo 0 "Motorlauf_nicht_notwendig_(Stoppfreigabe)" 1 "Motoranlauf_nicht_zwingend_notwendig_(Stoppverbot,keine_Startanforderung)" 2 "Motoranlauf_zwingend_notwendig_(Startanforderung)" 3 "Systemfehler" ;
VAL_ 2589283622 TLO_LSA1_PSD_Seg_Offset 255 "Init" ;
VAL_ 2589283623 TLO_LSA2_Zeit1_Pred 0 "Init" ;
VAL_ 2589283623 TLO_LSA2_Zeit1_Status 0 "UNAVAILABLE" 1 "STOP_THEN_PROCEED" 2 "STOP_AND_REMAIN" 3 "PRE_MOVEMENT" 4 "PERMISSIVE_MOVEMENT_ALLOWED" 5 "PROTECTED_MOVEMENT_ALLOWED" 6 "PERMISSIVE_CLEARANCE" 7 "PROTECTED_CLEARANCE" 8 "CAUTION_CONFLICTING_TRAFFIC" ;
VAL_ 2589283623 TLO_LSA2_Zeit2_Pred 0 "Init" ;
VAL_ 2589283623 TLO_LSA2_Zeit2_Status 0 "UNAVAILABLE" 1 "STOP_THEN_PROCEED" 2 "STOP_AND_REMAIN" 3 "PRE_MOVEMENT" 4 "PERMISSIVE_MOVEMENT_ALLOWED" 5 "PROTECTED_MOVEMENT_ALLOWED" 6 "PERMISSIVE_CLEARANCE" 7 "PROTECTED_CLEARANCE" 8 "CAUTION_CONFLICTING_TRAFFIC" ;
VAL_ 2589283623 TLO_LSA1_Layout 0 "vertical_layout_red_top" 1 "horizontal_layout_red_left" 2 "horizontal_layout_red_right" 3 "reserved" ;
VAL_ 2589283623 TLO_LSA2_PSD_Segment_ID 0 "Init" ;
VAL_ 2589283623 TLO_LSA2_PSD_Seg_Offset 255 "Init" ;
VAL_ 1447 ORU_KombiTimer 0 "ORU_Inaktiv" 1 "ORU_Start" ;
VAL_ 1447 MOD_Energie_Anf 0 "Keine_Anforderung" 1 "Anforderung_NV" 2 "Anforderung_HV_Nutzung_Erlaubt" 3 "Fehler" ;
VAL_ 1447 FaceRec_Enroll_Challenge_Request 0 "SEND_NOTHING" 1 "SEND_CHALLENGE" ;
VAL_ 1447 eCall_Mute_Anf 0 "kein_mute" 1 "mute" ;
VAL_ 1447 FoD_Anz_Funktionsabschaltung 0 "Init" 1 "Popup_aufschalten" ;
VAL_ 1447 iCall_active 0 "inaktiv" 1 "aktiv" ;
VAL_ 1447 bCall_active 0 "bcall_inactive" 1 "bcall_active" ;
VAL_ 1447 MOD_Request_ServiceKey 0 "Init" 1 "Aktuallisierungsanfrage" ;
VAL_ 1447 eCall_Funktionsstatus_02 0 "kein_Fehler" 1 "Manueller_Notruf_aktiv" 2 "Automatischer_Notruf_aktiv" 7 "Init" ;
VAL_ 1447 eCall_Funktionsstatus 0 "kein_Fehler" 1 "Fkt_eingeschraenkt" 2 "Fkt_eingeschraenkt_service" 3 "Fkt_nicht_verfuegbar" 4 "Fkt_Service" 5 "Fkt_deaktiviert" 6 "Fkt_aktiviert" 7 "init" ;
VAL_ 1447 TM_Spiegel_Anklappen 0 "Init" 1 "Spiegel_anklappen" ;
VAL_ 1447 TM_Nur_Hupen 0 "inaktiv" 1 "aktiv" ;
VAL_ 1447 TM_Door_Lock 0 "Init" 1 "door_lock" ;
VAL_ 1447 TM_Door_Unlock 0 "Init" 1 "door_unlock" ;
VAL_ 1447 TM_Warnblinken 0 "Init" 1 "Warnblinken_on" ;
VAL_ 1447 TM_Panik_Alarm 0 "Init" 1 "panik_alarm_on" ;
VAL_ 1447 TM_ZV_Signatur 0 "Init" ;
VAL_ 977 BT_Tuer_geoeffnet 0 "geschlossen" 1 "offen" ;
VAL_ 977 BT_verriegelt 0 "Init" 1 "verriegelt" ;
VAL_ 977 BT_gesafet 0 "Init" 1 "gesafet" ;
VAL_ 977 BT_Schluesselschalter_auf 0 "Init" 1 "Schluesselschalter_auf_betaetigt" ;
VAL_ 977 BT_Schluesselschalter_zu 0 "Init" 1 "Schluesselschalter_zu_betaetigt" ;
VAL_ 977 BT_Unlock_Taster 0 "Init" 1 "Unlock_Taster_betaetigt" ;
VAL_ 977 BT_Lock_Taster 0 "Init" 1 "Lock_Taster_betaetigt" ;
VAL_ 977 BT_Sperrklinke 0 "Schloss_in_Vorraste_und_Hauptraste" 1 "Tuer_auf_oder_Tuer_Position_zwischen_Vor_und_Hauptraste" ;
VAL_ 977 BT_TAG_betaetigt 0 "Init" 1 "Tuerinnengriff_betaetigt" ;
VAL_ 977 BT_TIG_betaetigt 0 "Init" 1 "Tuerinnengriff_betaetigt" ;
VAL_ 977 BT_Tuer_Status 0 "Init" 1 "Tuer_geschlossen" 2 "Tuer_offen" 3 "Fehler" ;
VAL_ 977 BT_TSG_hinten_verbaut 0 "nicht verbaut" 1 "verbaut" ;
VAL_ 977 BT_Sp_Blk_def 0 "iO" 1 "Spiegel_Blinker_defekt" ;
VAL_ 977 BT_FH_S_ManHoch 0 "Init" 1 "FH_Schalter_man_hoch_gedrueckt" ;
VAL_ 977 BT_FH_S_AutoHoch 0 "Init" 1 "FH_Schalter_auto_hoch_gedrueckt" ;
VAL_ 977 BT_FH_S_ManTief 0 "Init" 1 "FH_Schalter_man_tief_gedrueckt" ;
VAL_ 977 BT_FH_S_AutoTief 0 "Init" 1 "FH_Schalter_auto_tief_gedrueckt" ;
VAL_ 977 BT_FH_Bew_hoch 0 "Init" 1 "FH_ist_in_Bewegung_hoch" ;
VAL_ 977 BT_FH_Bew_tief 0 "Init" 1 "FH_ist_in_Bewegung_tief" ;
VAL_ 977 BT_FH_Fang 0 "ausserhalb_Fangbereich" 1 "innerhalb_Fangbereich" ;
VAL_ 977 BT_FH_Block 0 "Init" 1 "Fensterheber_Block" ;
VAL_ 977 BT_FH_Thermo 0 "Init" 1 "Thermoschutz_aktiv" ;
VAL_ 977 BT_UEKB_aktiviert 0 "Init" 1 "aktiv" ;
VAL_ 977 BT_Kisi_Fehler 0 "kein_Fehler" 1 "Fehler" ;
VAL_ 977 BT_FH_normiert 0 "Init" 1 "Fenster_normiert" ;
VAL_ 977 BT_Schliesstaster 0 "nicht_betaetigt" 1 "betaetigt" ;
VAL_ 977 BT_Zuziehhilfe_aktiv 0 "Init" 1 "Zuziehhilfe_aktiv" ;
VAL_ 977 BT_SP_ausgerastet 0 "Init" 1 "Spiegel_ausgerastet" ;
VAL_ 977 BT_SP_lr_aktiv 0 "Init" 1 "Spiegel_xAchse_aktiv" ;
VAL_ 977 BT_SP_ht_aktiv 0 "Init" 1 "Spiegel_yAchse_aktiv" ;
VAL_ 977 BT_SP_Heizung_aktiv 0 "BF_Spiegelheizung_aus" 1 "BF_Spiegelheizung_ein" ;
VAL_ 977 BT_Oben_Block_erw 0 "Fensterheber_nicht_in_Blockerwar" 1 "Fensterheber_in_Blockerwartung_o" ;
VAL_ 977 BT_Unten_Block_erw 0 "Fensterheber_nicht_in_Blockerwar" 1 "Fensterheber_in_Blockerwartung_u" ;
VAL_ 977 BT_Tuer_Status_QBit 0 "Status_Tuerkontakt_sicher" 1 "Status_Tuerkontakt_unsicher" ;
VAL_ 977 BFS_Status_eTAG 0 "Init" 1 "Griff_ausgefahren" 2 "Griff_eingefahren" 3 "Fehler" ;
VAL_ 977 BT_TCR_Mode_aktiv 0 "TCR_Mode_deaktiv" 1 "TCR_Mode_aktiv" ;
VAL_ 977 BT_Lock_Unlock_Taster 0 "nicht_betaetigt" 1 "betaetigt" ;
VAL_ 977 BT_SP_Heizung_Status 0 "Init" 1 "Status_Spiegelheizung_ein" ;
VAL_ 977 ASW_Warnung_aktiv_BFS 0 "nicht_angefordert" 1 "angefordert" ;
VAL_ 977 BT_FH_Pos_oben 1 "Scheibe oben (nach Absenken auf Position) " ;
VAL_ 977 BT_Tuerschloss_defekt 0 "Tuerschloss_funktionsfaehig" 1 "Tuerschloss_defekt" ;
VAL_ 977 BT_Tueroeffnen_Warnung 0 "Tuerwarnung_nicht_aktiv" 1 "Tuerwarnung_aktiv" ;
VAL_ 977 BT_Lock_Taster_inv 0 "Lock Taster betätigt" 1 "Lock Taster nicht betätigt" ;
VAL_ 977 BT_Schluesselschalter_zu_inv 0 "Schlüsselschalter betätigt" 1 "Schlüsselschalter nicht betätigt" ;
VAL_ 977 BT_SWA_HMI_defekt 0 "SWA_kein_Fehler" 1 "SWA_Fehler" ;
VAL_ 977 BT_ASW_HMI_defekt 0 "ASW_kein_Fehler" 1 "ASW_Fehler" ;
VAL_ 976 FT_Tuer_geoeffnet 0 "geschlossen" 1 "Tuer_offen" ;
VAL_ 976 FT_verriegelt 0 "Init" 1 "verriegelt" ;
VAL_ 976 FT_gesafet 0 "Init" 1 "gesafet" ;
VAL_ 976 FT_Schluesselschalter_auf 0 "Init" 1 "Schluesselschalter_auf_betaetigt" ;
VAL_ 976 FT_Schluesselschalter_zu 1 "Schluesselschalter zu betaetigt" ;
VAL_ 976 FT_Unlock_Taster 0 "Init" 1 "Unlock_Taster_betaetigt" ;
VAL_ 976 FT_Lock_Taster 0 "Init" 1 "Lock_Taster_betaetigt" ;
VAL_ 976 FT_Sperrklinke 0 "Schloss_in_Vorraste_und_Hauptraste" 1 "Tuer_auf_oder_Tuer_Position_zwischen_Vor_und_Hauptraste" ;
VAL_ 976 FT_TAG_betaetigt 0 "nicht_betaetigt" 1 "betaetigt" ;
VAL_ 976 FT_TIG_betaetigt 0 "nicht_betaetigt" 1 "betaetigt" ;
VAL_ 976 FT_IRUE_Taste 0 "Init" 1 "IRUE_Taste_betaetigt" ;
VAL_ 976 FT_HD_Taste 0 "nicht_betaetigt" 1 "Heckdeckeltaste_betaetigt" ;
VAL_ 976 FT_TD_Taste_Fehler 0 "iO" 1 "defekt" ;
VAL_ 976 FT_TD_Taste 0 "Init" 1 "Tankdeckel_Taster_betaetigt" ;
VAL_ 976 SSR_Temp_Freigabe 0 "SSR_Deaktiviert" 1 "SSR_Freigegeben" ;
VAL_ 976 FT_HD_Taste_2 0 "Taste_nicht_gedrueckt" 1 "Taste_gedrueckt" ;
VAL_ 976 FT_Lock_Unlock_Taster 0 "nicht_betaetigt" 1 "betaetigt" ;
VAL_ 976 FT_TSG_hinten_verbaut 0 "nicht verbaut" 1 "verbaut" ;
VAL_ 976 FT_Sp_Blk_def 0 "iO" 1 "defekt" ;
VAL_ 976 FT_FH_S_ManHoch 0 "Init" 1 "FH_Schalter_man_hoch_betaetigt" ;
VAL_ 976 FT_FH_S_AutoHoch 0 "Init" 1 "FH_Schalter_auto_hoch_betaetigt" ;
VAL_ 976 FT_FH_S_ManTief 0 "Init" 1 "FH_Schalter_man_tief_betaetigt" ;
VAL_ 976 FT_FH_S_AutoTief 0 "Init" 1 "FH_Schalter_auto_tief_betaetigt" ;
VAL_ 976 FT_FH_Bew_hoch 0 "Init" 1 "FH_in_Bewegung_hoch" ;
VAL_ 976 FT_FH_Bew_tief 0 "Init" 1 "FH_in_Bewegung_tief" ;
VAL_ 976 FT_FH_Fang 0 "ausserhalb_Fangbereich" 1 "innerhalb_Fangbereich" ;
VAL_ 976 FT_FH_Block 0 "Init" 1 "Fenster_Block" ;
VAL_ 976 FT_FH_Thermo 0 "Init" 1 "Thermoschutz_aktiv" ;
VAL_ 976 FT_UEKB_aktiviert 0 "Init" 1 "UEKB_aktiv" ;
VAL_ 976 ASW_HMI_defekt 0 "iO" 1 "defekt" ;
VAL_ 976 FT_FH_normiert 0 "Init" 1 "Fenster_normiert" ;
VAL_ 976 FT_Schliesstaster 1 "Schliesstaster_betaetigt" ;
VAL_ 976 FT_Zuziehhilfe_aktiv 0 "Init" 1 "Zuziehilfe_aktiv" ;
VAL_ 976 FT_SP_ausgerastet 0 "Init" 1 "Spiegel_ausgerastet" ;
VAL_ 976 FT_SP_lr_aktiv 0 "Init" 1 "Spiegel_xAchse_aktiv" ;
VAL_ 976 FT_SP_ht_aktiv 0 "Init" 1 "Spiegel_yAchse_aktiv" ;
VAL_ 976 ASW_wakeup 0 "Sleep" 1 "Wakeup" ;
VAL_ 976 FT_Oben_Block_erw 0 "Fensterheber_nicht_in_Blockerwar" 1 "Fensterheber_in_Blockerwartung_o" ;
VAL_ 976 FT_Unten_Block_erw 0 "Fensterheber_nicht_in_Blockerwar" 1 "Fensterheber_in_Blockerwartung_u" ;
VAL_ 976 FT_Kisi_li_aktiv 0 "inaktiv" 1 "aktiv" ;
VAL_ 976 FT_Kisi_re_aktiv 0 "inaktiv" 1 "aktiv" ;
VAL_ 976 FT_Kisi_Taster_li 0 "nicht_betaetigt" 1 "betaetigt" ;
VAL_ 976 FT_Kisi_Taster_re 0 "nicht_betaetigt" 1 "betaetigt" ;
VAL_ 976 FT_BFS_Fond_Freigabe 0 "Init" 1 "Freigabe_fuer_Fondbedienung_BFS" ;
VAL_ 976 FT_Kisi_Fehler 0 "kein_Fehler" 1 "Fehler" ;
VAL_ 976 FT_Daemmglas 0 "Normalglas_verbaut" 1 "Daemmglas_verbaut" ;
VAL_ 976 FT_SP_Heizung_Status 0 "Init" 1 "Status_Spiegelheizung_ein" ;
VAL_ 976 ASW_Warnung_aktiv_FS 0 "nicht_angefordert" 1 "angefordert" ;
VAL_ 976 FT_FH_Pos_oben 1 "Scheibe oben (nach Absenken auf Position) " ;
VAL_ 976 FT_Tuerschloss_defekt 0 "Tuerschloss_funktionsfaehig" 1 "Tuerschloss_defekt" ;
VAL_ 976 FT_SWA_Taster 0 "Taster_nicht_betaetigt" 1 "Taster_betaetigt" ;
VAL_ 976 SWA_HMI_Diagnose 0 "kein_Fehler_erkannt" 1 "Fehler_Taster_erkannt" 2 "Fehler_LED_erkannt" 3 "Fehler_LED_und_Taster_erkannt" ;
VAL_ 976 FS_Status_eTAG 0 "Init" 1 "Griff_ausgefahren" 2 "Griff_eingefahren" 3 "Fehler" ;
VAL_ 997 FT_Tuer_Status 0 "Init" 1 "Tuer_geschlossen" 2 "Tuer_offen" 3 "Fehler" ;
VAL_ 997 FT_Tuer_Status_QBit 0 "Status_Tuerkontakt_sicher" 1 "Status_Tuerkontakt_unsicher" ;
VAL_ 997 FT_Lock_Taster_02 0 "nicht_betaetigt" 1 "betaetigt" ;
VAL_ 997 FT_Schluesselschalter_zu_02 0 "nicht_betaetigt" 1 "betaetigt" ;
VAL_ 997 FT_BFS_Tuer_Status 0 "Init" 1 "Tuer_geschlossen" 2 "Tuer_offen" 3 "Fehler" ;
VAL_ 997 FT_HBFS_Tuer_Status 0 "Init" 1 "Tuer_geschlossen" 2 "Tuer_offen" 3 "Fehler" ;
VAL_ 997 FT_HFS_Tuer_Status 0 "Init" 1 "Tuer_geschlossen" 2 "Tuer_offen" 3 "Fehler" ;
VAL_ 997 FT_Tueroeffnen_Warnung 0 "Tuerwarnung_nicht_aktiv" 1 "Tuerwarnung_aktiv" ;
VAL_ 997 FT_SP_Heizung_ein 0 "Aus" 1 "Ein" ;
VAL_ 997 FT_Kisi_Taster_li_02 0 "nicht_betaetigt" 1 "betaetigt" ;
VAL_ 997 FT_Kisi_Taster_re_02 0 "nicht_betaetigt" 1 "betaetigt" ;
VAL_ 997 FT_TD_Taste_Status 0 "kein_Fehler" 1 "Kurzschluss_nach_Minus" 2 "Kurzschluss_nach_Plus" 3 "Leitungsunterbrechung" ;
VAL_ 997 FT_TCR_Mode_aktiv 0 "TCR_Mode_deaktiv" 1 "TCR_Mode_aktiv" ;
VAL_ 997 TBF_FS_Touch_Event 0 "nicht_betaetigt" 1 "Tippen" 2 "Wischen" 3 "Geste" 4 "Doppeltippen" 5 "Longpress_1" 6 "Longpress_2" 7 "reserviert" 8 "reserviert" 9 "reserviert" 10 "reserviert" 11 "reserviert" 12 "reserviert" 13 "reserviert" 14 "reserviert" 15 "reserviert" ;
VAL_ 997 FT_KiSi_Status_Soll_HBFS 0 "inaktiv" 1 "aktiv" ;
VAL_ 997 FT_KiSi_Status_Soll_HFS 0 "inaktiv" 1 "aktiv" ;
VAL_ 997 FS_Push_Tuergriff 0 "nicht_erkannt" 1 "erkannt" ;
VAL_ 997 TSG_FS_Spiegel_angeklappt 0 "Spiegel_ausgeklappt" 1 "Spiegel_eingeklappt" ;
VAL_ 997 FT_Cargolock_bet 0 "nicht_betaetigt" 1 "betaetigt" ;
VAL_ 997 FT_kisi_asynchron 0 "nicht_aktiv" 1 "aktiv" ;
VAL_ 997 eTAB_FS_Bowdenzug_Auswerfen 0 "nicht_auswerfen" 1 "auswerfen" ;
VAL_ 997 FS_Status_eTAG_ext 0 "Griff_eingefahren" 1 "Griff_ausgefahren" 2 "Griff_verfaehrt" 3 "init" 4 "Fehler" ;
VAL_ 997 FT_ASW_Warnton 0 "kein_warnton" 1 "warnton_links" 2 "warnton_rechts" 3 "Fehler" ;
VAL_ 997 SSA_FT_ASW_Status 0 "Init" 1 "InfoStufe_aktiv" 2 "Warnstufe_aktiv" ;
